VERSION ""

NS_ :

BS_:

BU_: GW MHU IPC CCU

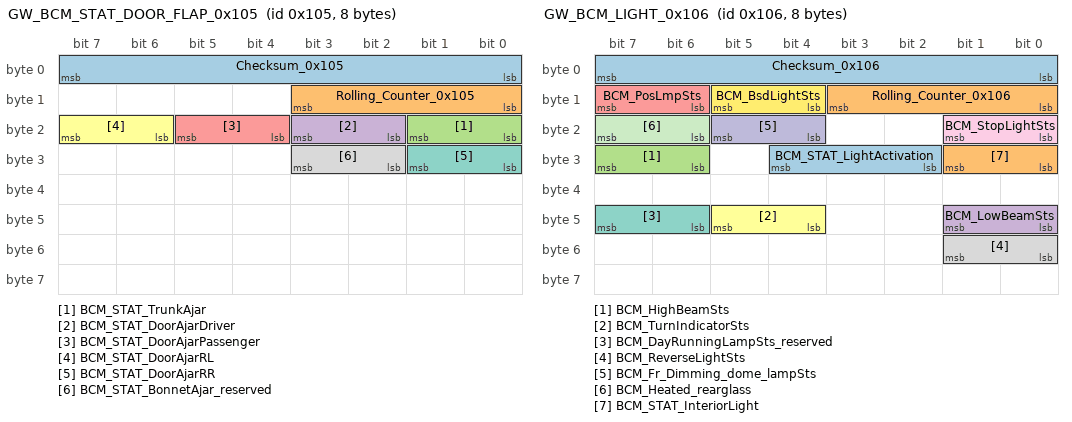
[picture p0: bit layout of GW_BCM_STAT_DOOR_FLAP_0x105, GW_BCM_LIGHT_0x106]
BO_ 261 GW_BCM_STAT_DOOR_FLAP_0x105: 8 GW
 SG_ Checksum_0x105 : 7|8@0+ (1,0) [0|255] ""  MHU,IPC
 SG_ Rolling_Counter_0x105 : 11|4@0+ (1,0) [0|15] ""  MHU,IPC
 SG_ BCM_STAT_TrunkAjar : 17|2@0+ (1,0) [0|3] "Bit"  MHU,IPC
 SG_ BCM_STAT_DoorAjarDriver : 19|2@0+ (1,0) [0|3] "Bit"  MHU,IPC
 SG_ BCM_STAT_DoorAjarPassenger : 21|2@0+ (1,0) [0|3] "Bit"  MHU,IPC
 SG_ BCM_STAT_DoorAjarRL : 23|2@0+ (1,0) [0|3] "Bit"  MHU,IPC
 SG_ BCM_STAT_DoorAjarRR : 25|2@0+ (1,0) [0|3] "Bit"  MHU,IPC
 SG_ BCM_STAT_BonnetAjar_reserved : 27|2@0+ (1,0) [0|3] "Bit"  MHU,IPC

BO_ 262 GW_BCM_LIGHT_0x106: 8 GW
 SG_ Checksum_0x106 : 7|8@0+ (1,0) [0|255] ""  MHU,IPC
 SG_ Rolling_Counter_0x106 : 11|4@0+ (1,0) [0|15] ""  MHU,IPC
 SG_ BCM_HighBeamSts : 31|2@0+ (1,0) [0|3] ""  MHU,IPC
 SG_ BCM_LowBeamSts : 41|2@0+ (1,0) [0|3] ""  MHU,IPC
 SG_ BCM_PosLmpSts : 15|2@0+ (1,0) [0|3] ""  MHU,IPC
 SG_ BCM_TurnIndicatorSts : 45|2@0+ (1,0) [0|3] ""  MHU,IPC
 SG_ BCM_DayRunningLampSts_reserved : 47|2@0+ (1,0) [0|3] ""  MHU,IPC
 SG_ BCM_ReverseLightSts : 49|2@0+ (1,0) [0|3] ""  MHU,IPC
 SG_ BCM_StopLightSts : 17|2@0+ (1,0) [0|3] ""  MHU,IPC
 SG_ BCM_Fr_Dimming_dome_lampSts : 21|2@0+ (1,0) [0|3] ""  MHU,IPC
 SG_ BCM_Heated_rearglass : 23|2@0+ (1,0) [0|3] ""  MHU
 SG_ BCM_BsdLightSts : 13|2@0+ (1,0) [0|3] ""  MHU,IPC
 SG_ BCM_STAT_LightActivation : 28|3@0+ (1,0) [0|7] ""  MHU,IPC
 SG_ BCM_STAT_InteriorLight : 25|2@0+ (1,0) [0|3] "Bit"  MHU,IPC

BO_ 266 GW_BCM_VOLTAGE_0x10a: 8 GW
 SG_ Checksum_0x10a : 7|8@0+ (1,0) [0|255] ""  MHU,IPC,CCU
 SG_ Rolling_Counter_0x10a : 11|4@0+ (1,0) [0|15] ""  MHU,IPC,CCU
 SG_ BCM_LVTop_up : 24|1@0+ (1,0) [0|1] ""  MHU
 SG_ Ubatt_Reserved : 23|14@0+ (0.001,3) [3|18] "V"  MHU,IPC,CCU

BO_ 274 GW_BCM_CLAMP_STAT_0x112: 8 GW
 SG_ Checksum_0x112 : 7|8@0+ (1,0) [0|255] ""  MHU,IPC,CCU
 SG_ Rolling_Counter_0x112 : 11|4@0+ (1,0) [0|15] ""  MHU,IPC,CCU
 SG_ STAT_Terminal : 34|3@0+ (1,0) [0|7] "Bit"  MHU,IPC,CCU
 SG_ STAT_CL30s_L_Reserved : 41|2@0+ (1,0) [0|3] "Bit"  MHU

BO_ 303 GW_BCM_TERMINAL_0x12f: 8 GW
 SG_ Checksum_0x12f : 7|8@0+ (1,0) [0|255] ""  MHU,IPC
 SG_ Rolling_Counter_0x12f : 11|4@0+ (1,0) [0|15] ""  MHU,IPC
 SG_ ST_KL_KEY_VLD : 19|4@0+ (1,0) [0|15] ""  MHU,IPC
 SG_ ST_SSP : 25|2@0+ (1,0) [0|3] ""  MHU,IPC
 SG_ BCM_IMMO_Sts : 29|2@0+ (1,0) [0|2] ""  MHU

BO_ 283 GW_BCM_Power_0x11b: 8 GW
 SG_ BCM_ACCRelayOutputSts : 3|2@0+ (1,0) [0|3] ""  MHU,IPC
 SG_ BCM_IGN1RelayOutputSts : 5|2@0+ (1,0) [0|3] ""  MHU,IPC
 SG_ BCM_ACCRelayFalutSts : 9|2@0+ (1,0) [0|3] ""  MHU,IPC
 SG_ BCM_IGN1RelayFalutSts : 11|2@0+ (1,0) [0|3] ""  MHU,IPC
 SG_ BCM_KEY_MatchSts : 15|2@0+ (1,0) [0|3] ""  MHU,IPC

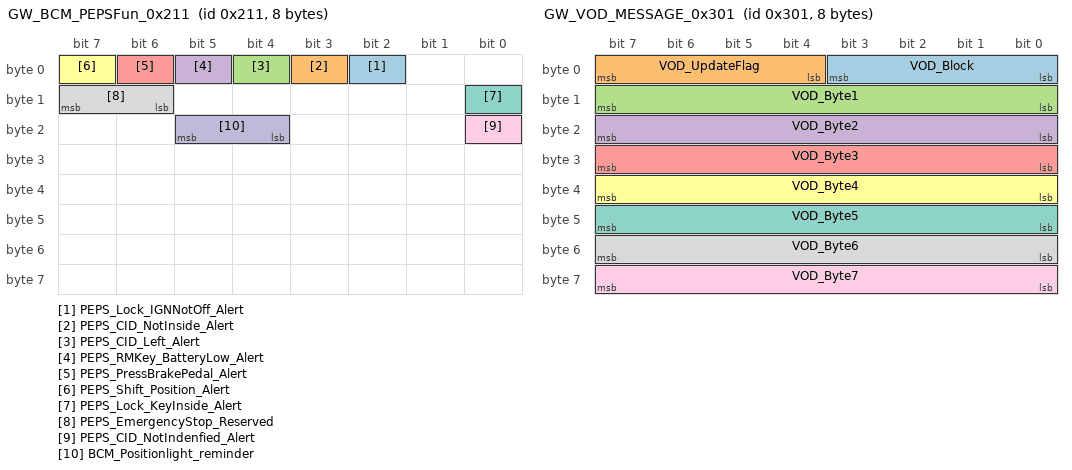
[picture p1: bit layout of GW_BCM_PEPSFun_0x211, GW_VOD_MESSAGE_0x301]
BO_ 529 GW_BCM_PEPSFun_0x211: 8 GW
 SG_ PEPS_Lock_IGNNotOff_Alert : 2|1@0+ (1,0) [0|1] ""  MHU,IPC
 SG_ PEPS_CID_NotInside_Alert : 3|1@0+ (1,0) [0|1] ""  MHU,IPC
 SG_ PEPS_CID_Left_Alert : 4|1@0+ (1,0) [0|1] ""  MHU,IPC
 SG_ PEPS_RMKey_BatteryLow_Alert : 5|1@0+ (1,0) [0|1] ""  MHU,IPC
 SG_ PEPS_PressBrakePedal_Alert : 6|1@0+ (1,0) [0|1] ""  MHU,IPC
 SG_ PEPS_Shift_Position_Alert : 7|1@0+ (1,0) [0|1] ""  MHU,IPC
 SG_ PEPS_Lock_KeyInside_Alert : 8|1@0+ (1,0) [0|1] ""  MHU,IPC
 SG_ PEPS_EmergencyStop_Reserved : 15|2@0+ (1,0) [0|3] ""  MHU,IPC
 SG_ PEPS_CID_NotIndenfied_Alert : 16|1@0+ (1,0) [0|1] ""  MHU,IPC
 SG_ BCM_Positionlight_reminder : 21|2@0+ (1,0) [0|3] ""  MHU,IPC

BO_ 270 GW_BCM_ENTRY_CONTROL_0x10e: 8 GW
 SG_ RemoteAccessKey : 7|4@0+ (1,0) [0|7] ""  MHU
 SG_ PassiveAccessTrunk : 9|2@0+ (1,0) [0|3] ""  MHU
 SG_ BCM_CurrentValid_FOB : 18|3@0+ (1,0) [0|4] ""  MHU

BO_ 769 GW_VOD_MESSAGE_0x301: 8 GW
 SG_ VOD_Block : 3|4@0+ (1,0) [0|7] ""  IPC
 SG_ VOD_UpdateFlag : 7|4@0+ (1,0) [0|7] ""  IPC
 SG_ VOD_Byte1 : 15|8@0+ (1,0) [0|255] ""  IPC
 SG_ VOD_Byte2 : 23|8@0+ (1,0) [0|255] ""  IPC
 SG_ VOD_Byte3 : 31|8@0+ (1,0) [0|255] ""  IPC
 SG_ VOD_Byte4 : 39|8@0+ (1,0) [0|255] ""  IPC
 SG_ VOD_Byte5 : 47|8@0+ (1,0) [0|255] ""  IPC
 SG_ VOD_Byte6 : 55|8@0+ (1,0) [0|255] ""  IPC
 SG_ VOD_Byte7 : 63|8@0+ (1,0) [0|255] ""  IPC

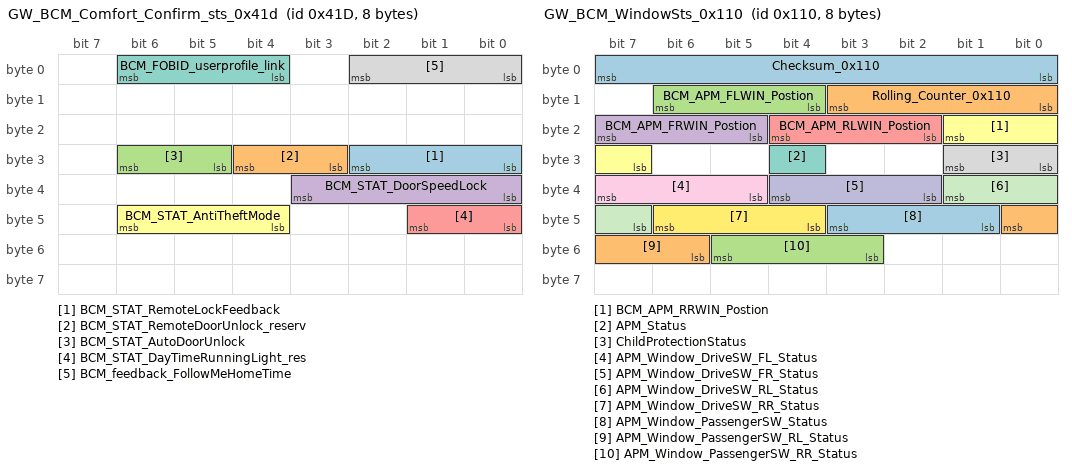
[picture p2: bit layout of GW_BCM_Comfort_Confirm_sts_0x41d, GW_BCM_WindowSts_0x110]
BO_ 1053 GW_BCM_Comfort_Confirm_sts_0x41d: 8 GW
 SG_ BCM_STAT_RemoteLockFeedback : 26|3@0+ (1,0) [0|7] ""  MHU
 SG_ BCM_STAT_RemoteDoorUnlock_reserv : 28|2@0+ (1,0) [0|3] ""  MHU
 SG_ BCM_STAT_AutoDoorUnlock : 30|2@0+ (1,0) [0|3] ""  MHU
 SG_ BCM_STAT_DoorSpeedLock : 35|4@0+ (1,0) [0|7] ""  MHU
 SG_ BCM_STAT_DayTimeRunningLight_res : 41|2@0+ (1,0) [0|3] ""  MHU
 SG_ BCM_STAT_AntiTheftMode : 46|3@0+ (1,0) [0|7] ""  MHU
 SG_ BCM_FOBID_userprofile_link : 6|3@0+ (1,0) [0|7] ""  MHU
 SG_ BCM_feedback_FollowMeHomeTime : 2|3@0+ (1,0) [0|7] ""  MHU

BO_ 263 GW_BCM_STAT_CENTRAL_LOCK_0x107: 8 GW
 SG_ Checksum_0x107 : 7|8@0+ (1,0) [0|255] "" Vector__XXX
 SG_ Rolling_Counter_0x107 : 11|4@0+ (1,0) [0|15] "" Vector__XXX
 SG_ STAT_ATWS : 20|3@0+ (1,0) [0|7] "Bit"  MHU
 SG_ STAT_DoorLockDriver : 23|2@0+ (1,0) [0|3] "Bit"  MHU

BO_ 268 GW_BCM_RemoteCtrlSts_0x10C: 8 GW
 SG_ Checksum_0x10C : 7|8@0+ (1,0) [0|255] ""  MHU
 SG_ Rolling_Counter_0x10C : 11|4@0+ (1,0) [0|15] ""  MHU
 SG_ BCM_TboxAuthStatus : 13|2@0+ (1,0) [0|2] ""  MHU
 SG_ BCM_RandomNum32bit : 39|32@0+ (1,0) [0|4294967295] ""  MHU

BO_ 272 GW_BCM_WindowSts_0x110: 8 GW
 SG_ Checksum_0x110 : 7|8@0+ (1,0) [0|255] ""  MHU
 SG_ Rolling_Counter_0x110 : 11|4@0+ (1,0) [0|14] ""  MHU
 SG_ BCM_APM_FLWIN_Postion : 14|3@0+ (1,0) [0|6] ""  MHU
 SG_ BCM_APM_FRWIN_Postion : 23|3@0+ (1,0) [0|6] ""  MHU
 SG_ BCM_APM_RLWIN_Postion : 20|3@0+ (1,0) [0|6] ""  MHU
 SG_ BCM_APM_RRWIN_Postion : 17|3@0+ (1,0) [0|6] ""  MHU
 SG_ APM_Status : 28|1@0+ (1,0) [0|1] ""  MHU
 SG_ ChildProtectionStatus : 25|2@0+ (1,0) [0|3] ""  MHU
 SG_ APM_Window_DriveSW_FL_Status : 39|3@0+ (1,0) [0|6] ""  MHU
 SG_ APM_Window_DriveSW_FR_Status : 36|3@0+ (1,0) [0|6] ""  MHU
 SG_ APM_Window_DriveSW_RL_Status : 33|3@0+ (1,0) [0|6] ""  MHU
 SG_ APM_Window_DriveSW_RR_Status : 46|3@0+ (1,0) [0|6] ""  MHU
 SG_ APM_Window_PassengerSW_Status : 43|3@0+ (1,0) [0|6] ""  MHU
 SG_ APM_Window_PassengerSW_RL_Status : 40|3@0+ (1,0) [0|6] ""  MHU
 SG_ APM_Window_PassengerSW_RR_Status : 53|3@0+ (1,0) [0|6] ""  MHU

BO_ 525 GW_BCM_ODO_0x20D: 8 GW
 SG_ Checksum_0x20D : 7|8@0+ (1,0) [0|255] ""  MHU,IPC
 SG_ Rolling_Counter_0x20D : 11|4@0+ (1,0) [0|15] ""  MHU,IPC
 SG_ BCM_ODO : 31|20@0+ (1,0) [0|999999] "km"  MHU,IPC

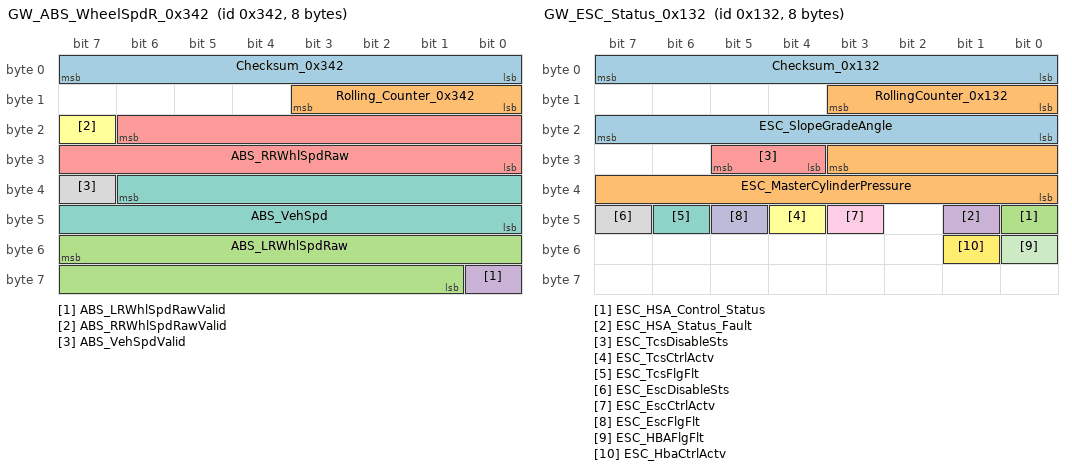
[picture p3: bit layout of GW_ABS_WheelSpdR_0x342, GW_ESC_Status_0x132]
BO_ 834 GW_ABS_WheelSpdR_0x342: 8 GW
 SG_ Checksum_0x342 : 7|8@0+ (1,0) [0|255] ""  MHU,IPC,CCU
 SG_ Rolling_Counter_0x342 : 11|4@0+ (1,0) [0|15] ""  MHU,IPC,CCU
 SG_ ABS_LRWhlSpdRaw : 55|15@0+ (0.01,0) [0|327.66] "kph" Vector__XXX
 SG_ ABS_LRWhlSpdRawValid : 56|1@0+ (1,0) [0|1] "" Vector__XXX
 SG_ ABS_RRWhlSpdRaw : 22|15@0+ (0.01,0) [0|327.66] "kph" Vector__XXX
 SG_ ABS_RRWhlSpdRawValid : 23|1@0+ (1,0) [0|1] "" Vector__XXX
 SG_ ABS_VehSpd : 38|15@0+ (0.01,0) [0|327.66] "kph"  MHU,IPC,CCU
 SG_ ABS_VehSpdValid : 39|1@0+ (1,0) [0|1] ""  MHU,IPC,CCU

BO_ 306 GW_ESC_Status_0x132: 8 GW
 SG_ Checksum_0x132 : 7|8@0+ (1,0) [0|255] ""  MHU,IPC
 SG_ RollingCounter_0x132 : 11|4@0+ (1,0) [0|15] ""  MHU,IPC
 SG_ ESC_HSA_Control_Status : 40|1@0+ (1,0) [0|1] ""  MHU,IPC
 SG_ ESC_HSA_Status_Fault : 41|1@0+ (1,0) [0|1] ""  MHU,IPC
 SG_ ESC_TcsDisableSts : 29|2@0+ (1,0) [0|3] ""  MHU,IPC
 SG_ ESC_TcsCtrlActv : 44|1@0+ (1,0) [0|1] ""  MHU,IPC
 SG_ ESC_TcsFlgFlt : 46|1@0+ (1,0) [0|1] ""  MHU,IPC
 SG_ ESC_EscDisableSts : 47|1@0+ (1,0) [0|1] ""  MHU,IPC
 SG_ ESC_EscCtrlActv : 43|1@0+ (1,0) [0|1] ""  MHU,IPC
 SG_ ESC_EscFlgFlt : 45|1@0+ (1,0) [0|1] ""  MHU,IPC
 SG_ ESC_HBAFlgFlt : 48|1@0+ (1,0) [0|1] ""  MHU,IPC
 SG_ ESC_HbaCtrlActv : 49|1@0+ (1,0) [0|1] ""  MHU,IPC
 SG_ ESC_SlopeGradeAngle : 23|8@0+ (0.35433,-45) [-45|45] "deg"  MHU,IPC
 SG_ ESC_MasterCylinderPressure : 27|12@0+ (0.1,-100) [-100|309.4] "bar"  MHU,IPC

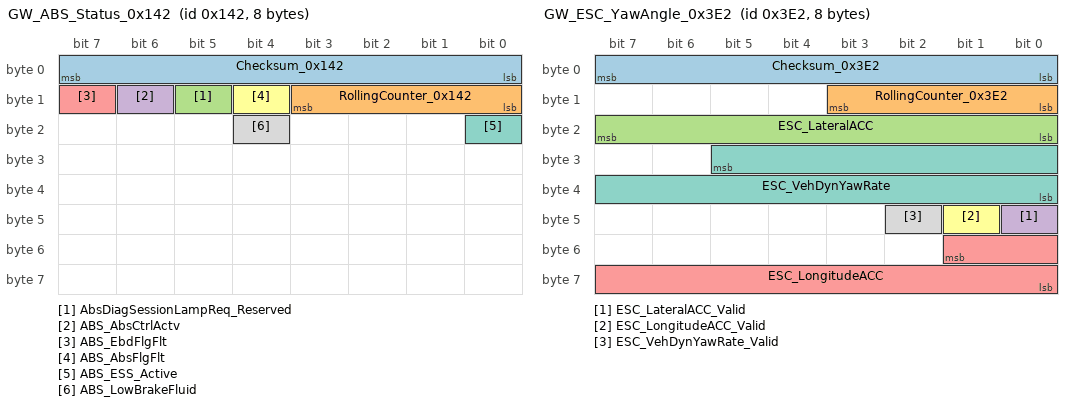
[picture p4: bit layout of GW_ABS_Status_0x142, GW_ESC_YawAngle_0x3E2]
BO_ 322 GW_ABS_Status_0x142: 8 GW
 SG_ Checksum_0x142 : 7|8@0+ (1,0) [0|255] ""  MHU,IPC
 SG_ RollingCounter_0x142 : 11|4@0+ (1,0) [0|15] ""  MHU,IPC
 SG_ AbsDiagSessionLampReq_Reserved : 13|1@0+ (1,0) [0|1] ""  MHU,IPC
 SG_ ABS_AbsCtrlActv : 14|1@0+ (1,0) [0|1] ""  MHU,IPC
 SG_ ABS_EbdFlgFlt : 15|1@0+ (1,0) [0|1] ""  MHU,IPC
 SG_ ABS_AbsFlgFlt : 12|1@0+ (1,0) [0|1] ""  MHU,IPC
 SG_ ABS_ESS_Active : 16|1@0+ (1,0) [0|1] ""  MHU,IPC
 SG_ ABS_LowBrakeFluid : 20|1@0+ (1,0) [0|1] ""  MHU,IPC

BO_ 994 GW_ESC_YawAngle_0x3E2: 8 GW
 SG_ Checksum_0x3E2 : 7|8@0+ (1,0) [0|255] ""  MHU
 SG_ RollingCounter_0x3E2 : 11|4@0+ (1,0) [0|15] ""  MHU
 SG_ ESC_LateralACC : 23|8@0+ (0.01587,-2.0193) [-2.0193|2.0193] "g"  MHU
 SG_ ESC_LateralACC_Valid : 40|1@0+ (1,0) [0|1] ""  MHU
 SG_ ESC_LongitudeACC : 49|10@0+ (0.00392,-1.9929) [-1.9929|1.9929] "g"  MHU
 SG_ ESC_LongitudeACC_Valid : 41|1@0+ (1,0) [0|1] ""  MHU
 SG_ ESC_VehDynYawRate : 29|14@0+ (0.03125,-256) [-256|255.96875] "deg/s"  MHU
 SG_ ESC_VehDynYawRate_Valid : 42|1@0+ (1,0) [0|1] ""  MHU

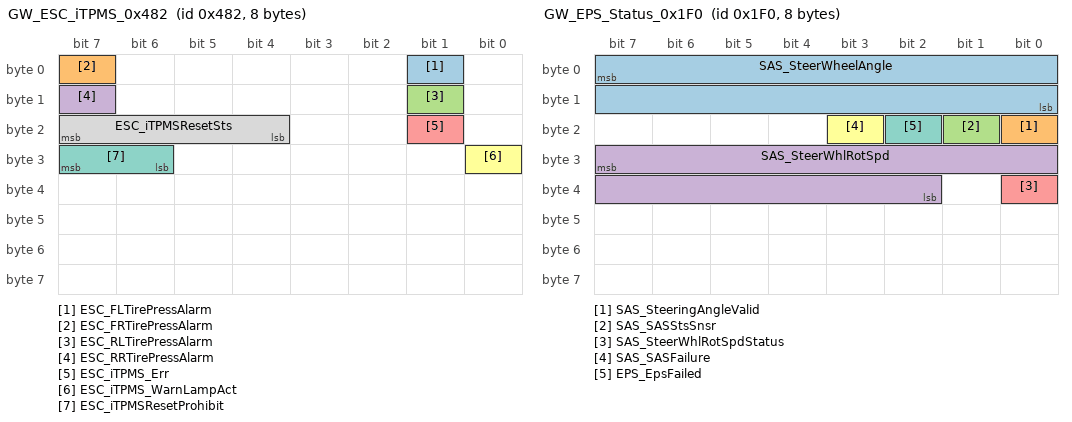
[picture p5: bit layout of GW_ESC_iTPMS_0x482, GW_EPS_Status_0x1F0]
BO_ 1154 GW_ESC_iTPMS_0x482: 8 GW
 SG_ ESC_FLTirePressAlarm : 1|1@0+ (1,0) [0|1] ""  MHU,IPC
 SG_ ESC_FRTirePressAlarm : 7|1@0+ (1,0) [0|1] ""  MHU,IPC
 SG_ ESC_RLTirePressAlarm : 9|1@0+ (1,0) [0|1] ""  MHU,IPC
 SG_ ESC_RRTirePressAlarm : 15|1@0+ (1,0) [0|1] ""  MHU,IPC
 SG_ ESC_iTPMS_Err : 17|1@0+ (1,0) [0|1] ""  MHU,IPC
 SG_ ESC_iTPMS_WarnLampAct : 24|1@0+ (1,0) [0|1] ""  MHU,IPC
 SG_ ESC_iTPMSResetProhibit : 31|2@0+ (1,0) [0|3] ""  MHU,IPC
 SG_ ESC_iTPMSResetSts : 23|4@0+ (1,0) [0|15] ""  MHU,IPC

BO_ 496 GW_EPS_Status_0x1F0: 8 GW
 SG_ SAS_SteerWheelAngle : 7|16@0+ (0.0238,-780) [-780|779.7] "deg"  MHU
 SG_ SAS_SteeringAngleValid : 16|1@0+ (1,0) [0|1] ""  MHU
 SG_ SAS_SASStsSnsr : 17|1@0+ (1,0) [0|1] ""  MHU
 SG_ SAS_SteerWhlRotSpd : 31|14@0+ (0.125,-1024) [-1024|1023.75] "degs" Vector__XXX
 SG_ SAS_SteerWhlRotSpdStatus : 32|1@0+ (1,0) [0|1] "" Vector__XXX
 SG_ SAS_SASFailure : 19|1@0+ (1,0) [0|1] ""  MHU,IPC
 SG_ EPS_EpsFailed : 18|1@0+ (1,0) [0|1] ""  MHU,IPC

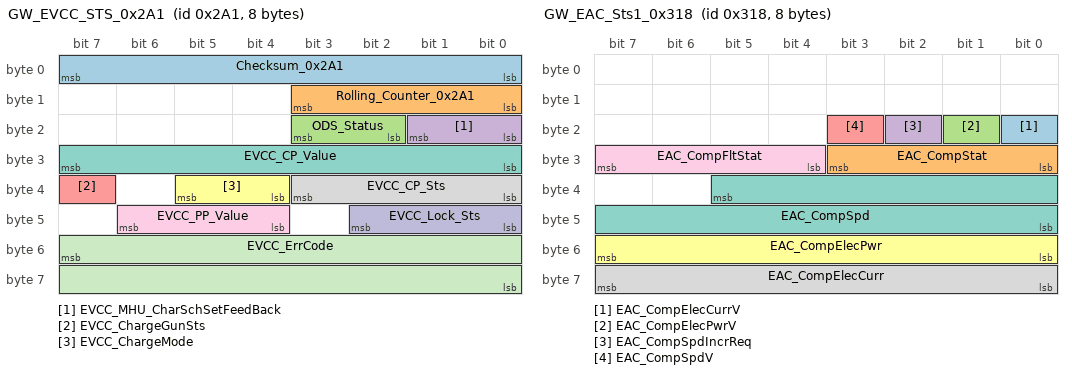
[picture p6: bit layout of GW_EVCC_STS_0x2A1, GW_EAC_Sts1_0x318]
BO_ 673 GW_EVCC_STS_0x2A1: 8 GW
 SG_ Checksum_0x2A1 : 7|8@0+ (1,0) [0|255] ""  MHU,IPC
 SG_ Rolling_Counter_0x2A1 : 11|4@0+ (1,0) [0|15] ""  MHU,IPC
 SG_ ODS_Status : 19|2@0+ (1,0) [0|3] ""  MHU
 SG_ EVCC_MHU_CharSchSetFeedBack : 17|2@0+ (1,0) [0|3] ""  MHU
 SG_ EVCC_ChargeGunSts : 39|1@0+ (1,0) [0|1] ""  MHU,IPC
 SG_ EVCC_ChargeMode : 37|2@0+ (1,0) [0|3] ""  MHU,IPC
 SG_ EVCC_CP_Value : 31|8@0+ (1,0) [0|100] "%"  MHU
 SG_ EVCC_CP_Sts : 35|4@0+ (1,0) [0|15] ""  MHU
 SG_ EVCC_PP_Value : 46|3@0+ (1,0) [0|7] ""  MHU
 SG_ EVCC_Lock_Sts : 42|3@0+ (1,0) [0|7] ""  MHU
 SG_ EVCC_ErrCode : 55|16@0+ (1,0) [0|65535] ""  MHU,IPC

BO_ 792 GW_EAC_Sts1_0x318: 8 GW
 SG_ EAC_CompElecCurrV : 16|1@0+ (1,0) [0|1] "" Vector__XXX
 SG_ EAC_CompStat : 27|4@0+ (1,0) [0|15] ""  CCU
 SG_ EAC_CompElecPwrV : 17|1@0+ (1,0) [0|1] "" Vector__XXX
 SG_ EAC_CompSpdIncrReq : 18|1@0+ (1,0) [0|1] "" Vector__XXX
 SG_ EAC_CompSpdV : 19|1@0+ (1,0) [0|1] ""  CCU
 SG_ EAC_CompElecPwr : 55|8@0+ (40,0) [0|10200] "W"  CCU
 SG_ EAC_CompSpd : 37|14@0+ (1,0) [0|16383] "rpm"  CCU
 SG_ EAC_CompElecCurr : 63|8@0+ (0.2,0) [0|51] "A" Vector__XXX
 SG_ EAC_CompFltStat : 31|4@0+ (1,0) [0|15] ""  CCU

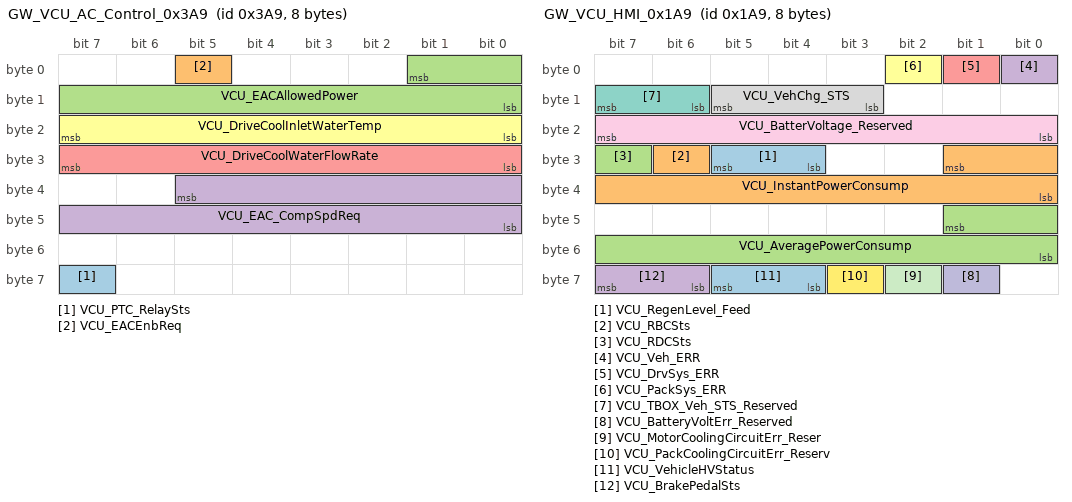
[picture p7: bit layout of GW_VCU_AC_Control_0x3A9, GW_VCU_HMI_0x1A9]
BO_ 937 GW_VCU_AC_Control_0x3A9: 8 GW
 SG_ VCU_PTC_RelaySts : 63|1@0+ (1,0) [0|1] ""  MHU,CCU
 SG_ VCU_EACEnbReq : 5|1@0+ (1,0) [0|1] ""  MHU
 SG_ VCU_EACAllowedPower : 1|10@0+ (0.1,0) [0|100] "KW"  MHU
 SG_ VCU_EAC_CompSpdReq : 37|14@0+ (1,0) [0|16383] "rpm"  MHU
 SG_ VCU_DriveCoolWaterFlowRate : 31|8@0+ (0.1,0) [0|25.4] "L/min"  MHU
 SG_ VCU_DriveCoolInletWaterTemp : 23|8@0+ (1,-40) [-40|215] "degree"  MHU

BO_ 889 GW_VCU_Sts2_0x379: 8 GW
 SG_ VCU_DriveCoolWaterPumpSts : 2|3@0+ (1,0) [0|5] ""  MHU
 SG_ VCU_DriveCoolWaterDuty : 14|7@0+ (1,0) [0|100] "%" Vector__XXX
 SG_ VCU_BatteryWaterPumpSts_reserved : 30|3@0+ (1,0) [0|7] ""  MHU
 SG_ VCU_BatteryWaterPumpDuty_reserve : 22|7@0+ (1,0) [0|100] "%" Vector__XXX
 SG_ VCU_DriveMode : 5|3@0+ (1,0) [0|7] ""  MHU,IPC
 SG_ VCU_ActualGear : 26|3@0+ (1,0) [0|7] ""  MHU,IPC
 SG_ VCU_ACTGearValid : 27|1@0+ (1,0) [0|1] ""  MHU,IPC
 SG_ VCU_AccPedal1OutRange : 31|1@0+ (1,0) [0|1] ""  MHU
 SG_ VCU_AccPedal2OutRange : 33|1@0+ (1,0) [0|1] ""  MHU
 SG_ VCU_BrkPedal1OutRange : 35|1@0+ (1,0) [0|1] ""  MHU
 SG_ VCU_BrkPedal2OutRange : 37|1@0+ (1,0) [0|1] "" Vector__XXX
 SG_ VCU_BrkPedalPct : 47|8@0+ (0.4,0) [0|100] "%"  MHU
 SG_ VCU_AccPedalPosition : 55|8@0+ (0.4,0) [0|100] "%"  MHU
 SG_ VCU_AccPedalPositionValid : 63|1@0+ (1,0) [0|1] "" Vector__XXX
 SG_ VCU_SocDisplay_EST : 62|7@0+ (1,0) [0|100] "%"  MHU,IPC
 SG_ VCU_PowerLimit : 15|1@0+ (1,0) [0|1] ""  MHU,IPC
 SG_ VCU_CruiseCtrlSts : 39|2@0+ (1,0) [0|3] ""  IPC
 SG_ VCU_LowSOC_ERR : 23|1@0+ (1,0) [0|1] ""  MHU,IPC

BO_ 441 GW_VCU_HMI2_0x1B9: 8 GW
 SG_ VCU_MCUConsumepower : 15|9@0+ (0.1,0) [0|50] "kw/h"  MHU
 SG_ VCU_EACConsumepower : 16|9@0+ (0.1,0) [0|50] "kw/h"  MHU
 SG_ VCU_DCDCConsumepower : 32|9@0+ (0.1,0) [0|50] "kw/h"  MHU
 SG_ VCU_PTCConsumepower : 48|9@0+ (0.1,0) [0|50] "kw/h" Vector__XXX

BO_ 425 GW_VCU_HMI_0x1A9: 8 GW
 SG_ VCU_RegenLevel_Feed : 29|2@0+ (1,0) [0|3] ""  MHU
 SG_ VCU_RBCSts : 30|1@0+ (1,0) [0|1] ""  MHU
 SG_ VCU_RDCSts : 31|1@0+ (1,0) [0|1] ""  MHU
 SG_ VCU_Veh_ERR : 0|1@0+ (1,0) [0|1] ""  MHU,IPC
 SG_ VCU_DrvSys_ERR : 1|1@0+ (1,0) [0|1] ""  MHU,IPC
 SG_ VCU_PackSys_ERR : 2|1@0+ (1,0) [0|1] ""  MHU,IPC
 SG_ VCU_TBOX_Veh_STS_Reserved : 15|2@0+ (1,0) [0|3] "" Vector__XXX
 SG_ VCU_VehChg_STS : 13|3@0+ (1,0) [0|7] ""  MHU,IPC
 SG_ VCU_BatterVoltage_Reserved : 23|8@0+ (0.07,0) [0|17.85] "V"  MHU,IPC
 SG_ VCU_BatteryVoltErr_Reserved : 57|1@0+ (1,0) [0|1] "" Vector__XXX
 SG_ VCU_MotorCoolingCircuitErr_Reser : 58|1@0+ (1,0) [0|1] "" Vector__XXX
 SG_ VCU_PackCoolingCircuitErr_Reserv : 59|1@0+ (1,0) [0|1] "" Vector__XXX
 SG_ VCU_VehicleHVStatus : 61|2@0+ (1,0) [0|3] ""  MHU,IPC,CCU
 SG_ VCU_InstantPowerConsump : 25|10@0+ (0.1,0) [0|100] "kwh/100km"  MHU,IPC
 SG_ VCU_AveragePowerConsump : 41|10@0+ (0.1,0) [0|100] "kwh/100km"  MHU,IPC
 SG_ VCU_BrakePedalSts : 63|2@0+ (1,0) [0|3] ""  MHU,IPC

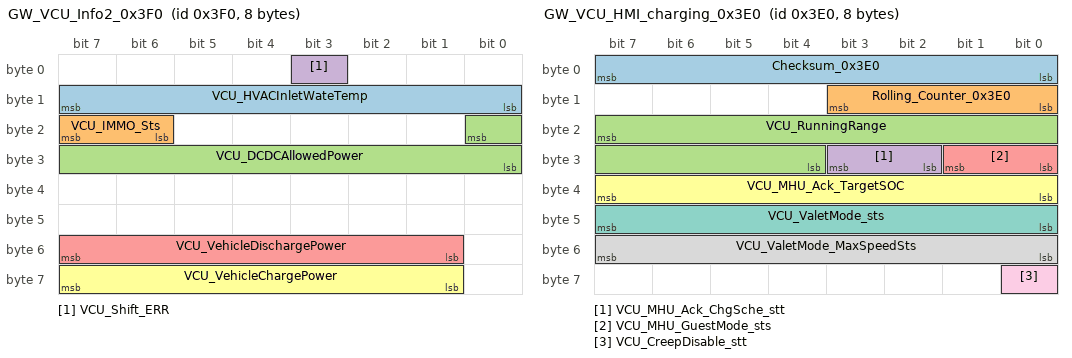
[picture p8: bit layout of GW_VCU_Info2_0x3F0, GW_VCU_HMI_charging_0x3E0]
BO_ 1008 GW_VCU_Info2_0x3F0: 8 GW
 SG_ VCU_HVACInletWateTemp : 15|8@0+ (1,-40) [-40|215] "degree"  MHU,CCU
 SG_ VCU_IMMO_Sts : 23|2@0+ (1,0) [0|2] ""  MHU,IPC
 SG_ VCU_DCDCAllowedPower : 16|9@0+ (0.1,0) [0|50] "KW"  MHU
 SG_ VCU_Shift_ERR : 3|1@0+ (1,0) [0|1] ""  MHU,IPC
 SG_ VCU_VehicleDischargePower : 55|7@0+ (1,0) [0|100] "%"  MHU,IPC
 SG_ VCU_VehicleChargePower : 63|7@0+ (1,0) [0|100] "%"  MHU,IPC

BO_ 992 GW_VCU_HMI_charging_0x3E0: 8 GW
 SG_ Checksum_0x3E0 : 7|8@0+ (1,0) [0|255] ""  MHU
 SG_ Rolling_Counter_0x3E0 : 11|4@0+ (1,0) [0|15] ""  MHU
 SG_ VCU_RunningRange : 23|12@0+ (0.5,0) [0|2047] "km"  MHU
 SG_ VCU_MHU_Ack_ChgSche_stt : 27|2@0+ (1,0) [0|3] ""  MHU
 SG_ VCU_MHU_GuestMode_sts : 25|2@0+ (1,0) [0|3] ""  MHU
 SG_ VCU_MHU_Ack_TargetSOC : 39|8@0+ (1,0) [0|100] "%"  MHU,IPC
 SG_ VCU_ValetMode_sts : 47|8@0+ (1,0) [0|255] ""  MHU
 SG_ VCU_ValetMode_MaxSpeedSts : 55|8@0+ (1,0) [0|255] "kph"  MHU
 SG_ VCU_CreepDisable_stt : 56|1@0+ (1,0) [0|1] ""  MHU

BO_ 745 GW_VCU_Mileage_0x2E9: 8 GW
 SG_ Checksum_0x2E9 : 7|8@0+ (1,0) [0|255] ""  MHU,IPC
 SG_ Rolling_Counter_0x2E9 : 11|4@0+ (1,0) [0|15] ""  MHU,IPC
 SG_ VCU_RemainingMileage : 23|32@0+ (0.1,0) [0|1000] "KM"  MHU,IPC
 SG_ VCU_SetCruiseSpd : 55|8@0+ (1,0) [0|200] "km/h"  IPC

BO_ 534 GW_BMS_ChgParamReq_0x216: 8 GW
 SG_ Checksum_0x216 : 7|8@0+ (1,0) [0|255] ""  MHU
 SG_ Rolling_Counter_0x216 : 11|4@0+ (1,0) [0|15] ""  MHU
 SG_ BMS_RemainChargeTime : 21|14@0+ (1,0) [0|16383] "min"  MHU,IPC
 SG_ BMS_ChgVoltage_REQ : 37|14@0+ (0.1,0) [0|800] "V"  MHU
 SG_ BMS_ChgCurrent_REQ : 55|16@0+ (0.1,0) [0|1500] "A"  MHU

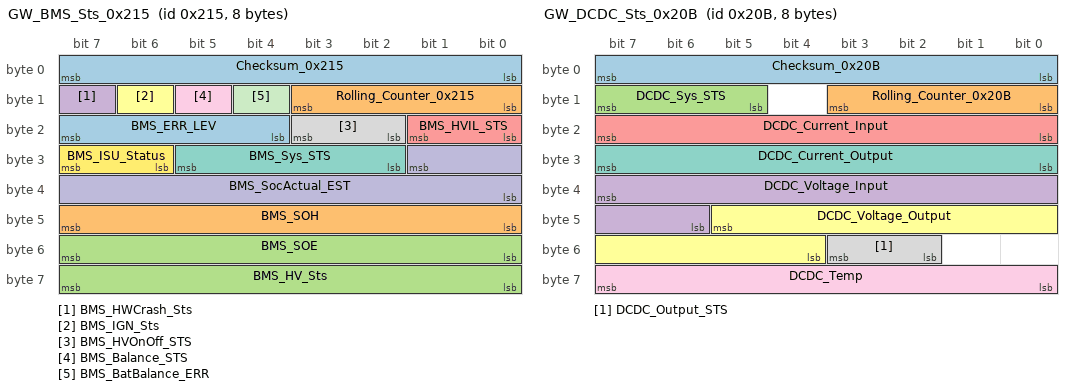
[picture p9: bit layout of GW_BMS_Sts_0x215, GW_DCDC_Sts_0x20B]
BO_ 533 GW_BMS_Sts_0x215: 8 GW
 SG_ Checksum_0x215 : 7|8@0+ (1,0) [0|255] ""  MHU,IPC,CCU
 SG_ Rolling_Counter_0x215 : 11|4@0+ (1,0) [0|15] ""  MHU,IPC,CCU
 SG_ BMS_SOE : 55|8@0+ (0.5,0) [0|100] "%" Vector__XXX
 SG_ BMS_HWCrash_Sts : 15|1@0+ (1,0) [0|1] "" Vector__XXX
 SG_ BMS_HVIL_STS : 17|2@0+ (1,0) [0|3] ""  MHU,IPC
 SG_ BMS_IGN_Sts : 14|1@0+ (1,0) [0|1] ""  MHU
 SG_ BMS_Sys_STS : 29|4@0+ (1,0) [0|15] "" Vector__XXX
 SG_ BMS_HVOnOff_STS : 19|2@0+ (1,0) [0|3] ""  MHU,IPC,CCU
 SG_ BMS_Balance_STS : 13|1@0+ (1,0) [0|1] "" Vector__XXX
 SG_ BMS_SocActual_EST : 25|10@0+ (0.1,0) [0|100] "percent"  MHU
 SG_ BMS_BatBalance_ERR : 12|1@0+ (1,0) [0|1] "" Vector__XXX
 SG_ BMS_ISU_Status : 31|2@0+ (1,0) [0|3] ""  MHU,IPC
 SG_ BMS_ERR_LEV : 23|4@0+ (1,0) [0|15] ""  MHU
 SG_ BMS_SOH : 47|8@0+ (0.5,0) [0|100] "%"  MHU
 SG_ BMS_HV_Sts : 63|8@0+ (1,0) [0|255] ""  MHU,IPC

BO_ 1171 GW_BMS_WarnMsg_0x493: 8 GW
 SG_ BMS_DischargeCurrent_Limited : 16|1@0+ (1,0) [0|1] ""  MHU,IPC
 SG_ BMS_Warning_Flag_Reserved_07 : 17|1@0+ (1,0) [0|1] ""  MHU,IPC
 SG_ BMS_Warning_Flag_Reserved_11 : 47|8@0+ (1,0) [0|255] ""  MHU,IPC
 SG_ BMS_Warning_Flag_Reserved_10 : 39|8@0+ (1,0) [0|255] ""  MHU,IPC
 SG_ BMS_Warning_Flag_Reserved_09 : 31|8@0+ (1,0) [0|255] ""  MHU,IPC
 SG_ BMS_Warning_Flag_Reserved_13 : 63|8@0+ (1,0) [0|255] ""  MHU,IPC
 SG_ BMS_Warning_Flag_Reserved_12 : 55|8@0+ (1,0) [0|255] ""  MHU,IPC
 SG_ BMS_Warning_Flag_Reserved_06 : 18|1@0+ (1,0) [0|1] ""  MHU,IPC
 SG_ BMS_Warning_Flag_Reserved_05 : 19|1@0+ (1,0) [0|1] ""  MHU,IPC
 SG_ BMS_Warning_Flag_Reserved_04 : 20|1@0+ (1,0) [0|1] ""  MHU,IPC
 SG_ BMS_MalfunctionSts : 21|1@0+ (1,0) [0|1] ""  MHU,IPC
 SG_ BMS_LowBattery : 23|2@0+ (1,0) [0|3] ""  MHU,IPC
 SG_ BMS_BatteryReplacement : 15|1@0+ (1,0) [0|1] ""  MHU,IPC
 SG_ BMS_PackTempSts : 13|2@0+ (1,0) [0|3] ""  MHU,IPC
 SG_ BMS_ThermalRunaway : 14|1@0+ (1,0) [0|1] ""  MHU,IPC
 SG_ Rolling_Counter_0x493 : 11|4@0+ (1,0) [0|15] ""  MHU,IPC
 SG_ Checksum_0x493 : 7|8@0+ (1,0) [0|255] ""  MHU,IPC

BO_ 372 GW_BMS_CurMeas_0x174: 8 GW
 SG_ Checksum_0x174 : 7|8@0+ (1,0) [0|255] ""  MHU,IPC
 SG_ Rolling_Counter_0x174 : 11|4@0+ (1,0) [0|15] ""  MHU,IPC
 SG_ BMS_PackCur_MEAS : 23|16@0+ (0.1,-3276.8) [-3276.8|3276.7] "A"  MHU,IPC

BO_ 374 GW_BMS_HVMeas1_0x176: 8 GW
 SG_ Checksum_0x176 : 7|8@0+ (1,0) [0|255] ""  MHU,IPC
 SG_ Rolling_Counter_0x176 : 11|4@0+ (1,0) [0|15] ""  MHU,IPC
 SG_ BMS_HVLinkVol_MEAS : 39|16@0+ (0.1,0) [0|800] "V" Vector__XXX
 SG_ BMS_HVPackVol_MEAS : 23|16@0+ (0.1,0) [0|800] "V"  MHU,IPC

BO_ 523 GW_DCDC_Sts_0x20B: 8 GW
 SG_ Checksum_0x20B : 7|8@0+ (1,0) [0|255] ""  MHU,IPC
 SG_ Rolling_Counter_0x20B : 11|4@0+ (1,0) [0|15] ""  MHU,IPC
 SG_ DCDC_Sys_STS : 15|3@0+ (1,0) [0|7] ""  MHU
 SG_ DCDC_Voltage_Input : 39|10@0+ (1,0) [0|1000] "V" Vector__XXX
 SG_ DCDC_Current_Input : 23|8@0+ (0.1,0) [0|25.5] "A" Vector__XXX
 SG_ DCDC_Voltage_Output : 45|10@0+ (1,0) [0|1000] "V" Vector__XXX
 SG_ DCDC_Current_Output : 31|8@0+ (1,0) [0|255] "A" Vector__XXX
 SG_ DCDC_Output_STS : 51|2@0+ (1,0) [0|3] ""  MHU,IPC
 SG_ DCDC_Temp : 63|8@0+ (1,-40) [-40|215] "Centigrade" Vector__XXX

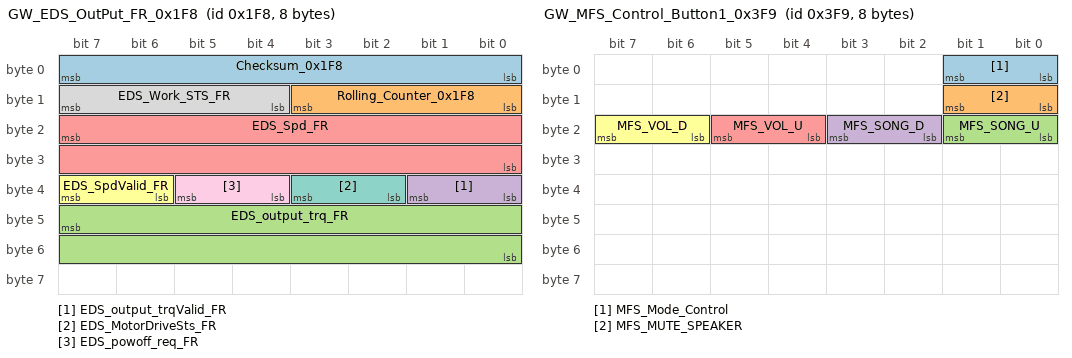
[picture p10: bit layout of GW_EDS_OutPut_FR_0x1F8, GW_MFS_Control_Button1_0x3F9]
BO_ 504 GW_EDS_OutPut_FR_0x1F8: 8 GW
 SG_ Checksum_0x1F8 : 7|8@0+ (1,0) [0|255] ""  MHU
 SG_ Rolling_Counter_0x1F8 : 11|4@0+ (1,0) [0|15] ""  MHU
 SG_ EDS_output_trq_FR : 47|16@0+ (1,-2000) [-2000|2000] "Nm"  MHU
 SG_ EDS_output_trqValid_FR : 33|2@0+ (1,0) [0|1] ""  MHU
 SG_ EDS_Spd_FR : 23|16@0+ (1,-20000) [-20000|20000] "rpm"  MHU
 SG_ EDS_SpdValid_FR : 39|2@0+ (1,0) [0|1] ""  MHU
 SG_ EDS_MotorDriveSts_FR : 35|2@0+ (1,0) [0|3] ""  MHU
 SG_ EDS_Work_STS_FR : 15|4@0+ (1,0) [0|15] ""  MHU
 SG_ EDS_powoff_req_FR : 37|2@0+ (1,0) [0|1] ""  MHU

BO_ 1015 GW_MFS_Control_Button_0x3F7: 8 GW
 SG_ MFS_OK_Control : 7|3@0+ (1,0) [0|7] "Bit"  MHU,IPC
 SG_ MFS_SourseControl : 4|3@0+ (1,0) [0|7] "Bit"  MHU
 SG_ MFS_VoiceRecognitionOn_Off : 15|3@0+ (1,0) [0|7] "Bit"  MHU
 SG_ MFS_TelephoneCall_EndCall : 12|3@0+ (1,0) [0|7] "Bit"  MHU
 SG_ MFS_DownControl : 23|3@0+ (1,0) [0|7] "Bit"  MHU,IPC
 SG_ MFS_UpControl : 20|3@0+ (1,0) [0|7] "Bit"  MHU,IPC
 SG_ MFS_RightControl : 31|3@0+ (1,0) [0|7] "Bit"  MHU,IPC
 SG_ MFS_LeftControl : 28|3@0+ (1,0) [0|7] "Bit"  MHU,IPC
 SG_ MFS_CruiseOn_Off : 39|3@0+ (1,0) [0|7] "Bit"  IPC
 SG_ MFS_Failure : 36|1@0+ (1,0) [0|1] "Bit"  MHU,IPC
 SG_ MFS_ISAControl : 35|2@0+ (1,0) [0|3] "Bit" Vector__XXX
 SG_ MFS_LKAControl : 33|2@0+ (1,0) [0|3] "Bit" Vector__XXX
 SG_ MFS_CruiseGapDecrease : 47|3@0+ (1,0) [0|7] "Bit" Vector__XXX
 SG_ MFS_CruiseSpeedDecrease : 44|3@0+ (1,0) [0|7] "Bit" Vector__XXX
 SG_ MFS_CruiseSpeedIncrease : 55|3@0+ (1,0) [0|7] "Bit" Vector__XXX
 SG_ MFS_CruiseCancel : 52|2@0+ (1,0) [0|3] "Bit" Vector__XXX
 SG_ MFS_CruiseGapIncrease : 50|3@0+ (1,0) [0|7] "Bit" Vector__XXX

BO_ 1017 GW_MFS_Control_Button1_0x3F9: 8 GW
 SG_ MFS_Mode_Control : 1|2@0+ (1,0) [0|3] ""  MHU
 SG_ MFS_MUTE_SPEAKER : 9|2@0+ (1,0) [0|3] ""  MHU
 SG_ MFS_SONG_U : 17|2@0+ (1,0) [0|3] ""  MHU
 SG_ MFS_SONG_D : 19|2@0+ (1,0) [0|3] ""  MHU
 SG_ MFS_VOL_U : 21|2@0+ (1,0) [0|3] ""  MHU
 SG_ MFS_VOL_D : 23|2@0+ (1,0) [0|3] ""  MHU

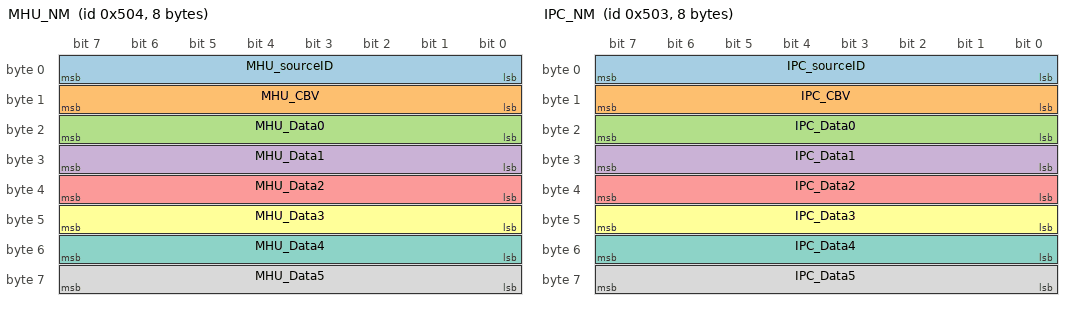
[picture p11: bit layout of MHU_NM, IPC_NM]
BO_ 1284 MHU_NM: 8 MHU
 SG_ MHU_sourceID : 7|8@0+ (1,0) [0|255] ""  GW,IPC,CCU
 SG_ MHU_CBV : 15|8@0+ (1,0) [0|255] ""  GW,IPC,CCU
 SG_ MHU_Data0 : 23|8@0+ (1,0) [0|255] ""  GW,IPC,CCU
 SG_ MHU_Data1 : 31|8@0+ (1,0) [0|255] ""  GW,IPC,CCU
 SG_ MHU_Data2 : 39|8@0+ (1,0) [0|255] ""  GW,IPC,CCU
 SG_ MHU_Data3 : 47|8@0+ (1,0) [0|255] ""  GW,IPC,CCU
 SG_ MHU_Data4 : 55|8@0+ (1,0) [0|255] ""  GW,IPC,CCU
 SG_ MHU_Data5 : 63|8@0+ (1,0) [0|255] ""  GW,IPC,CCU

BO_ 1283 IPC_NM: 8 IPC
 SG_ IPC_sourceID : 7|8@0+ (1,0) [0|255] ""  GW,MHU,CCU
 SG_ IPC_CBV : 15|8@0+ (1,0) [0|255] ""  GW,MHU,CCU
 SG_ IPC_Data0 : 23|8@0+ (1,0) [0|255] ""  GW,MHU,CCU
 SG_ IPC_Data1 : 31|8@0+ (1,0) [0|255] ""  GW,MHU,CCU
 SG_ IPC_Data2 : 39|8@0+ (1,0) [0|255] ""  GW,MHU,CCU
 SG_ IPC_Data3 : 47|8@0+ (1,0) [0|255] ""  GW,MHU,CCU
 SG_ IPC_Data4 : 55|8@0+ (1,0) [0|255] ""  GW,MHU,CCU
 SG_ IPC_Data5 : 63|8@0+ (1,0) [0|255] ""  GW,MHU,CCU

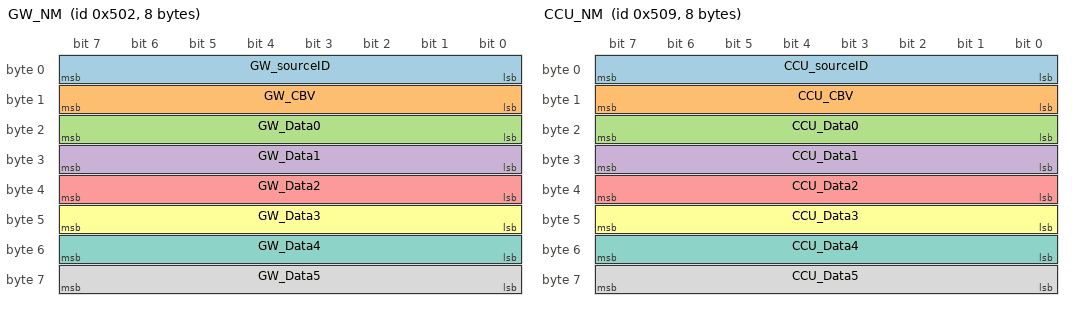
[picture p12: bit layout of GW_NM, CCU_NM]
BO_ 1282 GW_NM: 8 GW
 SG_ GW_sourceID : 7|8@0+ (1,0) [0|255] ""  MHU,IPC,CCU
 SG_ GW_CBV : 15|8@0+ (1,0) [0|255] ""  MHU,IPC,CCU
 SG_ GW_Data0 : 23|8@0+ (1,0) [0|255] ""  MHU,IPC,CCU
 SG_ GW_Data1 : 31|8@0+ (1,0) [0|255] ""  MHU,IPC,CCU
 SG_ GW_Data2 : 39|8@0+ (1,0) [0|255] ""  MHU,IPC,CCU
 SG_ GW_Data3 : 47|8@0+ (1,0) [0|255] ""  MHU,IPC,CCU
 SG_ GW_Data4 : 55|8@0+ (1,0) [0|255] ""  MHU,IPC,CCU
 SG_ GW_Data5 : 63|8@0+ (1,0) [0|255] ""  MHU,IPC,CCU

BO_ 1289 CCU_NM: 8 CCU
 SG_ CCU_sourceID : 7|8@0+ (1,0) [0|255] ""  GW,MHU,IPC
 SG_ CCU_CBV : 15|8@0+ (1,0) [0|255] ""  GW,MHU,IPC
 SG_ CCU_Data0 : 23|8@0+ (1,0) [0|255] ""  GW,MHU,IPC
 SG_ CCU_Data1 : 31|8@0+ (1,0) [0|255] ""  GW,MHU,IPC
 SG_ CCU_Data2 : 39|8@0+ (1,0) [0|255] ""  GW,MHU,IPC
 SG_ CCU_Data3 : 47|8@0+ (1,0) [0|255] ""  GW,MHU,IPC
 SG_ CCU_Data4 : 55|8@0+ (1,0) [0|255] ""  GW,MHU,IPC
 SG_ CCU_Data5 : 63|8@0+ (1,0) [0|255] ""  GW,MHU,IPC

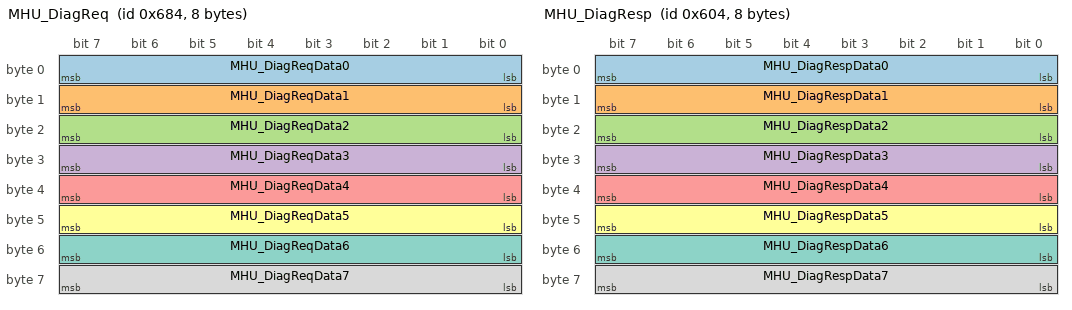
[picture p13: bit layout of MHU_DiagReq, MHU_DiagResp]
BO_ 1668 MHU_DiagReq: 8 GW
 SG_ MHU_DiagReqData0 : 7|8@0+ (1,0) [0|255] ""  MHU
 SG_ MHU_DiagReqData1 : 15|8@0+ (1,0) [0|255] ""  MHU
 SG_ MHU_DiagReqData2 : 23|8@0+ (1,0) [0|255] ""  MHU
 SG_ MHU_DiagReqData3 : 31|8@0+ (1,0) [0|255] ""  MHU
 SG_ MHU_DiagReqData4 : 39|8@0+ (1,0) [0|255] ""  MHU
 SG_ MHU_DiagReqData5 : 47|8@0+ (1,0) [0|255] ""  MHU
 SG_ MHU_DiagReqData6 : 55|8@0+ (1,0) [0|255] ""  MHU
 SG_ MHU_DiagReqData7 : 63|8@0+ (1,0) [0|255] ""  MHU

BO_ 1540 MHU_DiagResp: 8 MHU
 SG_ MHU_DiagRespData0 : 7|8@0+ (1,0) [0|255] ""  GW
 SG_ MHU_DiagRespData1 : 15|8@0+ (1,0) [0|255] ""  GW
 SG_ MHU_DiagRespData2 : 23|8@0+ (1,0) [0|255] ""  GW
 SG_ MHU_DiagRespData3 : 31|8@0+ (1,0) [0|255] ""  GW
 SG_ MHU_DiagRespData4 : 39|8@0+ (1,0) [0|255] ""  GW
 SG_ MHU_DiagRespData5 : 47|8@0+ (1,0) [0|255] ""  GW
 SG_ MHU_DiagRespData6 : 55|8@0+ (1,0) [0|255] ""  GW
 SG_ MHU_DiagRespData7 : 63|8@0+ (1,0) [0|255] ""  GW

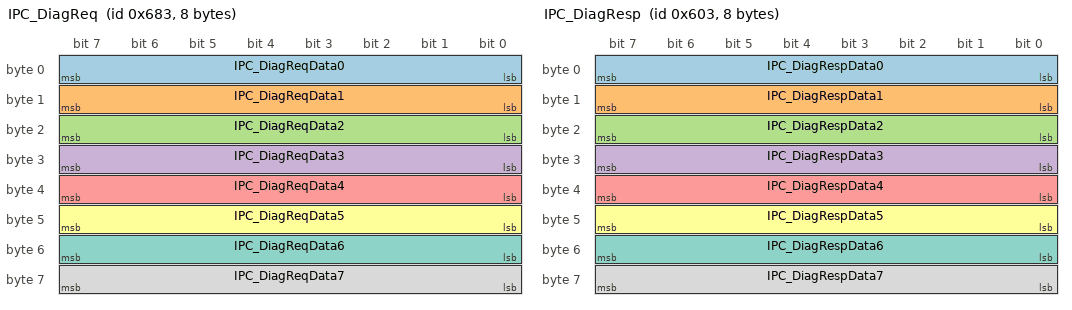
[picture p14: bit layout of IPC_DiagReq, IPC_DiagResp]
BO_ 1667 IPC_DiagReq: 8 GW
 SG_ IPC_DiagReqData0 : 7|8@0+ (1,0) [0|255] ""  IPC
 SG_ IPC_DiagReqData1 : 15|8@0+ (1,0) [0|255] ""  IPC
 SG_ IPC_DiagReqData2 : 23|8@0+ (1,0) [0|255] ""  IPC
 SG_ IPC_DiagReqData3 : 31|8@0+ (1,0) [0|255] ""  IPC
 SG_ IPC_DiagReqData4 : 39|8@0+ (1,0) [0|255] ""  IPC
 SG_ IPC_DiagReqData5 : 47|8@0+ (1,0) [0|255] ""  IPC
 SG_ IPC_DiagReqData6 : 55|8@0+ (1,0) [0|255] ""  IPC
 SG_ IPC_DiagReqData7 : 63|8@0+ (1,0) [0|255] ""  IPC

BO_ 1539 IPC_DiagResp: 8 IPC
 SG_ IPC_DiagRespData0 : 7|8@0+ (1,0) [0|255] ""  GW
 SG_ IPC_DiagRespData1 : 15|8@0+ (1,0) [0|255] ""  GW
 SG_ IPC_DiagRespData2 : 23|8@0+ (1,0) [0|255] ""  GW
 SG_ IPC_DiagRespData3 : 31|8@0+ (1,0) [0|255] ""  GW
 SG_ IPC_DiagRespData4 : 39|8@0+ (1,0) [0|255] ""  GW
 SG_ IPC_DiagRespData5 : 47|8@0+ (1,0) [0|255] ""  GW
 SG_ IPC_DiagRespData6 : 55|8@0+ (1,0) [0|255] ""  GW
 SG_ IPC_DiagRespData7 : 63|8@0+ (1,0) [0|255] ""  GW

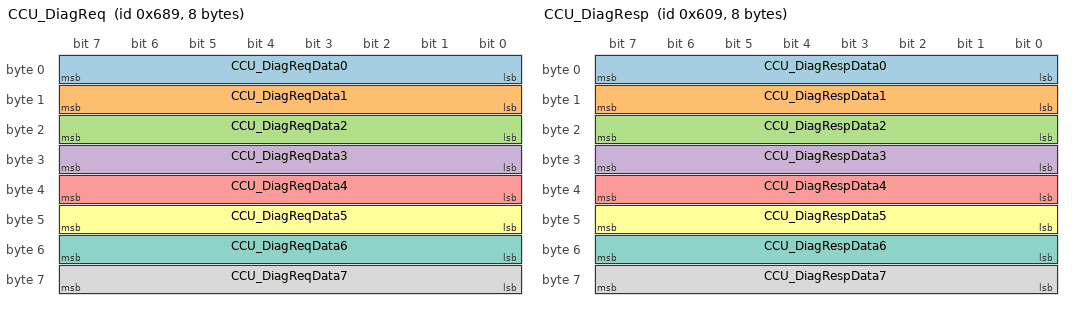
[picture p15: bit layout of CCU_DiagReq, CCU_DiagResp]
BO_ 1673 CCU_DiagReq: 8 GW
 SG_ CCU_DiagReqData0 : 7|8@0+ (1,0) [0|255] ""  CCU
 SG_ CCU_DiagReqData1 : 15|8@0+ (1,0) [0|255] ""  CCU
 SG_ CCU_DiagReqData2 : 23|8@0+ (1,0) [0|255] ""  CCU
 SG_ CCU_DiagReqData3 : 31|8@0+ (1,0) [0|255] ""  CCU
 SG_ CCU_DiagReqData4 : 39|8@0+ (1,0) [0|255] ""  CCU
 SG_ CCU_DiagReqData5 : 47|8@0+ (1,0) [0|255] ""  CCU
 SG_ CCU_DiagReqData6 : 55|8@0+ (1,0) [0|255] ""  CCU
 SG_ CCU_DiagReqData7 : 63|8@0+ (1,0) [0|255] ""  CCU

BO_ 1545 CCU_DiagResp: 8 CCU
 SG_ CCU_DiagRespData0 : 7|8@0+ (1,0) [0|255] ""  GW
 SG_ CCU_DiagRespData1 : 15|8@0+ (1,0) [0|255] ""  GW
 SG_ CCU_DiagRespData2 : 23|8@0+ (1,0) [0|255] ""  GW
 SG_ CCU_DiagRespData3 : 31|8@0+ (1,0) [0|255] ""  GW
 SG_ CCU_DiagRespData4 : 39|8@0+ (1,0) [0|255] ""  GW
 SG_ CCU_DiagRespData5 : 47|8@0+ (1,0) [0|255] ""  GW
 SG_ CCU_DiagRespData6 : 55|8@0+ (1,0) [0|255] ""  GW
 SG_ CCU_DiagRespData7 : 63|8@0+ (1,0) [0|255] ""  GW

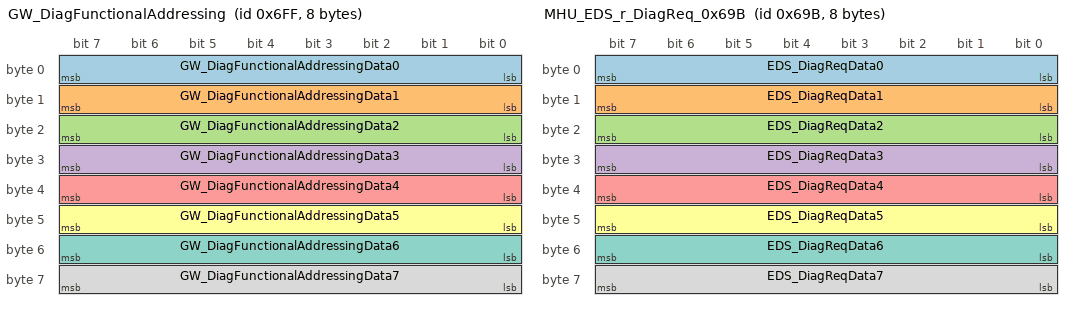
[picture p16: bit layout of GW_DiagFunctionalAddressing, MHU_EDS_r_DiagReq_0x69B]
BO_ 1791 GW_DiagFunctionalAddressing: 8 GW
 SG_ GW_DiagFunctionalAddressingData0 : 7|8@0+ (1,0) [0|255] ""  MHU,IPC,CCU
 SG_ GW_DiagFunctionalAddressingData1 : 15|8@0+ (1,0) [0|255] ""  MHU,IPC,CCU
 SG_ GW_DiagFunctionalAddressingData2 : 23|8@0+ (1,0) [0|255] ""  MHU,IPC,CCU
 SG_ GW_DiagFunctionalAddressingData3 : 31|8@0+ (1,0) [0|255] ""  MHU,IPC,CCU
 SG_ GW_DiagFunctionalAddressingData4 : 39|8@0+ (1,0) [0|255] ""  MHU,IPC,CCU
 SG_ GW_DiagFunctionalAddressingData5 : 47|8@0+ (1,0) [0|255] ""  MHU,IPC,CCU
 SG_ GW_DiagFunctionalAddressingData6 : 55|8@0+ (1,0) [0|255] ""  MHU,IPC,CCU
 SG_ GW_DiagFunctionalAddressingData7 : 63|8@0+ (1,0) [0|255] ""  MHU,IPC,CCU

BO_ 1691 MHU_EDS_r_DiagReq_0x69B: 8 MHU
 SG_ EDS_DiagReqData0 : 7|8@0+ (1,0) [0|255] ""  GW
 SG_ EDS_DiagReqData1 : 15|8@0+ (1,0) [0|255] ""  GW
 SG_ EDS_DiagReqData2 : 23|8@0+ (1,0) [0|255] ""  GW
 SG_ EDS_DiagReqData3 : 31|8@0+ (1,0) [0|255] ""  GW
 SG_ EDS_DiagReqData4 : 39|8@0+ (1,0) [0|255] ""  GW
 SG_ EDS_DiagReqData5 : 47|8@0+ (1,0) [0|255] ""  GW
 SG_ EDS_DiagReqData6 : 55|8@0+ (1,0) [0|255] ""  GW
 SG_ EDS_DiagReqData7 : 63|8@0+ (1,0) [0|255] ""  GW

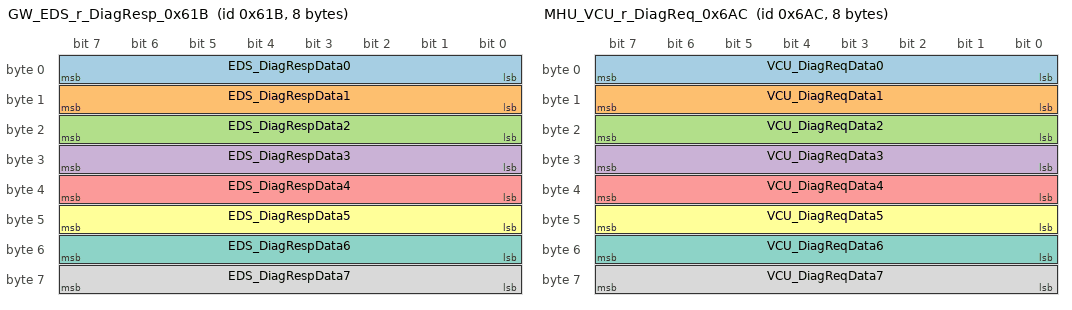
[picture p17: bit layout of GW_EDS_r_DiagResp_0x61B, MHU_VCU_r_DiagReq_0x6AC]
BO_ 1563 GW_EDS_r_DiagResp_0x61B: 8 GW
 SG_ EDS_DiagRespData0 : 7|8@0+ (1,0) [0|255] ""  MHU
 SG_ EDS_DiagRespData1 : 15|8@0+ (1,0) [0|255] ""  MHU
 SG_ EDS_DiagRespData2 : 23|8@0+ (1,0) [0|255] ""  MHU
 SG_ EDS_DiagRespData3 : 31|8@0+ (1,0) [0|255] ""  MHU
 SG_ EDS_DiagRespData4 : 39|8@0+ (1,0) [0|255] ""  MHU
 SG_ EDS_DiagRespData5 : 47|8@0+ (1,0) [0|255] ""  MHU
 SG_ EDS_DiagRespData6 : 55|8@0+ (1,0) [0|255] ""  MHU
 SG_ EDS_DiagRespData7 : 63|8@0+ (1,0) [0|255] ""  MHU

BO_ 1708 MHU_VCU_r_DiagReq_0x6AC: 8 MHU
 SG_ VCU_DiagReqData0 : 7|8@0+ (1,0) [0|255] ""  GW
 SG_ VCU_DiagReqData1 : 15|8@0+ (1,0) [0|255] ""  GW
 SG_ VCU_DiagReqData2 : 23|8@0+ (1,0) [0|255] ""  GW
 SG_ VCU_DiagReqData3 : 31|8@0+ (1,0) [0|255] ""  GW
 SG_ VCU_DiagReqData4 : 39|8@0+ (1,0) [0|255] ""  GW
 SG_ VCU_DiagReqData5 : 47|8@0+ (1,0) [0|255] ""  GW
 SG_ VCU_DiagReqData6 : 55|8@0+ (1,0) [0|255] ""  GW
 SG_ VCU_DiagReqData7 : 63|8@0+ (1,0) [0|255] ""  GW

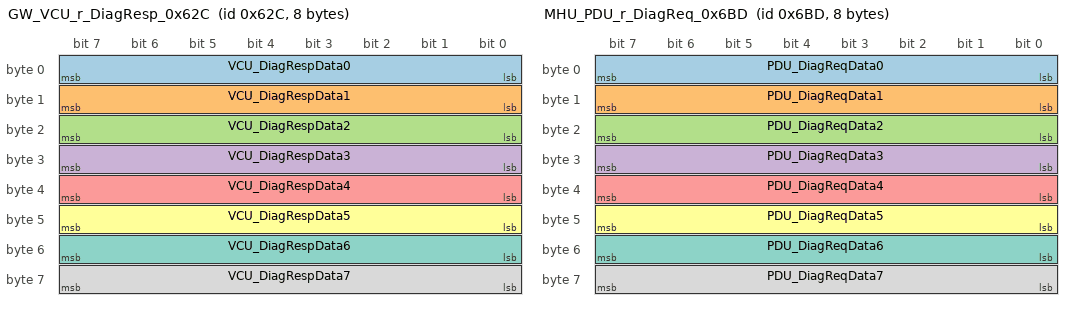
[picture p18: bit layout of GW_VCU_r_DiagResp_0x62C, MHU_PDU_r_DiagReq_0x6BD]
BO_ 1580 GW_VCU_r_DiagResp_0x62C: 8 GW
 SG_ VCU_DiagRespData0 : 7|8@0+ (1,0) [0|255] ""  MHU
 SG_ VCU_DiagRespData1 : 15|8@0+ (1,0) [0|255] ""  MHU
 SG_ VCU_DiagRespData2 : 23|8@0+ (1,0) [0|255] ""  MHU
 SG_ VCU_DiagRespData3 : 31|8@0+ (1,0) [0|255] ""  MHU
 SG_ VCU_DiagRespData4 : 39|8@0+ (1,0) [0|255] ""  MHU
 SG_ VCU_DiagRespData5 : 47|8@0+ (1,0) [0|255] ""  MHU
 SG_ VCU_DiagRespData6 : 55|8@0+ (1,0) [0|255] ""  MHU
 SG_ VCU_DiagRespData7 : 63|8@0+ (1,0) [0|255] ""  MHU

BO_ 1725 MHU_PDU_r_DiagReq_0x6BD: 8 MHU
 SG_ PDU_DiagReqData0 : 7|8@0+ (1,0) [0|255] ""  GW
 SG_ PDU_DiagReqData1 : 15|8@0+ (1,0) [0|255] ""  GW
 SG_ PDU_DiagReqData2 : 23|8@0+ (1,0) [0|255] ""  GW
 SG_ PDU_DiagReqData3 : 31|8@0+ (1,0) [0|255] ""  GW
 SG_ PDU_DiagReqData4 : 39|8@0+ (1,0) [0|255] ""  GW
 SG_ PDU_DiagReqData5 : 47|8@0+ (1,0) [0|255] ""  GW
 SG_ PDU_DiagReqData6 : 55|8@0+ (1,0) [0|255] ""  GW
 SG_ PDU_DiagReqData7 : 63|8@0+ (1,0) [0|255] ""  GW

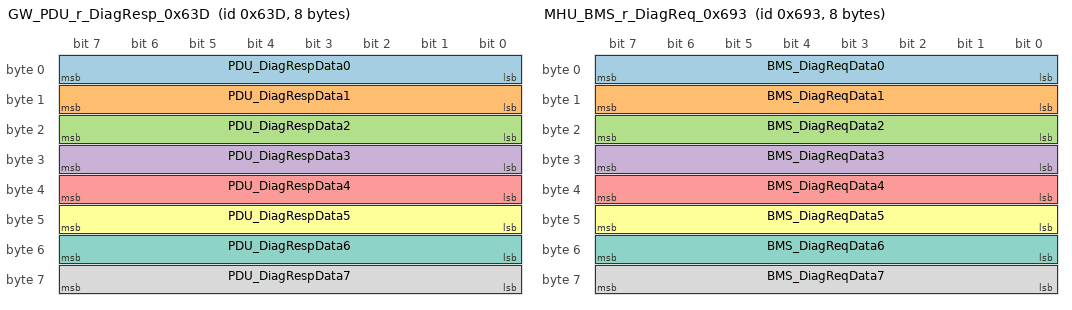
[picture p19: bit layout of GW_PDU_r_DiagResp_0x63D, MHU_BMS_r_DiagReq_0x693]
BO_ 1597 GW_PDU_r_DiagResp_0x63D: 8 GW
 SG_ PDU_DiagRespData0 : 7|8@0+ (1,0) [0|255] ""  MHU
 SG_ PDU_DiagRespData1 : 15|8@0+ (1,0) [0|255] ""  MHU
 SG_ PDU_DiagRespData2 : 23|8@0+ (1,0) [0|255] ""  MHU
 SG_ PDU_DiagRespData3 : 31|8@0+ (1,0) [0|255] ""  MHU
 SG_ PDU_DiagRespData4 : 39|8@0+ (1,0) [0|255] ""  MHU
 SG_ PDU_DiagRespData5 : 47|8@0+ (1,0) [0|255] ""  MHU
 SG_ PDU_DiagRespData6 : 55|8@0+ (1,0) [0|255] ""  MHU
 SG_ PDU_DiagRespData7 : 63|8@0+ (1,0) [0|255] ""  MHU

BO_ 1683 MHU_BMS_r_DiagReq_0x693: 8 MHU
 SG_ BMS_DiagReqData0 : 7|8@0+ (1,0) [0|255] ""  GW
 SG_ BMS_DiagReqData1 : 15|8@0+ (1,0) [0|255] ""  GW
 SG_ BMS_DiagReqData2 : 23|8@0+ (1,0) [0|255] ""  GW
 SG_ BMS_DiagReqData3 : 31|8@0+ (1,0) [0|255] ""  GW
 SG_ BMS_DiagReqData4 : 39|8@0+ (1,0) [0|255] ""  GW
 SG_ BMS_DiagReqData5 : 47|8@0+ (1,0) [0|255] ""  GW
 SG_ BMS_DiagReqData6 : 55|8@0+ (1,0) [0|255] ""  GW
 SG_ BMS_DiagReqData7 : 63|8@0+ (1,0) [0|255] ""  GW

BO_ 1555 GW_BMS_r_DiagResp_0x613: 8 GW
 SG_ BMS_DiagRespData0 : 7|8@0+ (1,0) [0|255] ""  MHU
 SG_ BMS_DiagRespData1 : 15|8@0+ (1,0) [0|255] ""  MHU
 SG_ BMS_DiagRespData2 : 23|8@0+ (1,0) [0|255] ""  MHU
 SG_ BMS_DiagRespData3 : 31|8@0+ (1,0) [0|255] ""  MHU
 SG_ BMS_DiagRespData4 : 39|8@0+ (1,0) [0|255] ""  MHU
 SG_ BMS_DiagRespData5 : 47|8@0+ (1,0) [0|255] ""  MHU
 SG_ BMS_DiagRespData6 : 55|8@0+ (1,0) [0|255] ""  MHU
 SG_ BMS_DiagRespData7 : 63|8@0+ (1,0) [0|255] ""  MHU

BO_ 1781 MHU_EAC_r_DiagReq_0x6F5: 8 MHU
 SG_ EAC_DiagReqData0 : 7|8@0+ (1,0) [0|255] ""  GW
 SG_ EAC_DiagReqData1 : 15|8@0+ (1,0) [0|255] ""  GW
 SG_ EAC_DiagReqData2 : 23|8@0+ (1,0) [0|255] ""  GW
 SG_ EAC_DiagReqData3 : 31|8@0+ (1,0) [0|255] ""  GW
 SG_ EAC_DiagReqData4 : 39|8@0+ (1,0) [0|255] ""  GW
 SG_ EAC_DiagReqData5 : 47|8@0+ (1,0) [0|255] ""  GW
 SG_ EAC_DiagReqData6 : 55|8@0+ (1,0) [0|255] ""  GW
 SG_ EAC_DiagReqData7 : 63|8@0+ (1,0) [0|255] ""  GW

BO_ 1653 GW_EAC_r_DiagResp_0x675: 8 GW
 SG_ EAC_DiagRespData0 : 7|8@0+ (1,0) [0|255] ""  MHU
 SG_ EAC_DiagRespData1 : 15|8@0+ (1,0) [0|255] ""  MHU
 SG_ EAC_DiagRespData2 : 23|8@0+ (1,0) [0|255] ""  MHU
 SG_ EAC_DiagRespData3 : 31|8@0+ (1,0) [0|255] ""  MHU
 SG_ EAC_DiagRespData4 : 39|8@0+ (1,0) [0|255] ""  MHU
 SG_ EAC_DiagRespData5 : 47|8@0+ (1,0) [0|255] ""  MHU
 SG_ EAC_DiagRespData6 : 55|8@0+ (1,0) [0|255] ""  MHU
 SG_ EAC_DiagRespData7 : 63|8@0+ (1,0) [0|255] ""  MHU

BO_ 1695 MHU_EVCC_r_DiagReq_0x69F: 8 MHU
 SG_ EVCC_DiagReqData0 : 7|8@0+ (1,0) [0|255] ""  GW
 SG_ EVCC_DiagReqData1 : 15|8@0+ (1,0) [0|255] ""  GW
 SG_ EVCC_DiagReqData2 : 23|8@0+ (1,0) [0|255] ""  GW
 SG_ EVCC_DiagReqData3 : 31|8@0+ (1,0) [0|255] ""  GW
 SG_ EVCC_DiagReqData4 : 39|8@0+ (1,0) [0|255] ""  GW
 SG_ EVCC_DiagReqData5 : 47|8@0+ (1,0) [0|255] ""  GW
 SG_ EVCC_DiagReqData6 : 55|8@0+ (1,0) [0|255] ""  GW
 SG_ EVCC_DiagReqData7 : 63|8@0+ (1,0) [0|255] ""  GW

BO_ 1567 GW_EVCC_r_DiagResp_0x61F: 8 GW
 SG_ EVCC_DiagRespData0 : 7|8@0+ (1,0) [0|255] ""  MHU
 SG_ EVCC_DiagRespData1 : 15|8@0+ (1,0) [0|255] ""  MHU
 SG_ EVCC_DiagRespData2 : 23|8@0+ (1,0) [0|255] ""  MHU
 SG_ EVCC_DiagRespData3 : 31|8@0+ (1,0) [0|255] ""  MHU
 SG_ EVCC_DiagRespData4 : 39|8@0+ (1,0) [0|255] ""  MHU
 SG_ EVCC_DiagRespData5 : 47|8@0+ (1,0) [0|255] ""  MHU
 SG_ EVCC_DiagRespData6 : 55|8@0+ (1,0) [0|255] ""  MHU
 SG_ EVCC_DiagRespData7 : 63|8@0+ (1,0) [0|255] ""  MHU

BO_ 1705 MHU_ESC_r_DiagReq_0x6A9: 8 MHU
 SG_ ESC_DiagReqData0 : 7|8@0+ (1,0) [0|255] ""  GW
 SG_ ESC_DiagReqData1 : 15|8@0+ (1,0) [0|255] ""  GW
 SG_ ESC_DiagReqData2 : 23|8@0+ (1,0) [0|255] ""  GW
 SG_ ESC_DiagReqData3 : 31|8@0+ (1,0) [0|255] ""  GW
 SG_ ESC_DiagReqData4 : 39|8@0+ (1,0) [0|255] ""  GW
 SG_ ESC_DiagReqData5 : 47|8@0+ (1,0) [0|255] ""  GW
 SG_ ESC_DiagReqData6 : 55|8@0+ (1,0) [0|255] ""  GW
 SG_ ESC_DiagReqData7 : 63|8@0+ (1,0) [0|255] ""  GW

BO_ 1577 GW_ESC_r_DiagResp_0x629: 8 GW
 SG_ ESC_DiagRespData0 : 7|8@0+ (1,0) [0|255] ""  MHU
 SG_ ESC_DiagRespData1 : 15|8@0+ (1,0) [0|255] ""  MHU
 SG_ ESC_DiagRespData2 : 23|8@0+ (1,0) [0|255] ""  MHU
 SG_ ESC_DiagRespData3 : 31|8@0+ (1,0) [0|255] ""  MHU
 SG_ ESC_DiagRespData4 : 39|8@0+ (1,0) [0|255] ""  MHU
 SG_ ESC_DiagRespData5 : 47|8@0+ (1,0) [0|255] ""  MHU
 SG_ ESC_DiagRespData6 : 55|8@0+ (1,0) [0|255] ""  MHU
 SG_ ESC_DiagRespData7 : 63|8@0+ (1,0) [0|255] ""  MHU

BO_ 1704 MHU_EPS_r_DiagReq_0x6A8: 8 MHU
 SG_ EPS_DiagReqData0 : 7|8@0+ (1,0) [0|255] ""  GW
 SG_ EPS_DiagReqData1 : 15|8@0+ (1,0) [0|255] ""  GW
 SG_ EPS_DiagReqData2 : 23|8@0+ (1,0) [0|255] ""  GW
 SG_ EPS_DiagReqData3 : 31|8@0+ (1,0) [0|255] ""  GW
 SG_ EPS_DiagReqData4 : 39|8@0+ (1,0) [0|255] ""  GW
 SG_ EPS_DiagReqData5 : 47|8@0+ (1,0) [0|255] ""  GW
 SG_ EPS_DiagReqData6 : 55|8@0+ (1,0) [0|255] ""  GW
 SG_ EPS_DiagReqData7 : 63|8@0+ (1,0) [0|255] ""  GW

BO_ 1576 GW_EPS_r_DiagResp_0x628: 8 GW
 SG_ EPS_DiagRespData0 : 7|8@0+ (1,0) [0|255] ""  MHU
 SG_ EPS_DiagRespData1 : 15|8@0+ (1,0) [0|255] ""  MHU
 SG_ EPS_DiagRespData2 : 23|8@0+ (1,0) [0|255] ""  MHU
 SG_ EPS_DiagRespData3 : 31|8@0+ (1,0) [0|255] ""  MHU
 SG_ EPS_DiagRespData4 : 39|8@0+ (1,0) [0|255] ""  MHU
 SG_ EPS_DiagRespData5 : 47|8@0+ (1,0) [0|255] ""  MHU
 SG_ EPS_DiagRespData6 : 55|8@0+ (1,0) [0|255] ""  MHU
 SG_ EPS_DiagRespData7 : 63|8@0+ (1,0) [0|255] ""  MHU

BO_ 1680 MHU_EKS_r_DiagReq_0x690: 8 MHU
 SG_ EKS_DiagReqData0 : 7|8@0+ (1,0) [0|255] ""  GW
 SG_ EKS_DiagReqData1 : 15|8@0+ (1,0) [0|255] ""  GW
 SG_ EKS_DiagReqData2 : 23|8@0+ (1,0) [0|255] ""  GW
 SG_ EKS_DiagReqData3 : 31|8@0+ (1,0) [0|255] ""  GW
 SG_ EKS_DiagReqData4 : 39|8@0+ (1,0) [0|255] ""  GW
 SG_ EKS_DiagReqData5 : 47|8@0+ (1,0) [0|255] ""  GW
 SG_ EKS_DiagReqData6 : 55|8@0+ (1,0) [0|255] ""  GW
 SG_ EKS_DiagReqData7 : 63|8@0+ (1,0) [0|255] ""  GW

BO_ 1552 GW_EKS_r_DiagResp_0x610: 8 GW
 SG_ EKS_DiagRespData0 : 7|8@0+ (1,0) [0|255] ""  MHU
 SG_ EKS_DiagRespData1 : 15|8@0+ (1,0) [0|255] ""  MHU
 SG_ EKS_DiagRespData2 : 23|8@0+ (1,0) [0|255] ""  MHU
 SG_ EKS_DiagRespData3 : 31|8@0+ (1,0) [0|255] ""  MHU
 SG_ EKS_DiagRespData4 : 39|8@0+ (1,0) [0|255] ""  MHU
 SG_ EKS_DiagRespData5 : 47|8@0+ (1,0) [0|255] ""  MHU
 SG_ EKS_DiagRespData6 : 55|8@0+ (1,0) [0|255] ""  MHU
 SG_ EKS_DiagRespData7 : 63|8@0+ (1,0) [0|255] ""  MHU

BO_ 2018 MHU_IPC_r_DiagReq_0x7E2: 8 MHU
 SG_ IPC_DiagReqData0 : 7|8@0+ (1,0) [0|255] ""  GW
 SG_ IPC_DiagReqData1 : 15|8@0+ (1,0) [0|255] ""  GW
 SG_ IPC_DiagReqData2 : 23|8@0+ (1,0) [0|255] ""  GW
 SG_ IPC_DiagReqData3 : 31|8@0+ (1,0) [0|255] ""  GW
 SG_ IPC_DiagReqData4 : 39|8@0+ (1,0) [0|255] ""  GW
 SG_ IPC_DiagReqData5 : 47|8@0+ (1,0) [0|255] ""  GW
 SG_ IPC_DiagReqData6 : 55|8@0+ (1,0) [0|255] ""  GW
 SG_ IPC_DiagReqData7 : 63|8@0+ (1,0) [0|255] ""  GW

BO_ 2026 IPC_r_DiagResp_0x7EA: 8 GW
 SG_ IPC_DiagRespData0 : 7|8@0+ (1,0) [0|255] ""  MHU
 SG_ IPC_DiagRespData1 : 15|8@0+ (1,0) [0|255] ""  MHU
 SG_ IPC_DiagRespData2 : 23|8@0+ (1,0) [0|255] ""  MHU
 SG_ IPC_DiagRespData3 : 31|8@0+ (1,0) [0|255] ""  MHU
 SG_ IPC_DiagRespData4 : 39|8@0+ (1,0) [0|255] ""  MHU
 SG_ IPC_DiagRespData5 : 47|8@0+ (1,0) [0|255] ""  MHU
 SG_ IPC_DiagRespData6 : 55|8@0+ (1,0) [0|255] ""  MHU
 SG_ IPC_DiagRespData7 : 63|8@0+ (1,0) [0|255] ""  MHU

BO_ 1666 MHU_XGW_r_DiagReq_0x682: 8 MHU
 SG_ XGW_DiagReqData0 : 7|8@0+ (1,0) [0|255] ""  GW
 SG_ XGW_DiagReqData1 : 15|8@0+ (1,0) [0|255] ""  GW
 SG_ XGW_DiagReqData2 : 23|8@0+ (1,0) [0|255] ""  GW
 SG_ XGW_DiagReqData3 : 31|8@0+ (1,0) [0|255] ""  GW
 SG_ XGW_DiagReqData4 : 39|8@0+ (1,0) [0|255] ""  GW
 SG_ XGW_DiagReqData5 : 47|8@0+ (1,0) [0|255] ""  GW
 SG_ XGW_DiagReqData6 : 55|8@0+ (1,0) [0|255] ""  GW
 SG_ XGW_DiagReqData7 : 63|8@0+ (1,0) [0|255] ""  GW

BO_ 1538 XGW_r_DiagResp_0x602: 8 GW
 SG_ XGW_DiagRespData0 : 7|8@0+ (1,0) [0|255] ""  MHU
 SG_ XGW_DiagRespData1 : 15|8@0+ (1,0) [0|255] ""  MHU
 SG_ XGW_DiagRespData2 : 23|8@0+ (1,0) [0|255] ""  MHU
 SG_ XGW_DiagRespData3 : 31|8@0+ (1,0) [0|255] ""  MHU
 SG_ XGW_DiagRespData4 : 39|8@0+ (1,0) [0|255] ""  MHU
 SG_ XGW_DiagRespData5 : 47|8@0+ (1,0) [0|255] ""  MHU
 SG_ XGW_DiagRespData6 : 55|8@0+ (1,0) [0|255] ""  MHU
 SG_ XGW_DiagRespData7 : 63|8@0+ (1,0) [0|255] ""  MHU

BO_ 2019 MHU_CCU_r_DiagReq_0x7E3: 8 MHU
 SG_ CCU_DiagReqData0 : 7|8@0+ (1,0) [0|255] ""  GW
 SG_ CCU_DiagReqData1 : 15|8@0+ (1,0) [0|255] ""  GW
 SG_ CCU_DiagReqData2 : 23|8@0+ (1,0) [0|255] ""  GW
 SG_ CCU_DiagReqData3 : 31|8@0+ (1,0) [0|255] ""  GW
 SG_ CCU_DiagReqData4 : 39|8@0+ (1,0) [0|255] ""  GW
 SG_ CCU_DiagReqData5 : 47|8@0+ (1,0) [0|255] ""  GW
 SG_ CCU_DiagReqData6 : 55|8@0+ (1,0) [0|255] ""  GW
 SG_ CCU_DiagReqData7 : 63|8@0+ (1,0) [0|255] ""  GW

BO_ 2027 CCU_r_DiagResp_0x7EB: 8 GW
 SG_ CCU_DiagRespData0 : 7|8@0+ (1,0) [0|255] ""  MHU
 SG_ CCU_DiagRespData1 : 15|8@0+ (1,0) [0|255] ""  MHU
 SG_ CCU_DiagRespData2 : 23|8@0+ (1,0) [0|255] ""  MHU
 SG_ CCU_DiagRespData3 : 31|8@0+ (1,0) [0|255] ""  MHU
 SG_ CCU_DiagRespData4 : 39|8@0+ (1,0) [0|255] ""  MHU
 SG_ CCU_DiagRespData5 : 47|8@0+ (1,0) [0|255] ""  MHU
 SG_ CCU_DiagRespData6 : 55|8@0+ (1,0) [0|255] ""  MHU
 SG_ CCU_DiagRespData7 : 63|8@0+ (1,0) [0|255] ""  MHU

BO_ 1672 MHU_ACM_r_DiagReq_0x688: 8 MHU
 SG_ ACM_DiagReqData0 : 7|8@0+ (1,0) [0|255] ""  GW
 SG_ ACM_DiagReqData1 : 15|8@0+ (1,0) [0|255] ""  GW
 SG_ ACM_DiagReqData2 : 23|8@0+ (1,0) [0|255] ""  GW
 SG_ ACM_DiagReqData3 : 31|8@0+ (1,0) [0|255] ""  GW
 SG_ ACM_DiagReqData4 : 39|8@0+ (1,0) [0|255] ""  GW
 SG_ ACM_DiagReqData5 : 47|8@0+ (1,0) [0|255] ""  GW
 SG_ ACM_DiagReqData6 : 55|8@0+ (1,0) [0|255] ""  GW
 SG_ ACM_DiagReqData7 : 63|8@0+ (1,0) [0|255] ""  GW

BO_ 1544 GW_ACM_r_DiagResp_0x608: 8 GW
 SG_ ACM_DiagRespData0 : 7|8@0+ (1,0) [0|255] ""  MHU
 SG_ ACM_DiagRespData1 : 15|8@0+ (1,0) [0|255] ""  MHU
 SG_ ACM_DiagRespData2 : 23|8@0+ (1,0) [0|255] ""  MHU
 SG_ ACM_DiagRespData3 : 31|8@0+ (1,0) [0|255] ""  MHU
 SG_ ACM_DiagRespData4 : 39|8@0+ (1,0) [0|255] ""  MHU
 SG_ ACM_DiagRespData5 : 47|8@0+ (1,0) [0|255] ""  MHU
 SG_ ACM_DiagRespData6 : 55|8@0+ (1,0) [0|255] ""  MHU
 SG_ ACM_DiagRespData7 : 63|8@0+ (1,0) [0|255] ""  MHU

BO_ 1665 MHU_BCM_r_DiagReq_0x681: 8 MHU
 SG_ BCM_DiagReqData0 : 7|8@0+ (1,0) [0|255] ""  GW
 SG_ BCM_DiagReqData1 : 15|8@0+ (1,0) [0|255] ""  GW
 SG_ BCM_DiagReqData2 : 23|8@0+ (1,0) [0|255] ""  GW
 SG_ BCM_DiagReqData3 : 31|8@0+ (1,0) [0|255] ""  GW
 SG_ BCM_DiagReqData4 : 39|8@0+ (1,0) [0|255] ""  GW
 SG_ BCM_DiagReqData5 : 47|8@0+ (1,0) [0|255] ""  GW
 SG_ BCM_DiagReqData6 : 55|8@0+ (1,0) [0|255] ""  GW
 SG_ BCM_DiagReqData7 : 63|8@0+ (1,0) [0|255] ""  GW

BO_ 1537 GW_BCM_r_DiagResp_0x601: 8 GW
 SG_ BCM_DiagRespData0 : 7|8@0+ (1,0) [0|255] ""  MHU
 SG_ BCM_DiagRespData1 : 15|8@0+ (1,0) [0|255] ""  MHU
 SG_ BCM_DiagRespData2 : 23|8@0+ (1,0) [0|255] ""  MHU
 SG_ BCM_DiagRespData3 : 31|8@0+ (1,0) [0|255] ""  MHU
 SG_ BCM_DiagRespData4 : 39|8@0+ (1,0) [0|255] ""  MHU
 SG_ BCM_DiagRespData5 : 47|8@0+ (1,0) [0|255] ""  MHU
 SG_ BCM_DiagRespData6 : 55|8@0+ (1,0) [0|255] ""  MHU
 SG_ BCM_DiagRespData7 : 63|8@0+ (1,0) [0|255] ""  MHU

BO_ 1728 MHU_BSD_r_DiagReq_0x6C0: 8 MHU
 SG_ BSD_DiagReq_Data0 : 7|8@0+ (1,0) [0|255] ""  GW
 SG_ BSD_DiagReq_Data1 : 15|8@0+ (1,0) [0|255] ""  GW
 SG_ BSD_DiagReq_Data2 : 23|8@0+ (1,0) [0|255] ""  GW
 SG_ BSD_DiagReq_Data3 : 31|8@0+ (1,0) [0|255] ""  GW
 SG_ BSD_DiagReq_Data4 : 39|8@0+ (1,0) [0|255] ""  GW
 SG_ BSD_DiagReq_Data5 : 47|8@0+ (1,0) [0|255] ""  GW
 SG_ BSD_DiagReq_Data6 : 55|8@0+ (1,0) [0|255] ""  GW
 SG_ BSD_DiagReq_Data7 : 63|8@0+ (1,0) [0|255] ""  GW

BO_ 1600 GW_BSD_r_DiagResp_0x640: 8 GW
 SG_ BSD_DiagResp_Data0 : 7|8@0+ (1,0) [0|255] ""  MHU
 SG_ BSD_DiagResp_Data1 : 15|8@0+ (1,0) [0|255] ""  MHU
 SG_ BSD_DiagResp_Data2 : 23|8@0+ (1,0) [0|255] ""  MHU
 SG_ BSD_DiagResp_Data3 : 31|8@0+ (1,0) [0|255] ""  MHU
 SG_ BSD_DiagResp_Data4 : 39|8@0+ (1,0) [0|255] ""  MHU
 SG_ BSD_DiagResp_Data5 : 47|8@0+ (1,0) [0|255] ""  MHU
 SG_ BSD_DiagResp_Data6 : 55|8@0+ (1,0) [0|255] ""  MHU
 SG_ BSD_DiagResp_Data7 : 63|8@0+ (1,0) [0|255] ""  MHU

BO_ 2030 MHU_rFunc_DiagReq_0x7EE: 8 MHU
 SG_ GW_DiagFunctionalAddressingData0 : 7|8@0+ (1,0) [0|255] ""  GW
 SG_ GW_DiagFunctionalAddressingData1 : 15|8@0+ (1,0) [0|255] ""  GW
 SG_ GW_DiagFunctionalAddressingData2 : 23|8@0+ (1,0) [0|255] ""  GW
 SG_ GW_DiagFunctionalAddressingData3 : 31|8@0+ (1,0) [0|255] ""  GW
 SG_ GW_DiagFunctionalAddressingData4 : 39|8@0+ (1,0) [0|255] ""  GW
 SG_ GW_DiagFunctionalAddressingData5 : 47|8@0+ (1,0) [0|255] ""  GW
 SG_ GW_DiagFunctionalAddressingData6 : 55|8@0+ (1,0) [0|255] ""  GW
 SG_ GW_DiagFunctionalAddressingData7 : 63|8@0+ (1,0) [0|255] ""  GW

CM_ SG_ 261 Checksum_0x105 "Checksum";
CM_ SG_ 261 Rolling_Counter_0x105 "Rolling_Counter";
CM_ SG_ 261 BCM_STAT_TrunkAjar "Trunk Ajar Door Status";
CM_ SG_ 261 BCM_STAT_DoorAjarDriver "Ajar Door Driver Status";
CM_ SG_ 261 BCM_STAT_DoorAjarPassenger "Ajar Door Passenger Status";
CM_ SG_ 261 BCM_STAT_DoorAjarRL "Ajar Door Rear Left Status";
CM_ SG_ 261 BCM_STAT_DoorAjarRR "Ajar Door Rear Right Status";
CM_ SG_ 261 BCM_STAT_BonnetAjar_reserved "Ajar Bonnet Status";
CM_ SG_ 262 Checksum_0x106 "Checksum";
CM_ SG_ 262 Rolling_Counter_0x106 "Rolling_Counter";
CM_ SG_ 262 BCM_HighBeamSts "High beam output Status";
CM_ SG_ 262 BCM_LowBeamSts "Low beam output  Status";
CM_ SG_ 262 BCM_PosLmpSts "Position light output Status";
CM_ SG_ 262 BCM_TurnIndicatorSts "Turn light output  Status";
CM_ SG_ 262 BCM_DayRunningLampSts_reserved "DayRunning Lamp output Status";
CM_ SG_ 262 BCM_ReverseLightSts "Reverse light output Status";
CM_ SG_ 262 BCM_StopLightSts "Stop light output Status";
CM_ SG_ 262 BCM_Fr_Dimming_dome_lampSts "Dimming dome lamp Front Status";
CM_ SG_ 262 BCM_Heated_rearglass "Heate Rear Glass  Feedback";
CM_ SG_ 262 BCM_BsdLightSts "Indicates BSD status";
CM_ SG_ 262 BCM_STAT_LightActivation "Status of light";
CM_ SG_ 262 BCM_STAT_InteriorLight "status of backlight illumination";
CM_ SG_ 266 Checksum_0x10a "Checksum";
CM_ SG_ 266 Rolling_Counter_0x10a "Rolling_Counter";
CM_ SG_ 266 BCM_LVTop_up "LV  battery top up requice signal";
CM_ SG_ 266 Ubatt_Reserved "Battery Voltage(UBatt to be received by all modules,Required for DTC snapshots)";
CM_ SG_ 274 Checksum_0x112 "Checksum";
CM_ SG_ 274 Rolling_Counter_0x112 "Rolling_Counter";
CM_ SG_ 274 STAT_Terminal "Represent the status of physical terminal(STAT_Terminal to be received by all modules,Required for DTC snapshots and for FOTA)";
CM_ SG_ 274 STAT_CL30s_L_Reserved "Status Clamp 30s Logical ON/OFF";
CM_ SG_ 303 Checksum_0x12f "Checksum";
CM_ SG_ 303 Rolling_Counter_0x12f "Rolling_Counter";
CM_ SG_ 303 ST_KL_KEY_VLD "Key valid";
CM_ SG_ 303 ST_SSP "Status SSB";
CM_ SG_ 303 BCM_IMMO_Sts "IMMO staus";
CM_ SG_ 283 BCM_ACCRelayOutputSts "ACCRelays Output Status";
CM_ SG_ 283 BCM_IGN1RelayOutputSts "IG1 Relays Output Status";
CM_ SG_ 283 BCM_ACCRelayFalutSts "ACCRelays Fault Status";
CM_ SG_ 283 BCM_IGN1RelayFalutSts "IG1 Relays Fault Status";
CM_ SG_ 283 BCM_KEY_MatchSts "Match status with Key";
CM_ SG_ 529 PEPS_Lock_IGNNotOff_Alert "Power ON Alarm When Lock The Vehicle By key fob";
CM_ SG_ 529 PEPS_CID_NotInside_Alert "Key Not In Side Alarm When Start";
CM_ SG_ 529 PEPS_CID_Left_Alert "Key Left Alter";
CM_ SG_ 529 PEPS_RMKey_BatteryLow_Alert "Remote Key_Battery Low_Alert";
CM_ SG_ 529 PEPS_PressBrakePedal_Alert "Press Brake Pedal Alert";
CM_ SG_ 529 PEPS_Shift_Position_Alert "Shift_Position_AlertP/N（VCU）";
CM_ SG_ 529 PEPS_Lock_KeyInside_Alert "KeyInside Alert When Lock The Vehicle By Door Handler";
CM_ SG_ 529 PEPS_EmergencyStop_Reserved "Emergency Stop (reserved)";
CM_ SG_ 529 PEPS_CID_NotIndenfied_Alert "PEPS CID NotIndenfied Alert";
CM_ SG_ 529 BCM_Positionlight_reminder "reminde driver forgot turn OFF the position light when vehicle go to off";
CM_ SG_ 270 RemoteAccessKey "Status of remote key button Tailgate opening long press > 1.5 sec";
CM_ SG_ 270 PassiveAccessTrunk "BCM request for passive entry trunk";
CM_ SG_ 270 BCM_CurrentValid_FOB "Current valid of FOB ID";
CM_ SG_ 1053 BCM_STAT_RemoteLockFeedback "Remote Lock dback: customer can choose light feedback when lock or unlock the door with remote key";
CM_ SG_ 1053 BCM_STAT_RemoteDoorUnlock_reserv "Settings for Door lock unlock conditions";
CM_ SG_ 1053 BCM_STAT_AutoDoorUnlock "Auto door unlock: When the car is stopped and the shift lever is in “P ” or “N ” position, selected doors will be unlocked automatically";
CM_ SG_ 1053 BCM_STAT_DoorSpeedLock "Status feedback from BCM for Setting Door speed lock mode";
CM_ SG_ 1053 BCM_STAT_DayTimeRunningLight_res "BCM send out status for On Off Day Time Running Light";
CM_ SG_ 1053 BCM_STAT_AntiTheftMode "Confirm of setting Anti-theft mode";
CM_ SG_ 1053 BCM_FOBID_userprofile_link "Only use for link the keyfob into user profile";
CM_ SG_ 1053 BCM_feedback_FollowMeHomeTime "Feedback the time of Follow Me Home light";
CM_ SG_ 263 Checksum_0x107 "Checksum";
CM_ SG_ 263 Rolling_Counter_0x107 "Rolling_Counter";
CM_ SG_ 263 STAT_ATWS "Locking/UnLocking Status Anti theft Invalid value = 7";
CM_ SG_ 263 STAT_DoorLockDriver "Lock Status Driver Door used as central lock information";
CM_ SG_ 268 Checksum_0x10C "Checksum";
CM_ SG_ 268 Rolling_Counter_0x10C "Rolling_Counter";
CM_ SG_ 268 BCM_TboxAuthStatus "MHU's TBOX authentication status";
CM_ SG_ 268 BCM_RandomNum32bit "BCM's random OTP 32 bits and refresh every 20 secs";
CM_ SG_ 272 Checksum_0x110 "Checksum";
CM_ SG_ 272 Rolling_Counter_0x110 "Rolling_Counter";
CM_ SG_ 272 BCM_APM_FLWIN_Postion "FL window postion";
CM_ SG_ 272 BCM_APM_FRWIN_Postion "FR window postion";
CM_ SG_ 272 BCM_APM_RLWIN_Postion "RL window postion";
CM_ SG_ 272 BCM_APM_RRWIN_Postion "RR window postion";
CM_ SG_ 272 APM_Status "APM_Status";
CM_ SG_ 272 ChildProtectionStatus "Child Protection Status";
CM_ SG_ 272 APM_Window_DriveSW_FL_Status "Driver's window switch - left front window switch status";
CM_ SG_ 272 APM_Window_DriveSW_FR_Status "Driver's window switch - right front window switch status";
CM_ SG_ 272 APM_Window_DriveSW_RL_Status "Driver's window switch - left rear window switch status";
CM_ SG_ 272 APM_Window_DriveSW_RR_Status "Driver's window switch - right rear window switch status";
CM_ SG_ 272 APM_Window_PassengerSW_Status "Passenger's window switch - window switch status";
CM_ SG_ 272 APM_Window_PassengerSW_RL_Status "Passenger's window switch - left rear window switch status";
CM_ SG_ 272 APM_Window_PassengerSW_RR_Status "Passenger's window switch - right rear window switch status";
CM_ SG_ 525 Checksum_0x20D "Checksum";
CM_ SG_ 525 Rolling_Counter_0x20D "Rolling_Counter";
CM_ SG_ 525 BCM_ODO "odograph";
CM_ SG_ 834 Checksum_0x342 "Check sum";
CM_ SG_ 834 Rolling_Counter_0x342 "Rolling Counter";
CM_ SG_ 834 ABS_LRWhlSpdRaw "Current Raw wheel speed information of rear left wheel.";
CM_ SG_ 834 ABS_LRWhlSpdRawValid "Current Raw wheel speed information valid flag of rear left wheel.";
CM_ SG_ 834 ABS_RRWhlSpdRaw "Current Raw wheel speed information of rear right wheel.,";
CM_ SG_ 834 ABS_RRWhlSpdRawValid "Current Raw wheel speed information valid flag of rear right wheel";
CM_ SG_ 834 ABS_VehSpd "Current Longitudinal Vehicle Speed";
CM_ SG_ 834 ABS_VehSpdValid "Speed Valid Flag";
CM_ SG_ 306 Checksum_0x132 "check sum";
CM_ SG_ 306 RollingCounter_0x132 "Rolling counter";
CM_ SG_ 306 ESC_HSA_Control_Status "Indicate HSA function is active or not";
CM_ SG_ 306 ESC_HSA_Status_Fault "Detect the HAS Fault status";
CM_ SG_ 306 ESC_TcsDisableSts "Indicate the TCS function can use or not";
CM_ SG_ 306 ESC_TcsCtrlActv "Indicate TCS  function is active or not";
CM_ SG_ 306 ESC_TcsFlgFlt "Detect the TCS function fault status";
CM_ SG_ 306 ESC_EscDisableSts "Indicate the ESC function can use or not";
CM_ SG_ 306 ESC_EscCtrlActv "Indicate ESC  function is active or not";
CM_ SG_ 306 ESC_EscFlgFlt "Detect the ESC function fault status";
CM_ SG_ 306 ESC_HBAFlgFlt "Detect the HBA(Hydraulic Brake Assist) function status";
CM_ SG_ 306 ESC_HbaCtrlActv "Indicate HBA(Hydraulic Brake Assist)   function is active or not";
CM_ SG_ 306 ESC_SlopeGradeAngle "Vehicle slope,Uphill is negative (head is higher than tail), downhill is positive (tail is higher than head)";
CM_ SG_ 306 ESC_MasterCylinderPressure "Master cylinder pressure";
CM_ SG_ 322 Checksum_0x142 "check sum";
CM_ SG_ 322 RollingCounter_0x142 "Rolling counter";
CM_ SG_ 322 AbsDiagSessionLampReq_Reserved "ABS or ESC is currently in safety system diagnostic  session,(DVT mode) need cluster to turn on ESC/TCS, EBD, ABS fault lamp";
CM_ SG_ 322 ABS_AbsCtrlActv "ABS status(Indiacte ABS  function is active or not.When ABS intervention starts,it sets as 1)";
CM_ SG_ 322 ABS_EbdFlgFlt "The EBD system fault, The EBD warning lamp should be open,The signal will be set as  whenEBD is disable due to fault";
CM_ SG_ 322 ABS_AbsFlgFlt "The ABS system fault, The ABS warning lamp should be open,The signal will be set as whenABS is disable due to fault";
CM_ SG_ 322 ABS_ESS_Active "Emergency Stop Signaling Active,when emergency stop, this signal will set true";
CM_ SG_ 322 ABS_LowBrakeFluid "Detect the brake fluid level";
CM_ SG_ 994 Checksum_0x3E2 "check sum";
CM_ SG_ 994 RollingCounter_0x3E2 "Rolling counter";
CM_ SG_ 994 ESC_LateralACC "Indicate lateral acceleration";
CM_ SG_ 994 ESC_LateralACC_Valid "Valid flag of lateral acceleration";
CM_ SG_ 994 ESC_LongitudeACC "Indicate longitude acceleration";
CM_ SG_ 994 ESC_LongitudeACC_Valid "Valid flag of longitude acceleration";
CM_ SG_ 994 ESC_VehDynYawRate "Indicate the yaw rate";
CM_ SG_ 994 ESC_VehDynYawRate_Valid "Valid flag of yaw rate";
CM_ SG_ 1154 ESC_FLTirePressAlarm "Front left tire pressure alarm signal";
CM_ SG_ 1154 ESC_FRTirePressAlarm "Front right tire pressure alarm signal";
CM_ SG_ 1154 ESC_RLTirePressAlarm "Rear left tire pressure alarm signal";
CM_ SG_ 1154 ESC_RRTirePressAlarm "Rear right tire pressure alarm signal";
CM_ SG_ 1154 ESC_iTPMS_Err "Failure of tire pressure monitoring system";
CM_ SG_ 1154 ESC_iTPMS_WarnLampAct "The status of TPMS warning lamp";
CM_ SG_ 1154 ESC_iTPMSResetProhibit "Indicate whether calibration is allowed";
CM_ SG_ 1154 ESC_iTPMSResetSts "Tire pressure system reset status";
CM_ SG_ 496 SAS_SteerWheelAngle "The current angle of the steering wheel(Positive, to left; Negative, to right)";
CM_ SG_ 496 SAS_SteeringAngleValid "Effective signal for steering angle";
CM_ SG_ 496 SAS_SASStsSnsr "the flag of  SAS status Punch:Steering angle status";
CM_ SG_ 496 SAS_SteerWhlRotSpd "The current rotation speed of the steering wheel.";
CM_ SG_ 496 SAS_SteerWhlRotSpdStatus "The status of SteerWheel Rotation Speed valid";
CM_ SG_ 496 SAS_SASFailure "Angle sensor disabled.";
CM_ SG_ 496 EPS_EpsFailed "EPS failed bit";
CM_ SG_ 673 Checksum_0x2A1 "Checksum";
CM_ SG_ 673 Rolling_Counter_0x2A1 "Rolling_Counter";
CM_ SG_ 673 ODS_Status "Status of ODS";
CM_ SG_ 673 EVCC_MHU_CharSchSetFeedBack "MHU ChargeScheduleSet Feedback";
CM_ SG_ 673 EVCC_ChargeGunSts "charge gun statue";
CM_ SG_ 673 EVCC_ChargeMode "change mode AC or DC";
CM_ SG_ 673 EVCC_CP_Value "CP dutyvalue";
CM_ SG_ 673 EVCC_CP_Sts "CP State";
CM_ SG_ 673 EVCC_PP_Value "PP resistance value or state";
CM_ SG_ 673 EVCC_Lock_Sts "lock state";
CM_ SG_ 673 EVCC_ErrCode "EVCC Error code";
CM_ SG_ 792 EAC_CompElecCurrV "Compressor Electrical Current Validity";
CM_ SG_ 792 EAC_CompStat "Compressor status";
CM_ SG_ 792 EAC_CompElecPwrV "Compressor Electrical Power Validity";
CM_ SG_ 792 EAC_CompSpdIncrReq "Compressor Speed Increasing Request";
CM_ SG_ 792 EAC_CompSpdV "Compressor Actual Speed Validity";
CM_ SG_ 792 EAC_CompElecPwr "Compressor Electrical Power";
CM_ SG_ 792 EAC_CompSpd "Compressor Actual Speed";
CM_ SG_ 792 EAC_CompElecCurr "Compressor Electrical Current";
CM_ SG_ 792 EAC_CompFltStat "Compressor Fault Status";
CM_ SG_ 937 VCU_PTC_RelaySts "PTC Relayopen or close state";
CM_ SG_ 937 VCU_EACEnbReq "The command of compressor,AC enable signal";
CM_ SG_ 937 VCU_EACAllowedPower "EAC Allowed Power";
CM_ SG_ 937 VCU_EAC_CompSpdReq "Compressor Speed Request";
CM_ SG_ 937 VCU_DriveCoolWaterFlowRate "Actual drive cool water flow rate";
CM_ SG_ 937 VCU_DriveCoolInletWaterTemp "The temperature of inlet radiator";
CM_ SG_ 889 VCU_DriveCoolWaterPumpSts "Motor electronic pump state";
CM_ SG_ 889 VCU_DriveCoolWaterDuty "Motor electronic pump occupancy";
CM_ SG_ 889 VCU_BatteryWaterPumpSts_reserved "Battery electronic pump state";
CM_ SG_ 889 VCU_BatteryWaterPumpDuty_reserve "Battery electronic pump occupancy";
CM_ SG_ 889 VCU_DriveMode "Vehicle drive mode";
CM_ SG_ 889 VCU_ActualGear "actual gear,Provide gear shift signal";
CM_ SG_ 889 VCU_ACTGearValid "Indicate the current gear position";
CM_ SG_ 889 VCU_AccPedal1OutRange "The state of accelerator pedal1";
CM_ SG_ 889 VCU_AccPedal2OutRange "The state of accelerator pedal2";
CM_ SG_ 889 VCU_BrkPedal1OutRange "The synchronization state of brake pedal1";
CM_ SG_ 889 VCU_BrkPedal2OutRange "The state of barke pedal2";
CM_ SG_ 889 VCU_BrkPedalPct "The percent of brake pedal";
CM_ SG_ 889 VCU_AccPedalPosition "Indicate the acceleraton pedal position";
CM_ SG_ 889 VCU_AccPedalPositionValid "Indicate the acceleration pedal position valid flag";
CM_ SG_ 889 VCU_SocDisplay_EST "Battery SOC";
CM_ SG_ 889 VCU_PowerLimit "Vehicle power limit";
CM_ SG_ 889 VCU_CruiseCtrlSts "Cruise state";
CM_ SG_ 889 VCU_LowSOC_ERR "Battery SOC low";
CM_ SG_ 441 VCU_MCUConsumepower "MCU Consume power";
CM_ SG_ 441 VCU_EACConsumepower "EAC Consume power";
CM_ SG_ 441 VCU_DCDCConsumepower "DCDC Consume power";
CM_ SG_ 441 VCU_PTCConsumepower "PTC Consume power";
CM_ SG_ 425 VCU_RegenLevel_Feed "VCU current Feedback Set power regenerative level";
CM_ SG_ 425 VCU_RBCSts "Regenerative Braking";
CM_ SG_ 425 VCU_RDCSts "Regenerative coasted";
CM_ SG_ 425 VCU_Veh_ERR "Vehicle System Error";
CM_ SG_ 425 VCU_DrvSys_ERR "DriveSystemError";
CM_ SG_ 425 VCU_PackSys_ERR "StoredEnergySystemError";
CM_ SG_ 425 VCU_TBOX_Veh_STS_Reserved "Vehicle Status";
CM_ SG_ 425 VCU_VehChg_STS "Vehicle Charge Status";
CM_ SG_ 425 VCU_BatterVoltage_Reserved "BetteryVoltage";
CM_ SG_ 425 VCU_BatteryVoltErr_Reserved "Indicate the generator is warning when Mechanical flag or Electrical flag is active (Reserved)（）";
CM_ SG_ 425 VCU_MotorCoolingCircuitErr_Reser "Motor cooling loop failure state (Reserved)";
CM_ SG_ 425 VCU_PackCoolingCircuitErr_Reserv "Battery pack cooling loop failure state (Reserved)";
CM_ SG_ 425 VCU_VehicleHVStatus "Vehicle High voltage Ready State(VCU_VehicleHVStatus to be received by all modules,Used as a flash programming pre-condition (replacement for engine running)";
CM_ SG_ 425 VCU_InstantPowerConsump "Instant power consumption";
CM_ SG_ 425 VCU_AveragePowerConsump "Average power comsumption";
CM_ SG_ 425 VCU_BrakePedalSts "Brake Pedal Sts";
CM_ SG_ 1008 VCU_HVACInletWateTemp "HVAC inlet water temperature";
CM_ SG_ 1008 VCU_IMMO_Sts "IMMO staus";
CM_ SG_ 1008 VCU_DCDCAllowedPower "DCDCAllowedPower";
CM_ SG_ 1008 VCU_Shift_ERR "SCU file signal failure";
CM_ SG_ 1008 VCU_VehicleDischargePower "Discharge Power";
CM_ SG_ 1008 VCU_VehicleChargePower "Charge Power";
CM_ SG_ 992 Checksum_0x3E0 "Checksum";
CM_ SG_ 992 Rolling_Counter_0x3E0 "Rolling counter";
CM_ SG_ 992 VCU_RunningRange "Estimated running range ( at present )";
CM_ SG_ 992 VCU_MHU_Ack_ChgSche_stt "Status Enabled/ Disabled of Schedule Charging acknowledged by VCU base on request from MHU 0x403 MHU_ChargeScheduleSet.When this signal value = Enabled, VCU to follow 0x403 MHU_ChargingRequest = Start / Stop to start/ stop charging or stop charging when reach target SOC / battery full / chag.error.";
CM_ SG_ 992 VCU_MHU_GuestMode_sts "Feedback from VCU of Guest Mode ON/ OFF.Refer to Guest Mode definition document for more detail.";
CM_ SG_ 992 VCU_MHU_Ack_TargetSOC "Target SOC acknowledged by VCU base on request from MHU";
CM_ SG_ 992 VCU_ValetMode_sts "Status indicate valet mode is effected to VCU";
CM_ SG_ 992 VCU_ValetMode_MaxSpeedSts "Max speed setting of Valet mode";
CM_ SG_ 992 VCU_CreepDisable_stt "Feedback for Creep disable request";
CM_ SG_ 745 Checksum_0x2E9 "Checksum";
CM_ SG_ 745 Rolling_Counter_0x2E9 "Rolling counter";
CM_ SG_ 745 VCU_RemainingMileage "The remaining mileage";
CM_ SG_ 745 VCU_SetCruiseSpd "Set Cruise Speed";
CM_ SG_ 534 Checksum_0x216 "Checksum";
CM_ SG_ 534 Rolling_Counter_0x216 "Rolling_Counter";
CM_ SG_ 534 BMS_RemainChargeTime "Charge remaining time (XGW - IPC)";
CM_ SG_ 534 BMS_ChgVoltage_REQ "BMS requires charging voltage";
CM_ SG_ 534 BMS_ChgCurrent_REQ "BMS requires charging current";
CM_ SG_ 533 Checksum_0x215 "Checksum";
CM_ SG_ 533 Rolling_Counter_0x215 "Rolling Counter";
CM_ SG_ 533 BMS_SOE "BMS State Of Enegy";
CM_ SG_ 533 BMS_HWCrash_Sts "Battery Pack Hardware Crash signal Status";
CM_ SG_ 533 BMS_HVIL_STS "The HVIL state of BMS";
CM_ SG_ 533 BMS_IGN_Sts "the ignition signal status (on/off)";
CM_ SG_ 533 BMS_Sys_STS "BMS_Status(Self-test after BMS wake-up)";
CM_ SG_ 533 BMS_HVOnOff_STS "BMS High Voltage Status(BMS_HVOnOff_STS to be received by all modules,Used as a flash programming pre-condition (replacement for engine running)";
CM_ SG_ 533 BMS_Balance_STS "BMS Balance Status";
CM_ SG_ 533 BMS_SocActual_EST "Actual SOC";
CM_ SG_ 533 BMS_BatBalance_ERR "Battery Balance Error indicates Balancing switch is short or open";
CM_ SG_ 533 BMS_ISU_Status "Insulation status";
CM_ SG_ 533 BMS_ERR_LEV "BMS requesting VCU to operate at the limited operating strategy (LOS)";
CM_ SG_ 533 BMS_SOH "BMS State Of Health";
CM_ SG_ 533 BMS_HV_Sts "BMS High Voltage Status";
CM_ SG_ 1171 BMS_DischargeCurrent_Limited "Battery Discharge current limited due to BMS-MHU authentication failure.";
CM_ SG_ 1171 BMS_Warning_Flag_Reserved_07 "Warning signal";
CM_ SG_ 1171 BMS_Warning_Flag_Reserved_11 "Warning signal";
CM_ SG_ 1171 BMS_Warning_Flag_Reserved_10 "Warning signal";
CM_ SG_ 1171 BMS_Warning_Flag_Reserved_09 "Warning signal";
CM_ SG_ 1171 BMS_Warning_Flag_Reserved_13 "Warning signal";
CM_ SG_ 1171 BMS_Warning_Flag_Reserved_12 "Warning signal";
CM_ SG_ 1171 BMS_Warning_Flag_Reserved_06 "Warning signal";
CM_ SG_ 1171 BMS_Warning_Flag_Reserved_05 "Warning signal";
CM_ SG_ 1171 BMS_Warning_Flag_Reserved_04 "Warning signal";
CM_ SG_ 1171 BMS_MalfunctionSts "Malfunction status of battery for MHU display";
CM_ SG_ 1171 BMS_LowBattery "Low Battery Warning";
CM_ SG_ 1171 BMS_BatteryReplacement "Separate signal to indicate the battery replacement information(Battery replacement MHU)";
CM_ SG_ 1171 BMS_PackTempSts "Pack temperature warning";
CM_ SG_ 1171 BMS_ThermalRunaway "Thermalrunaway";
CM_ SG_ 1171 Rolling_Counter_0x493 "Rolling Counter";
CM_ SG_ 1171 Checksum_0x493 "Checksum";
CM_ SG_ 372 Checksum_0x174 "Checksum";
CM_ SG_ 372 Rolling_Counter_0x174 "Rolling_Counter";
CM_ SG_ 372 BMS_PackCur_MEAS "Pack Current";
CM_ SG_ 374 Checksum_0x176 "Checksum";
CM_ SG_ 374 Rolling_Counter_0x176 "Rolling Counter";
CM_ SG_ 374 BMS_HVLinkVol_MEAS "Link Voltage";
CM_ SG_ 374 BMS_HVPackVol_MEAS "Pack Voltage";
CM_ SG_ 523 Checksum_0x20B "Checksum";
CM_ SG_ 523 Rolling_Counter_0x20B "Rolling counter";
CM_ SG_ 523 DCDC_Sys_STS "DCDC System Status(Self-test after DCDC wake-up)";
CM_ SG_ 523 DCDC_Voltage_Input "DCDC Input Voltage";
CM_ SG_ 523 DCDC_Current_Input "DCDC Input Current";
CM_ SG_ 523 DCDC_Voltage_Output "DCDC Output Voltage";
CM_ SG_ 523 DCDC_Current_Output "DCDC Output Current";
CM_ SG_ 523 DCDC_Output_STS "DCDC Output Status";
CM_ SG_ 523 DCDC_Temp "DCDC Work Temperature";
CM_ SG_ 504 Checksum_0x1F8 "Check sum";
CM_ SG_ 504 Rolling_Counter_0x1F8 "Rolling counter";
CM_ SG_ 504 EDS_output_trq_FR "Actual output torque of current EDS";
CM_ SG_ 504 EDS_output_trqValid_FR "Indicate the valid flag of current motor torque";
CM_ SG_ 504 EDS_Spd_FR "current motor speed";
CM_ SG_ 504 EDS_SpdValid_FR "Indicate the valid flag of current motor speed";
CM_ SG_ 504 EDS_MotorDriveSts_FR "The drive state of EDS";
CM_ SG_ 504 EDS_Work_STS_FR "EDS Work status";
CM_ SG_ 504 EDS_powoff_req_FR "If there is a serious failure in the running process of EDS, the high voltage of VCU will be requested";
CM_ SG_ 1015 MFS_OK_Control "OK Control";
CM_ SG_ 1015 MFS_SourseControl "Resourse Control";
CM_ SG_ 1015 MFS_VoiceRecognitionOn_Off "VoiceRecognition control";
CM_ SG_ 1015 MFS_TelephoneCall_EndCall "Telephone Call funtionality control";
CM_ SG_ 1015 MFS_DownControl "Down Control";
CM_ SG_ 1015 MFS_UpControl "Up Control";
CM_ SG_ 1015 MFS_RightControl "Right Control";
CM_ SG_ 1015 MFS_LeftControl "Left Control";
CM_ SG_ 1015 MFS_CruiseOn_Off "Cruise control On Off";
CM_ SG_ 1015 MFS_Failure "Multi-Funtion Switch Failure";
CM_ SG_ 1015 MFS_ISAControl "ISA Control";
CM_ SG_ 1015 MFS_LKAControl "LKA Control";
CM_ SG_ 1015 MFS_CruiseGapDecrease "Cruise Gap Decrease";
CM_ SG_ 1015 MFS_CruiseSpeedDecrease "Cruise Speed Decrease";
CM_ SG_ 1015 MFS_CruiseSpeedIncrease "Cruise Speed Increase";
CM_ SG_ 1015 MFS_CruiseCancel "Cruise funtionality Cancel";
CM_ SG_ 1015 MFS_CruiseGapIncrease "Cruise Gap Increase";
CM_ SG_ 1017 MFS_Mode_Control "Control Mode ON or OFF";
CM_ SG_ 1017 MFS_MUTE_SPEAKER "mute speaker";
CM_ SG_ 1017 MFS_SONG_U "turn to Pre-item(song,phone number,FM/AM,etc.)";
CM_ SG_ 1017 MFS_SONG_D "turn to next-item(song,phone number,FM/AM,etc.)";
CM_ SG_ 1017 MFS_VOL_U "loudspeaker volume increase";
CM_ SG_ 1017 MFS_VOL_D "loudspeaker volume decrease";
CM_ SG_ 1284 MHU_sourceID "source ID";
CM_ SG_ 1284 MHU_CBV "CBV";
CM_ SG_ 1284 MHU_Data0 "Data0";
CM_ SG_ 1284 MHU_Data1 "Data1";
CM_ SG_ 1284 MHU_Data2 "Data2";
CM_ SG_ 1284 MHU_Data3 "Data3";
CM_ SG_ 1284 MHU_Data4 "Data4";
CM_ SG_ 1284 MHU_Data5 "Data5";
CM_ SG_ 1283 IPC_sourceID "source ID";
CM_ SG_ 1283 IPC_CBV "CBV";
CM_ SG_ 1283 IPC_Data0 "Data0";
CM_ SG_ 1283 IPC_Data1 "Data1";
CM_ SG_ 1283 IPC_Data2 "Data2";
CM_ SG_ 1283 IPC_Data3 "Data3";
CM_ SG_ 1283 IPC_Data4 "Data4";
CM_ SG_ 1283 IPC_Data5 "Data5";
CM_ SG_ 1282 GW_sourceID "source ID";
CM_ SG_ 1282 GW_CBV "CBV";
CM_ SG_ 1282 GW_Data0 "Data0";
CM_ SG_ 1282 GW_Data1 "Data1";
CM_ SG_ 1282 GW_Data2 "Data2";
CM_ SG_ 1282 GW_Data3 "Data3";
CM_ SG_ 1282 GW_Data4 "Data4";
CM_ SG_ 1282 GW_Data5 "Data5";
CM_ SG_ 1289 CCU_sourceID "source ID";
CM_ SG_ 1289 CCU_CBV "CBV";
CM_ SG_ 1289 CCU_Data0 "Data0";
CM_ SG_ 1289 CCU_Data1 "Data1";
CM_ SG_ 1289 CCU_Data2 "Data2";
CM_ SG_ 1289 CCU_Data3 "Data3";
CM_ SG_ 1289 CCU_Data4 "Data4";
CM_ SG_ 1289 CCU_Data5 "Data5";
CM_ SG_ 1668 MHU_DiagReqData0 "Data0";
CM_ SG_ 1668 MHU_DiagReqData1 "Data1";
CM_ SG_ 1668 MHU_DiagReqData2 "Data2";
CM_ SG_ 1668 MHU_DiagReqData3 "Data3";
CM_ SG_ 1668 MHU_DiagReqData4 "Data4";
CM_ SG_ 1668 MHU_DiagReqData5 "Data5";
CM_ SG_ 1668 MHU_DiagReqData6 "Data6";
CM_ SG_ 1668 MHU_DiagReqData7 "Data7";
CM_ SG_ 1540 MHU_DiagRespData0 "Data0";
CM_ SG_ 1540 MHU_DiagRespData1 "Data1";
CM_ SG_ 1540 MHU_DiagRespData2 "Data2";
CM_ SG_ 1540 MHU_DiagRespData3 "Data3";
CM_ SG_ 1540 MHU_DiagRespData4 "Data4";
CM_ SG_ 1540 MHU_DiagRespData5 "Data5";
CM_ SG_ 1540 MHU_DiagRespData6 "Data6";
CM_ SG_ 1540 MHU_DiagRespData7 "Data7";
CM_ SG_ 1667 IPC_DiagReqData0 "Data0";
CM_ SG_ 1667 IPC_DiagReqData1 "Data1";
CM_ SG_ 1667 IPC_DiagReqData2 "Data2";
CM_ SG_ 1667 IPC_DiagReqData3 "Data3";
CM_ SG_ 1667 IPC_DiagReqData4 "Data4";
CM_ SG_ 1667 IPC_DiagReqData5 "Data5";
CM_ SG_ 1667 IPC_DiagReqData6 "Data6";
CM_ SG_ 1667 IPC_DiagReqData7 "Data7";
CM_ SG_ 1539 IPC_DiagRespData0 "Data0";
CM_ SG_ 1539 IPC_DiagRespData1 "Data1";
CM_ SG_ 1539 IPC_DiagRespData2 "Data2";
CM_ SG_ 1539 IPC_DiagRespData3 "Data3";
CM_ SG_ 1539 IPC_DiagRespData4 "Data4";
CM_ SG_ 1539 IPC_DiagRespData5 "Data5";
CM_ SG_ 1539 IPC_DiagRespData6 "Data6";
CM_ SG_ 1539 IPC_DiagRespData7 "Data7";
CM_ SG_ 1673 CCU_DiagReqData0 "Data0";
CM_ SG_ 1673 CCU_DiagReqData1 "Data1";
CM_ SG_ 1673 CCU_DiagReqData2 "Data2";
CM_ SG_ 1673 CCU_DiagReqData3 "Data3";
CM_ SG_ 1673 CCU_DiagReqData4 "Data4";
CM_ SG_ 1673 CCU_DiagReqData5 "Data5";
CM_ SG_ 1673 CCU_DiagReqData6 "Data6";
CM_ SG_ 1673 CCU_DiagReqData7 "Data7";
CM_ SG_ 1545 CCU_DiagRespData0 "Data0";
CM_ SG_ 1545 CCU_DiagRespData1 "Data1";
CM_ SG_ 1545 CCU_DiagRespData2 "Data2";
CM_ SG_ 1545 CCU_DiagRespData3 "Data3";
CM_ SG_ 1545 CCU_DiagRespData4 "Data4";
CM_ SG_ 1545 CCU_DiagRespData5 "Data5";
CM_ SG_ 1545 CCU_DiagRespData6 "Data6";
CM_ SG_ 1545 CCU_DiagRespData7 "Data7";
CM_ SG_ 1791 GW_DiagFunctionalAddressingData0 "Data0";
CM_ SG_ 1791 GW_DiagFunctionalAddressingData1 "Data1";
CM_ SG_ 1791 GW_DiagFunctionalAddressingData2 "Data2";
CM_ SG_ 1791 GW_DiagFunctionalAddressingData3 "Data3";
CM_ SG_ 1791 GW_DiagFunctionalAddressingData4 "Data4";
CM_ SG_ 1791 GW_DiagFunctionalAddressingData5 "Data5";
CM_ SG_ 1791 GW_DiagFunctionalAddressingData6 "Data6";
CM_ SG_ 1791 GW_DiagFunctionalAddressingData7 "Data7";
CM_ SG_ 1691 EDS_DiagReqData0 "Data0";
CM_ SG_ 1691 EDS_DiagReqData1 "Data1";
CM_ SG_ 1691 EDS_DiagReqData2 "Data2";
CM_ SG_ 1691 EDS_DiagReqData3 "Data3";
CM_ SG_ 1691 EDS_DiagReqData4 "Data4";
CM_ SG_ 1691 EDS_DiagReqData5 "Data5";
CM_ SG_ 1691 EDS_DiagReqData6 "Data6";
CM_ SG_ 1691 EDS_DiagReqData7 "Data7";
CM_ SG_ 1563 EDS_DiagRespData0 "Data0";
CM_ SG_ 1563 EDS_DiagRespData1 "Data1";
CM_ SG_ 1563 EDS_DiagRespData2 "Data2";
CM_ SG_ 1563 EDS_DiagRespData3 "Data3";
CM_ SG_ 1563 EDS_DiagRespData4 "Data4";
CM_ SG_ 1563 EDS_DiagRespData5 "Data5";
CM_ SG_ 1563 EDS_DiagRespData6 "Data6";
CM_ SG_ 1563 EDS_DiagRespData7 "Data7";
CM_ SG_ 1708 VCU_DiagReqData0 "Data0";
CM_ SG_ 1708 VCU_DiagReqData1 "Data1";
CM_ SG_ 1708 VCU_DiagReqData2 "Data2";
CM_ SG_ 1708 VCU_DiagReqData3 "Data3";
CM_ SG_ 1708 VCU_DiagReqData4 "Data4";
CM_ SG_ 1708 VCU_DiagReqData5 "Data5";
CM_ SG_ 1708 VCU_DiagReqData6 "Data6";
CM_ SG_ 1708 VCU_DiagReqData7 "Data7";
CM_ SG_ 1580 VCU_DiagRespData0 "Data0";
CM_ SG_ 1580 VCU_DiagRespData1 "Data1";
CM_ SG_ 1580 VCU_DiagRespData2 "Data2";
CM_ SG_ 1580 VCU_DiagRespData3 "Data3";
CM_ SG_ 1580 VCU_DiagRespData4 "Data4";
CM_ SG_ 1580 VCU_DiagRespData5 "Data5";
CM_ SG_ 1580 VCU_DiagRespData6 "Data6";
CM_ SG_ 1580 VCU_DiagRespData7 "Data7";
CM_ SG_ 1725 PDU_DiagReqData0 "Data0";
CM_ SG_ 1725 PDU_DiagReqData1 "Data1";
CM_ SG_ 1725 PDU_DiagReqData2 "Data2";
CM_ SG_ 1725 PDU_DiagReqData3 "Data3";
CM_ SG_ 1725 PDU_DiagReqData4 "Data4";
CM_ SG_ 1725 PDU_DiagReqData5 "Data5";
CM_ SG_ 1725 PDU_DiagReqData6 "Data6";
CM_ SG_ 1725 PDU_DiagReqData7 "Data7";
CM_ SG_ 1597 PDU_DiagRespData0 "Data0";
CM_ SG_ 1597 PDU_DiagRespData1 "Data1";
CM_ SG_ 1597 PDU_DiagRespData2 "Data2";
CM_ SG_ 1597 PDU_DiagRespData3 "Data3";
CM_ SG_ 1597 PDU_DiagRespData4 "Data4";
CM_ SG_ 1597 PDU_DiagRespData5 "Data5";
CM_ SG_ 1597 PDU_DiagRespData6 "Data6";
CM_ SG_ 1597 PDU_DiagRespData7 "Data7";
CM_ SG_ 1683 BMS_DiagReqData0 "Data0";
CM_ SG_ 1683 BMS_DiagReqData1 "Data1";
CM_ SG_ 1683 BMS_DiagReqData2 "Data2";
CM_ SG_ 1683 BMS_DiagReqData3 "Data3";
CM_ SG_ 1683 BMS_DiagReqData4 "Data4";
CM_ SG_ 1683 BMS_DiagReqData5 "Data5";
CM_ SG_ 1683 BMS_DiagReqData6 "Data6";
CM_ SG_ 1683 BMS_DiagReqData7 "Data7";
CM_ SG_ 1555 BMS_DiagRespData0 "Data0";
CM_ SG_ 1555 BMS_DiagRespData1 "Data1";
CM_ SG_ 1555 BMS_DiagRespData2 "Data2";
CM_ SG_ 1555 BMS_DiagRespData3 "Data3";
CM_ SG_ 1555 BMS_DiagRespData4 "Data4";
CM_ SG_ 1555 BMS_DiagRespData5 "Data5";
CM_ SG_ 1555 BMS_DiagRespData6 "Data6";
CM_ SG_ 1555 BMS_DiagRespData7 "Data7";
CM_ SG_ 1781 EAC_DiagReqData0 "Data0";
CM_ SG_ 1781 EAC_DiagReqData1 "Data1";
CM_ SG_ 1781 EAC_DiagReqData2 "Data2";
CM_ SG_ 1781 EAC_DiagReqData3 "Data3";
CM_ SG_ 1781 EAC_DiagReqData4 "Data4";
CM_ SG_ 1781 EAC_DiagReqData5 "Data5";
CM_ SG_ 1781 EAC_DiagReqData6 "Data6";
CM_ SG_ 1781 EAC_DiagReqData7 "Data7";
CM_ SG_ 1653 EAC_DiagRespData0 "Data0";
CM_ SG_ 1653 EAC_DiagRespData1 "Data1";
CM_ SG_ 1653 EAC_DiagRespData2 "Data2";
CM_ SG_ 1653 EAC_DiagRespData3 "Data3";
CM_ SG_ 1653 EAC_DiagRespData4 "Data4";
CM_ SG_ 1653 EAC_DiagRespData5 "Data5";
CM_ SG_ 1653 EAC_DiagRespData6 "Data6";
CM_ SG_ 1653 EAC_DiagRespData7 "Data7";
CM_ SG_ 1695 EVCC_DiagReqData0 "Data0";
CM_ SG_ 1695 EVCC_DiagReqData1 "Data1";
CM_ SG_ 1695 EVCC_DiagReqData2 "Data2";
CM_ SG_ 1695 EVCC_DiagReqData3 "Data3";
CM_ SG_ 1695 EVCC_DiagReqData4 "Data4";
CM_ SG_ 1695 EVCC_DiagReqData5 "Data5";
CM_ SG_ 1695 EVCC_DiagReqData6 "Data6";
CM_ SG_ 1695 EVCC_DiagReqData7 "Data7";
CM_ SG_ 1567 EVCC_DiagRespData0 "Data0";
CM_ SG_ 1567 EVCC_DiagRespData1 "Data1";
CM_ SG_ 1567 EVCC_DiagRespData2 "Data2";
CM_ SG_ 1567 EVCC_DiagRespData3 "Data3";
CM_ SG_ 1567 EVCC_DiagRespData4 "Data4";
CM_ SG_ 1567 EVCC_DiagRespData5 "Data5";
CM_ SG_ 1567 EVCC_DiagRespData6 "Data6";
CM_ SG_ 1567 EVCC_DiagRespData7 "Data7";
CM_ SG_ 1705 ESC_DiagReqData0 "Data0";
CM_ SG_ 1705 ESC_DiagReqData1 "Data1";
CM_ SG_ 1705 ESC_DiagReqData2 "Data2";
CM_ SG_ 1705 ESC_DiagReqData3 "Data3";
CM_ SG_ 1705 ESC_DiagReqData4 "Data4";
CM_ SG_ 1705 ESC_DiagReqData5 "Data5";
CM_ SG_ 1705 ESC_DiagReqData6 "Data6";
CM_ SG_ 1705 ESC_DiagReqData7 "Data7";
CM_ SG_ 1577 ESC_DiagRespData0 "Data0";
CM_ SG_ 1577 ESC_DiagRespData1 "Data1";
CM_ SG_ 1577 ESC_DiagRespData2 "Data2";
CM_ SG_ 1577 ESC_DiagRespData3 "Data3";
CM_ SG_ 1577 ESC_DiagRespData4 "Data4";
CM_ SG_ 1577 ESC_DiagRespData5 "Data5";
CM_ SG_ 1577 ESC_DiagRespData6 "Data6";
CM_ SG_ 1577 ESC_DiagRespData7 "Data7";
CM_ SG_ 1704 EPS_DiagReqData0 "Data0";
CM_ SG_ 1704 EPS_DiagReqData1 "Data1";
CM_ SG_ 1704 EPS_DiagReqData2 "Data2";
CM_ SG_ 1704 EPS_DiagReqData3 "Data3";
CM_ SG_ 1704 EPS_DiagReqData4 "Data4";
CM_ SG_ 1704 EPS_DiagReqData5 "Data5";
CM_ SG_ 1704 EPS_DiagReqData6 "Data6";
CM_ SG_ 1704 EPS_DiagReqData7 "Data7";
CM_ SG_ 1576 EPS_DiagRespData0 "Data0";
CM_ SG_ 1576 EPS_DiagRespData1 "Data1";
CM_ SG_ 1576 EPS_DiagRespData2 "Data2";
CM_ SG_ 1576 EPS_DiagRespData3 "Data3";
CM_ SG_ 1576 EPS_DiagRespData4 "Data4";
CM_ SG_ 1576 EPS_DiagRespData5 "Data5";
CM_ SG_ 1576 EPS_DiagRespData6 "Data6";
CM_ SG_ 1576 EPS_DiagRespData7 "Data7";
CM_ SG_ 1680 EKS_DiagReqData0 "Data0";
CM_ SG_ 1680 EKS_DiagReqData1 "Data1";
CM_ SG_ 1680 EKS_DiagReqData2 "Data2";
CM_ SG_ 1680 EKS_DiagReqData3 "Data3";
CM_ SG_ 1680 EKS_DiagReqData4 "Data4";
CM_ SG_ 1680 EKS_DiagReqData5 "Data5";
CM_ SG_ 1680 EKS_DiagReqData6 "Data6";
CM_ SG_ 1680 EKS_DiagReqData7 "Data7";
CM_ SG_ 1552 EKS_DiagRespData0 "Data0";
CM_ SG_ 1552 EKS_DiagRespData1 "Data1";
CM_ SG_ 1552 EKS_DiagRespData2 "Data2";
CM_ SG_ 1552 EKS_DiagRespData3 "Data3";
CM_ SG_ 1552 EKS_DiagRespData4 "Data4";
CM_ SG_ 1552 EKS_DiagRespData5 "Data5";
CM_ SG_ 1552 EKS_DiagRespData6 "Data6";
CM_ SG_ 1552 EKS_DiagRespData7 "Data7";
CM_ SG_ 2018 IPC_DiagReqData0 "Data0";
CM_ SG_ 2018 IPC_DiagReqData1 "Data1";
CM_ SG_ 2018 IPC_DiagReqData2 "Data2";
CM_ SG_ 2018 IPC_DiagReqData3 "Data3";
CM_ SG_ 2018 IPC_DiagReqData4 "Data4";
CM_ SG_ 2018 IPC_DiagReqData5 "Data5";
CM_ SG_ 2018 IPC_DiagReqData6 "Data6";
CM_ SG_ 2018 IPC_DiagReqData7 "Data7";
CM_ SG_ 2026 IPC_DiagRespData0 "Data0";
CM_ SG_ 2026 IPC_DiagRespData1 "Data1";
CM_ SG_ 2026 IPC_DiagRespData2 "Data2";
CM_ SG_ 2026 IPC_DiagRespData3 "Data3";
CM_ SG_ 2026 IPC_DiagRespData4 "Data4";
CM_ SG_ 2026 IPC_DiagRespData5 "Data5";
CM_ SG_ 2026 IPC_DiagRespData6 "Data6";
CM_ SG_ 2026 IPC_DiagRespData7 "Data7";
CM_ SG_ 1666 XGW_DiagReqData0 "Data0";
CM_ SG_ 1666 XGW_DiagReqData1 "Data1";
CM_ SG_ 1666 XGW_DiagReqData2 "Data2";
CM_ SG_ 1666 XGW_DiagReqData3 "Data3";
CM_ SG_ 1666 XGW_DiagReqData4 "Data4";
CM_ SG_ 1666 XGW_DiagReqData5 "Data5";
CM_ SG_ 1666 XGW_DiagReqData6 "Data6";
CM_ SG_ 1666 XGW_DiagReqData7 "Data7";
CM_ SG_ 1538 XGW_DiagRespData0 "Data0";
CM_ SG_ 1538 XGW_DiagRespData1 "Data1";
CM_ SG_ 1538 XGW_DiagRespData2 "Data2";
CM_ SG_ 1538 XGW_DiagRespData3 "Data3";
CM_ SG_ 1538 XGW_DiagRespData4 "Data4";
CM_ SG_ 1538 XGW_DiagRespData5 "Data5";
CM_ SG_ 1538 XGW_DiagRespData6 "Data6";
CM_ SG_ 1538 XGW_DiagRespData7 "Data7";
CM_ SG_ 2019 CCU_DiagReqData0 "Data0";
CM_ SG_ 2019 CCU_DiagReqData1 "Data1";
CM_ SG_ 2019 CCU_DiagReqData2 "Data2";
CM_ SG_ 2019 CCU_DiagReqData3 "Data3";
CM_ SG_ 2019 CCU_DiagReqData4 "Data4";
CM_ SG_ 2019 CCU_DiagReqData5 "Data5";
CM_ SG_ 2019 CCU_DiagReqData6 "Data6";
CM_ SG_ 2019 CCU_DiagReqData7 "Data7";
CM_ SG_ 2027 CCU_DiagRespData0 "Data0";
CM_ SG_ 2027 CCU_DiagRespData1 "Data1";
CM_ SG_ 2027 CCU_DiagRespData2 "Data2";
CM_ SG_ 2027 CCU_DiagRespData3 "Data3";
CM_ SG_ 2027 CCU_DiagRespData4 "Data4";
CM_ SG_ 2027 CCU_DiagRespData5 "Data5";
CM_ SG_ 2027 CCU_DiagRespData6 "Data6";
CM_ SG_ 2027 CCU_DiagRespData7 "Data7";
CM_ SG_ 1672 ACM_DiagReqData0 "Data0";
CM_ SG_ 1672 ACM_DiagReqData1 "Data1";
CM_ SG_ 1672 ACM_DiagReqData2 "Data2";
CM_ SG_ 1672 ACM_DiagReqData3 "Data3";
CM_ SG_ 1672 ACM_DiagReqData4 "Data4";
CM_ SG_ 1672 ACM_DiagReqData5 "Data5";
CM_ SG_ 1672 ACM_DiagReqData6 "Data6";
CM_ SG_ 1672 ACM_DiagReqData7 "Data7";
CM_ SG_ 1544 ACM_DiagRespData0 "Data0";
CM_ SG_ 1544 ACM_DiagRespData1 "Data1";
CM_ SG_ 1544 ACM_DiagRespData2 "Data2";
CM_ SG_ 1544 ACM_DiagRespData3 "Data3";
CM_ SG_ 1544 ACM_DiagRespData4 "Data4";
CM_ SG_ 1544 ACM_DiagRespData5 "Data5";
CM_ SG_ 1544 ACM_DiagRespData6 "Data6";
CM_ SG_ 1544 ACM_DiagRespData7 "Data7";
CM_ SG_ 1665 BCM_DiagReqData0 "Data0";
CM_ SG_ 1665 BCM_DiagReqData1 "Data1";
CM_ SG_ 1665 BCM_DiagReqData2 "Data2";
CM_ SG_ 1665 BCM_DiagReqData3 "Data3";
CM_ SG_ 1665 BCM_DiagReqData4 "Data4";
CM_ SG_ 1665 BCM_DiagReqData5 "Data5";
CM_ SG_ 1665 BCM_DiagReqData6 "Data6";
CM_ SG_ 1665 BCM_DiagReqData7 "Data7";
CM_ SG_ 1537 BCM_DiagRespData0 "Data0";
CM_ SG_ 1537 BCM_DiagRespData1 "Data1";
CM_ SG_ 1537 BCM_DiagRespData2 "Data2";
CM_ SG_ 1537 BCM_DiagRespData3 "Data3";
CM_ SG_ 1537 BCM_DiagRespData4 "Data4";
CM_ SG_ 1537 BCM_DiagRespData5 "Data5";
CM_ SG_ 1537 BCM_DiagRespData6 "Data6";
CM_ SG_ 1537 BCM_DiagRespData7 "Data7";
CM_ SG_ 1728 BSD_DiagReq_Data0 "Data0";
CM_ SG_ 1728 BSD_DiagReq_Data1 "Data1";
CM_ SG_ 1728 BSD_DiagReq_Data2 "Data2";
CM_ SG_ 1728 BSD_DiagReq_Data3 "Data3";
CM_ SG_ 1728 BSD_DiagReq_Data4 "Data4";
CM_ SG_ 1728 BSD_DiagReq_Data5 "Data5";
CM_ SG_ 1728 BSD_DiagReq_Data6 "Data6";
CM_ SG_ 1728 BSD_DiagReq_Data7 "Data7";
CM_ SG_ 1600 BSD_DiagResp_Data0 "Data0";
CM_ SG_ 1600 BSD_DiagResp_Data1 "Data1";
CM_ SG_ 1600 BSD_DiagResp_Data2 "Data2";
CM_ SG_ 1600 BSD_DiagResp_Data3 "Data3";
CM_ SG_ 1600 BSD_DiagResp_Data4 "Data4";
CM_ SG_ 1600 BSD_DiagResp_Data5 "Data5";
CM_ SG_ 1600 BSD_DiagResp_Data6 "Data6";
CM_ SG_ 1600 BSD_DiagResp_Data7 "Data7";
CM_ SG_ 2030 GW_DiagFunctionalAddressingData0 "Data0";
CM_ SG_ 2030 GW_DiagFunctionalAddressingData1 "Data1";
CM_ SG_ 2030 GW_DiagFunctionalAddressingData2 "Data2";
CM_ SG_ 2030 GW_DiagFunctionalAddressingData3 "Data3";
CM_ SG_ 2030 GW_DiagFunctionalAddressingData4 "Data4";
CM_ SG_ 2030 GW_DiagFunctionalAddressingData5 "Data5";
CM_ SG_ 2030 GW_DiagFunctionalAddressingData6 "Data6";
CM_ SG_ 2030 GW_DiagFunctionalAddressingData7 "Data7";
BA_DEF_ BO_  "DiagRequest" ENUM  "No","Yes";
BA_DEF_ BO_  "DiagResponse" ENUM  "No","Yes";
BA_DEF_ BO_  "DiagState" ENUM  "No","Yes";
BA_DEF_ BO_  "GenMsgCycleTime" INT 0 65535;
BA_DEF_ BO_  "GenMsgCycleTimeFast" INT 0 65535;
BA_DEF_ BO_  "GenMsgDelayTime" INT 0 65535;
BA_DEF_ BO_  "GenMsgILSupport" ENUM  "No","Yes";
BA_DEF_ BO_  "GenMsgNrOfRepetition" INT 0 65535;
BA_DEF_ BO_  "GenMsgSendType" ENUM  "Cycle","Event","IfActive","CE","CA";
BA_DEF_ BO_  "NmAsrMessage" ENUM  "No","Yes";
BA_DEF_ BO_  "NmMessage" ENUM  "No","Yes";
BA_DEF_ SG_  "GenSigSendType" ENUM  "Cycle","OnWrite","OnWriteWithRepetition","OnChange","OnChangeWithRepetition","IfActive","IfActiveWithRepetition";
BA_DEF_ SG_  "GenSigStartValue" INT 0 2147483647;
BA_DEF_ SG_  "GenSigInvalidValue" INT 0 2147483647;
BA_DEF_ SG_  "GenSigInactiveValue" INT 0 2147483647;
BA_DEF_ SG_  "SystemSignalLongSymbol" STRING ;
BA_DEF_DEF_  "DiagRequest" "No";
BA_DEF_DEF_  "DiagResponse" "No";
BA_DEF_DEF_  "DiagState" "No";
BA_DEF_DEF_  "GenMsgCycleTime" 0;
BA_DEF_DEF_  "GenMsgCycleTimeFast" 0;
BA_DEF_DEF_  "GenMsgDelayTime" 0;
BA_DEF_DEF_  "GenMsgILSupport" "Yes";
BA_DEF_DEF_  "GenMsgNrOfRepetition" 0;
BA_DEF_DEF_  "GenMsgSendType" "";
BA_DEF_DEF_  "NmAsrMessage" "No";
BA_DEF_DEF_  "NmMessage" "No";
BA_DEF_DEF_  "GenSigSendType" "";
BA_DEF_DEF_  "GenSigStartValue" 0;
BA_DEF_DEF_  "GenSigInvalidValue" 0;
BA_DEF_DEF_  "GenSigInactiveValue" 0;
BA_DEF_DEF_  "SystemSignalLongSymbol" "";
BA_ "GenMsgCycleTime" BO_ 261 100;
BA_ "GenMsgSendType" BO_ 261 0;
BA_ "GenMsgCycleTime" BO_ 262 20;
BA_ "GenMsgSendType" BO_ 262 0;
BA_ "GenMsgCycleTime" BO_ 266 100;
BA_ "GenMsgSendType" BO_ 266 0;
BA_ "GenMsgCycleTime" BO_ 274 100;
BA_ "GenMsgSendType" BO_ 274 0;
BA_ "GenMsgCycleTime" BO_ 303 100;
BA_ "GenMsgSendType" BO_ 303 0;
BA_ "GenMsgCycleTime" BO_ 283 20;
BA_ "GenMsgSendType" BO_ 283 0;
BA_ "GenMsgCycleTime" BO_ 529 20;
BA_ "GenMsgSendType" BO_ 529 0;
BA_ "GenMsgCycleTime" BO_ 270 100;
BA_ "GenMsgSendType" BO_ 270 0;
BA_ "GenMsgCycleTime" BO_ 769 200;
BA_ "GenMsgSendType" BO_ 769 0;
BA_ "GenMsgCycleTime" BO_ 1053 100;
BA_ "GenMsgCycleTimeFast" BO_ 1053 20;
BA_ "GenMsgNrOfRepetition" BO_ 1053 5;
BA_ "GenMsgSendType" BO_ 1053 3;
BA_ "GenMsgCycleTime" BO_ 263 20;
BA_ "GenMsgSendType" BO_ 263 0;
BA_ "GenMsgCycleTime" BO_ 268 100;
BA_ "GenMsgSendType" BO_ 268 0;
BA_ "GenMsgCycleTime" BO_ 272 100;
BA_ "GenMsgSendType" BO_ 272 0;
BA_ "GenMsgCycleTime" BO_ 525 100;
BA_ "GenMsgSendType" BO_ 525 0;
BA_ "GenMsgCycleTime" BO_ 834 10;
BA_ "GenMsgSendType" BO_ 834 0;
BA_ "GenMsgCycleTime" BO_ 306 20;
BA_ "GenMsgSendType" BO_ 306 0;
BA_ "GenMsgCycleTime" BO_ 322 20;
BA_ "GenMsgSendType" BO_ 322 0;
BA_ "GenMsgCycleTime" BO_ 994 20;
BA_ "GenMsgSendType" BO_ 994 0;
BA_ "GenMsgCycleTime" BO_ 1154 50;
BA_ "GenMsgSendType" BO_ 1154 0;
BA_ "GenMsgCycleTime" BO_ 496 20;
BA_ "GenMsgSendType" BO_ 496 0;
BA_ "GenMsgCycleTime" BO_ 673 100;
BA_ "GenMsgSendType" BO_ 673 0;
BA_ "GenMsgCycleTime" BO_ 792 50;
BA_ "GenMsgSendType" BO_ 792 0;
BA_ "GenMsgCycleTime" BO_ 937 20;
BA_ "GenMsgSendType" BO_ 937 0;
BA_ "GenMsgCycleTime" BO_ 889 50;
BA_ "GenMsgSendType" BO_ 889 0;
BA_ "GenMsgCycleTime" BO_ 441 50;
BA_ "GenMsgSendType" BO_ 441 0;
BA_ "GenMsgCycleTime" BO_ 425 20;
BA_ "GenMsgSendType" BO_ 425 0;
BA_ "GenMsgCycleTime" BO_ 1008 20;
BA_ "GenMsgSendType" BO_ 1008 0;
BA_ "GenMsgCycleTime" BO_ 992 100;
BA_ "GenMsgSendType" BO_ 992 0;
BA_ "GenMsgCycleTime" BO_ 745 50;
BA_ "GenMsgSendType" BO_ 745 0;
BA_ "GenMsgCycleTime" BO_ 534 50;
BA_ "GenMsgSendType" BO_ 534 0;
BA_ "GenMsgCycleTime" BO_ 533 50;
BA_ "GenMsgSendType" BO_ 533 0;
BA_ "GenMsgCycleTime" BO_ 1171 1000;
BA_ "GenMsgSendType" BO_ 1171 0;
BA_ "GenMsgCycleTime" BO_ 372 20;
BA_ "GenMsgSendType" BO_ 372 0;
BA_ "GenMsgCycleTime" BO_ 374 50;
BA_ "GenMsgSendType" BO_ 374 0;
BA_ "GenMsgCycleTime" BO_ 523 50;
BA_ "GenMsgSendType" BO_ 523 0;
BA_ "GenMsgCycleTime" BO_ 504 10;
BA_ "GenMsgSendType" BO_ 504 0;
BA_ "GenMsgCycleTime" BO_ 1015 1000;
BA_ "GenMsgCycleTimeFast" BO_ 1015 50;
BA_ "GenMsgNrOfRepetition" BO_ 1015 5;
BA_ "GenMsgSendType" BO_ 1015 3;
BA_ "GenMsgCycleTime" BO_ 1017 1000;
BA_ "GenMsgCycleTimeFast" BO_ 1017 50;
BA_ "GenMsgNrOfRepetition" BO_ 1017 5;
BA_ "GenMsgSendType" BO_ 1017 3;
BA_ "NmMessage" BO_ 1284 1;
BA_ "NmAsrMessage" BO_ 1284 1;
BA_ "GenMsgCycleTime" BO_ 1284 640;
BA_ "GenMsgSendType" BO_ 1284 2;
BA_ "NmMessage" BO_ 1283 1;
BA_ "NmAsrMessage" BO_ 1283 1;
BA_ "GenMsgCycleTime" BO_ 1283 640;
BA_ "GenMsgSendType" BO_ 1283 2;
BA_ "NmMessage" BO_ 1282 1;
BA_ "NmAsrMessage" BO_ 1282 1;
BA_ "GenMsgCycleTime" BO_ 1282 640;
BA_ "GenMsgSendType" BO_ 1282 2;
BA_ "NmMessage" BO_ 1289 1;
BA_ "NmAsrMessage" BO_ 1289 1;
BA_ "GenMsgCycleTime" BO_ 1289 640;
BA_ "GenMsgSendType" BO_ 1289 2;
BA_ "DiagRequest" BO_ 1668 1;
BA_ "GenMsgSendType" BO_ 1668 1;
BA_ "DiagResponse" BO_ 1540 1;
BA_ "GenMsgSendType" BO_ 1540 1;
BA_ "DiagRequest" BO_ 1667 1;
BA_ "GenMsgSendType" BO_ 1667 1;
BA_ "DiagResponse" BO_ 1539 1;
BA_ "GenMsgSendType" BO_ 1539 1;
BA_ "DiagRequest" BO_ 1673 1;
BA_ "GenMsgSendType" BO_ 1673 1;
BA_ "DiagResponse" BO_ 1545 1;
BA_ "GenMsgSendType" BO_ 1545 1;
BA_ "DiagState" BO_ 1791 1;
BA_ "GenMsgSendType" BO_ 1791 1;
BA_ "DiagRequest" BO_ 1691 1;
BA_ "GenMsgSendType" BO_ 1691 1;
BA_ "DiagResponse" BO_ 1563 1;
BA_ "GenMsgSendType" BO_ 1563 1;
BA_ "DiagRequest" BO_ 1708 1;
BA_ "GenMsgSendType" BO_ 1708 1;
BA_ "DiagResponse" BO_ 1580 1;
BA_ "GenMsgSendType" BO_ 1580 1;
BA_ "DiagRequest" BO_ 1725 1;
BA_ "GenMsgSendType" BO_ 1725 1;
BA_ "DiagResponse" BO_ 1597 1;
BA_ "GenMsgSendType" BO_ 1597 1;
BA_ "DiagRequest" BO_ 1683 1;
BA_ "GenMsgSendType" BO_ 1683 1;
BA_ "DiagResponse" BO_ 1555 1;
BA_ "GenMsgSendType" BO_ 1555 1;
BA_ "DiagRequest" BO_ 1781 1;
BA_ "GenMsgSendType" BO_ 1781 1;
BA_ "DiagResponse" BO_ 1653 1;
BA_ "GenMsgSendType" BO_ 1653 1;
BA_ "DiagRequest" BO_ 1695 1;
BA_ "GenMsgSendType" BO_ 1695 1;
BA_ "DiagResponse" BO_ 1567 1;
BA_ "GenMsgSendType" BO_ 1567 1;
BA_ "DiagRequest" BO_ 1705 1;
BA_ "GenMsgSendType" BO_ 1705 1;
BA_ "DiagResponse" BO_ 1577 1;
BA_ "GenMsgSendType" BO_ 1577 1;
BA_ "DiagRequest" BO_ 1704 1;
BA_ "GenMsgSendType" BO_ 1704 1;
BA_ "DiagResponse" BO_ 1576 1;
BA_ "GenMsgSendType" BO_ 1576 1;
BA_ "DiagRequest" BO_ 1680 1;
BA_ "GenMsgSendType" BO_ 1680 1;
BA_ "DiagResponse" BO_ 1552 1;
BA_ "GenMsgSendType" BO_ 1552 1;
BA_ "DiagRequest" BO_ 2018 1;
BA_ "GenMsgSendType" BO_ 2018 1;
BA_ "DiagResponse" BO_ 2026 1;
BA_ "GenMsgSendType" BO_ 2026 1;
BA_ "DiagRequest" BO_ 1666 1;
BA_ "GenMsgSendType" BO_ 1666 1;
BA_ "DiagResponse" BO_ 1538 1;
BA_ "GenMsgSendType" BO_ 1538 1;
BA_ "DiagRequest" BO_ 2019 1;
BA_ "GenMsgSendType" BO_ 2019 1;
BA_ "DiagResponse" BO_ 2027 1;
BA_ "GenMsgSendType" BO_ 2027 1;
BA_ "DiagRequest" BO_ 1672 1;
BA_ "GenMsgSendType" BO_ 1672 1;
BA_ "DiagResponse" BO_ 1544 1;
BA_ "GenMsgSendType" BO_ 1544 1;
BA_ "DiagRequest" BO_ 1665 1;
BA_ "GenMsgSendType" BO_ 1665 1;
BA_ "DiagResponse" BO_ 1537 1;
BA_ "GenMsgSendType" BO_ 1537 1;
BA_ "DiagRequest" BO_ 1728 1;
BA_ "GenMsgSendType" BO_ 1728 1;
BA_ "DiagResponse" BO_ 1600 1;
BA_ "GenMsgSendType" BO_ 1600 1;
BA_ "DiagRequest" BO_ 2030 1;
BA_ "GenMsgSendType" BO_ 2030 1;
BA_ "GenSigSendType" SG_ 261 Checksum_0x105 0;
BA_ "GenSigInvalidValue" SG_ 261 Rolling_Counter_0x105 15;
BA_ "GenSigSendType" SG_ 261 Rolling_Counter_0x105 0;
BA_ "GenSigSendType" SG_ 261 BCM_STAT_TrunkAjar 0;
BA_ "GenSigSendType" SG_ 261 BCM_STAT_DoorAjarDriver 0;
BA_ "GenSigSendType" SG_ 261 BCM_STAT_DoorAjarPassenger 0;
BA_ "GenSigSendType" SG_ 261 BCM_STAT_DoorAjarRL 0;
BA_ "GenSigSendType" SG_ 261 BCM_STAT_DoorAjarRR 0;
BA_ "GenSigSendType" SG_ 261 BCM_STAT_BonnetAjar_reserved 0;
BA_ "GenSigSendType" SG_ 262 Checksum_0x106 0;
BA_ "GenSigInvalidValue" SG_ 262 Rolling_Counter_0x106 15;
BA_ "GenSigSendType" SG_ 262 Rolling_Counter_0x106 0;
BA_ "GenSigSendType" SG_ 262 BCM_HighBeamSts 0;
BA_ "GenSigSendType" SG_ 262 BCM_LowBeamSts 0;
BA_ "GenSigSendType" SG_ 262 BCM_PosLmpSts 0;
BA_ "GenSigSendType" SG_ 262 BCM_TurnIndicatorSts 0;
BA_ "GenSigSendType" SG_ 262 BCM_DayRunningLampSts_reserved 0;
BA_ "GenSigSendType" SG_ 262 BCM_ReverseLightSts 0;
BA_ "GenSigSendType" SG_ 262 BCM_StopLightSts 0;
BA_ "GenSigSendType" SG_ 262 BCM_Fr_Dimming_dome_lampSts 0;
BA_ "GenSigSendType" SG_ 262 BCM_Heated_rearglass 0;
BA_ "GenSigSendType" SG_ 262 BCM_BsdLightSts 0;
BA_ "GenSigStartValue" SG_ 262 BCM_STAT_LightActivation 7;
BA_ "GenSigSendType" SG_ 262 BCM_STAT_LightActivation 0;
BA_ "GenSigStartValue" SG_ 262 BCM_STAT_InteriorLight 3;
BA_ "GenSigSendType" SG_ 262 BCM_STAT_InteriorLight 0;
BA_ "GenSigSendType" SG_ 266 Checksum_0x10a 0;
BA_ "GenSigInvalidValue" SG_ 266 Rolling_Counter_0x10a 15;
BA_ "GenSigSendType" SG_ 266 Rolling_Counter_0x10a 0;
BA_ "GenSigSendType" SG_ 266 BCM_LVTop_up 0;
BA_ "GenSigStartValue" SG_ 266 Ubatt_Reserved 9000;
BA_ "GenSigInvalidValue" SG_ 266 Ubatt_Reserved 16383;
BA_ "GenSigSendType" SG_ 266 Ubatt_Reserved 0;
BA_ "GenSigSendType" SG_ 274 Checksum_0x112 0;
BA_ "GenSigInvalidValue" SG_ 274 Rolling_Counter_0x112 15;
BA_ "GenSigSendType" SG_ 274 Rolling_Counter_0x112 0;
BA_ "GenSigSendType" SG_ 274 STAT_Terminal 0;
BA_ "GenSigStartValue" SG_ 274 STAT_CL30s_L_Reserved 3;
BA_ "GenSigSendType" SG_ 274 STAT_CL30s_L_Reserved 0;
BA_ "GenSigSendType" SG_ 303 Checksum_0x12f 0;
BA_ "GenSigInvalidValue" SG_ 303 Rolling_Counter_0x12f 15;
BA_ "GenSigSendType" SG_ 303 Rolling_Counter_0x12f 0;
BA_ "GenSigSendType" SG_ 303 ST_KL_KEY_VLD 0;
BA_ "GenSigSendType" SG_ 303 ST_SSP 0;
BA_ "GenSigInvalidValue" SG_ 303 BCM_IMMO_Sts 2;
BA_ "GenSigSendType" SG_ 303 BCM_IMMO_Sts 0;
BA_ "GenSigSendType" SG_ 283 BCM_ACCRelayOutputSts 0;
BA_ "GenSigSendType" SG_ 283 BCM_IGN1RelayOutputSts 0;
BA_ "GenSigSendType" SG_ 283 BCM_ACCRelayFalutSts 0;
BA_ "GenSigSendType" SG_ 283 BCM_IGN1RelayFalutSts 0;
BA_ "GenSigSendType" SG_ 283 BCM_KEY_MatchSts 0;
BA_ "GenSigSendType" SG_ 529 PEPS_Lock_IGNNotOff_Alert 0;
BA_ "GenSigSendType" SG_ 529 PEPS_CID_NotInside_Alert 0;
BA_ "GenSigSendType" SG_ 529 PEPS_CID_Left_Alert 0;
BA_ "GenSigSendType" SG_ 529 PEPS_RMKey_BatteryLow_Alert 0;
BA_ "GenSigSendType" SG_ 529 PEPS_PressBrakePedal_Alert 0;
BA_ "GenSigSendType" SG_ 529 PEPS_Shift_Position_Alert 0;
BA_ "GenSigSendType" SG_ 529 PEPS_Lock_KeyInside_Alert 0;
BA_ "GenSigInvalidValue" SG_ 529 PEPS_EmergencyStop_Reserved 3;
BA_ "GenSigSendType" SG_ 529 PEPS_EmergencyStop_Reserved 0;
BA_ "GenSigSendType" SG_ 529 PEPS_CID_NotIndenfied_Alert 0;
BA_ "GenSigSendType" SG_ 529 BCM_Positionlight_reminder 0;
BA_ "GenSigSendType" SG_ 270 RemoteAccessKey 0;
BA_ "GenSigSendType" SG_ 270 PassiveAccessTrunk 0;
BA_ "GenSigSendType" SG_ 270 BCM_CurrentValid_FOB 0;
BA_ "GenSigSendType" SG_ 769 VOD_Block 0;
BA_ "GenSigSendType" SG_ 769 VOD_UpdateFlag 0;
BA_ "GenSigStartValue" SG_ 769 VOD_Byte1 255;
BA_ "GenSigSendType" SG_ 769 VOD_Byte1 0;
BA_ "GenSigStartValue" SG_ 769 VOD_Byte2 255;
BA_ "GenSigSendType" SG_ 769 VOD_Byte2 0;
BA_ "GenSigStartValue" SG_ 769 VOD_Byte3 255;
BA_ "GenSigSendType" SG_ 769 VOD_Byte3 0;
BA_ "GenSigStartValue" SG_ 769 VOD_Byte4 255;
BA_ "GenSigSendType" SG_ 769 VOD_Byte4 0;
BA_ "GenSigStartValue" SG_ 769 VOD_Byte5 255;
BA_ "GenSigSendType" SG_ 769 VOD_Byte5 0;
BA_ "GenSigStartValue" SG_ 769 VOD_Byte6 255;
BA_ "GenSigSendType" SG_ 769 VOD_Byte6 0;
BA_ "GenSigStartValue" SG_ 769 VOD_Byte7 255;
BA_ "GenSigSendType" SG_ 769 VOD_Byte7 0;
BA_ "GenSigStartValue" SG_ 1053 BCM_STAT_RemoteLockFeedback 1;
BA_ "GenSigInvalidValue" SG_ 1053 BCM_STAT_RemoteLockFeedback 7;
BA_ "GenSigSendType" SG_ 1053 BCM_STAT_RemoteLockFeedback 2;
BA_ "GenSigStartValue" SG_ 1053 BCM_STAT_RemoteDoorUnlock_reserv 3;
BA_ "GenSigSendType" SG_ 1053 BCM_STAT_RemoteDoorUnlock_reserv 2;
BA_ "SystemSignalLongSymbol" SG_ 1053 BCM_STAT_RemoteDoorUnlock_reserv "BCM_STAT_RemoteDoorUnlock_reserved";
BA_ "GenSigStartValue" SG_ 1053 BCM_STAT_AutoDoorUnlock 1;
BA_ "GenSigInvalidValue" SG_ 1053 BCM_STAT_AutoDoorUnlock 3;
BA_ "GenSigSendType" SG_ 1053 BCM_STAT_AutoDoorUnlock 2;
BA_ "GenSigStartValue" SG_ 1053 BCM_STAT_DoorSpeedLock 1;
BA_ "GenSigInvalidValue" SG_ 1053 BCM_STAT_DoorSpeedLock 7;
BA_ "GenSigSendType" SG_ 1053 BCM_STAT_DoorSpeedLock 2;
BA_ "GenSigStartValue" SG_ 1053 BCM_STAT_DayTimeRunningLight_res 1;
BA_ "GenSigInvalidValue" SG_ 1053 BCM_STAT_DayTimeRunningLight_res 3;
BA_ "GenSigSendType" SG_ 1053 BCM_STAT_DayTimeRunningLight_res 2;
BA_ "SystemSignalLongSymbol" SG_ 1053 BCM_STAT_DayTimeRunningLight_res "BCM_STAT_DayTimeRunningLight_reserved";
BA_ "GenSigStartValue" SG_ 1053 BCM_STAT_AntiTheftMode 3;
BA_ "GenSigInvalidValue" SG_ 1053 BCM_STAT_AntiTheftMode 7;
BA_ "GenSigSendType" SG_ 1053 BCM_STAT_AntiTheftMode 2;
BA_ "GenSigSendType" SG_ 1053 BCM_FOBID_userprofile_link 2;
BA_ "GenSigInvalidValue" SG_ 1053 BCM_feedback_FollowMeHomeTime 7;
BA_ "GenSigSendType" SG_ 1053 BCM_feedback_FollowMeHomeTime 2;
BA_ "GenSigSendType" SG_ 263 Checksum_0x107 0;
BA_ "GenSigInvalidValue" SG_ 263 Rolling_Counter_0x107 15;
BA_ "GenSigSendType" SG_ 263 Rolling_Counter_0x107 0;
BA_ "GenSigSendType" SG_ 263 STAT_ATWS 0;
BA_ "GenSigSendType" SG_ 263 STAT_DoorLockDriver 0;
BA_ "GenSigSendType" SG_ 268 Checksum_0x10C 0;
BA_ "GenSigInvalidValue" SG_ 268 Rolling_Counter_0x10C 15;
BA_ "GenSigSendType" SG_ 268 Rolling_Counter_0x10C 0;
BA_ "GenSigInvalidValue" SG_ 268 BCM_TboxAuthStatus 3;
BA_ "GenSigSendType" SG_ 268 BCM_TboxAuthStatus 0;
BA_ "GenSigSendType" SG_ 268 BCM_RandomNum32bit 0;
BA_ "GenSigSendType" SG_ 272 Checksum_0x110 0;
BA_ "GenSigInvalidValue" SG_ 272 Rolling_Counter_0x110 15;
BA_ "GenSigSendType" SG_ 272 Rolling_Counter_0x110 0;
BA_ "GenSigInvalidValue" SG_ 272 BCM_APM_FLWIN_Postion 7;
BA_ "GenSigSendType" SG_ 272 BCM_APM_FLWIN_Postion 0;
BA_ "GenSigInvalidValue" SG_ 272 BCM_APM_FRWIN_Postion 7;
BA_ "GenSigSendType" SG_ 272 BCM_APM_FRWIN_Postion 0;
BA_ "GenSigInvalidValue" SG_ 272 BCM_APM_RLWIN_Postion 7;
BA_ "GenSigSendType" SG_ 272 BCM_APM_RLWIN_Postion 0;
BA_ "GenSigInvalidValue" SG_ 272 BCM_APM_RRWIN_Postion 7;
BA_ "GenSigSendType" SG_ 272 BCM_APM_RRWIN_Postion 0;
BA_ "GenSigSendType" SG_ 272 APM_Status 0;
BA_ "GenSigSendType" SG_ 272 ChildProtectionStatus 0;
BA_ "GenSigInvalidValue" SG_ 272 APM_Window_DriveSW_FL_Status 7;
BA_ "GenSigSendType" SG_ 272 APM_Window_DriveSW_FL_Status 0;
BA_ "GenSigInvalidValue" SG_ 272 APM_Window_DriveSW_FR_Status 7;
BA_ "GenSigSendType" SG_ 272 APM_Window_DriveSW_FR_Status 0;
BA_ "GenSigInvalidValue" SG_ 272 APM_Window_DriveSW_RL_Status 7;
BA_ "GenSigSendType" SG_ 272 APM_Window_DriveSW_RL_Status 0;
BA_ "GenSigInvalidValue" SG_ 272 APM_Window_DriveSW_RR_Status 7;
BA_ "GenSigSendType" SG_ 272 APM_Window_DriveSW_RR_Status 0;
BA_ "GenSigInvalidValue" SG_ 272 APM_Window_PassengerSW_Status 7;
BA_ "GenSigSendType" SG_ 272 APM_Window_PassengerSW_Status 0;
BA_ "GenSigInvalidValue" SG_ 272 APM_Window_PassengerSW_RL_Status 7;
BA_ "GenSigSendType" SG_ 272 APM_Window_PassengerSW_RL_Status 0;
BA_ "GenSigInvalidValue" SG_ 272 APM_Window_PassengerSW_RR_Status 7;
BA_ "GenSigSendType" SG_ 272 APM_Window_PassengerSW_RR_Status 0;
BA_ "GenSigSendType" SG_ 525 Checksum_0x20D 0;
BA_ "GenSigInvalidValue" SG_ 525 Rolling_Counter_0x20D 15;
BA_ "GenSigSendType" SG_ 525 Rolling_Counter_0x20D 0;
BA_ "GenSigInvalidValue" SG_ 525 BCM_ODO 1048575;
BA_ "GenSigSendType" SG_ 525 BCM_ODO 0;
BA_ "GenSigSendType" SG_ 834 Checksum_0x342 0;
BA_ "GenSigInvalidValue" SG_ 834 Rolling_Counter_0x342 15;
BA_ "GenSigSendType" SG_ 834 Rolling_Counter_0x342 0;
BA_ "GenSigInvalidValue" SG_ 834 ABS_LRWhlSpdRaw 32767;
BA_ "GenSigSendType" SG_ 834 ABS_LRWhlSpdRaw 0;
BA_ "GenSigSendType" SG_ 834 ABS_LRWhlSpdRawValid 0;
BA_ "GenSigInvalidValue" SG_ 834 ABS_RRWhlSpdRaw 32767;
BA_ "GenSigSendType" SG_ 834 ABS_RRWhlSpdRaw 0;
BA_ "GenSigSendType" SG_ 834 ABS_RRWhlSpdRawValid 0;
BA_ "GenSigInvalidValue" SG_ 834 ABS_VehSpd 32767;
BA_ "GenSigSendType" SG_ 834 ABS_VehSpd 0;
BA_ "GenSigSendType" SG_ 834 ABS_VehSpdValid 0;
BA_ "GenSigSendType" SG_ 306 Checksum_0x132 0;
BA_ "GenSigInvalidValue" SG_ 306 RollingCounter_0x132 15;
BA_ "GenSigSendType" SG_ 306 RollingCounter_0x132 0;
BA_ "GenSigSendType" SG_ 306 ESC_HSA_Control_Status 0;
BA_ "GenSigSendType" SG_ 306 ESC_HSA_Status_Fault 0;
BA_ "GenSigInvalidValue" SG_ 306 ESC_TcsDisableSts 3;
BA_ "GenSigSendType" SG_ 306 ESC_TcsDisableSts 0;
BA_ "GenSigSendType" SG_ 306 ESC_TcsCtrlActv 0;
BA_ "GenSigSendType" SG_ 306 ESC_TcsFlgFlt 0;
BA_ "GenSigSendType" SG_ 306 ESC_EscDisableSts 0;
BA_ "GenSigSendType" SG_ 306 ESC_EscCtrlActv 0;
BA_ "GenSigSendType" SG_ 306 ESC_EscFlgFlt 0;
BA_ "GenSigSendType" SG_ 306 ESC_HBAFlgFlt 0;
BA_ "GenSigSendType" SG_ 306 ESC_HbaCtrlActv 0;
BA_ "GenSigInvalidValue" SG_ 306 ESC_SlopeGradeAngle 255;
BA_ "GenSigSendType" SG_ 306 ESC_SlopeGradeAngle 0;
BA_ "GenSigStartValue" SG_ 306 ESC_MasterCylinderPressure 1000;
BA_ "GenSigInvalidValue" SG_ 306 ESC_MasterCylinderPressure 4095;
BA_ "GenSigSendType" SG_ 306 ESC_MasterCylinderPressure 0;
BA_ "GenSigSendType" SG_ 322 Checksum_0x142 0;
BA_ "GenSigInvalidValue" SG_ 322 RollingCounter_0x142 15;
BA_ "GenSigSendType" SG_ 322 RollingCounter_0x142 0;
BA_ "GenSigSendType" SG_ 322 AbsDiagSessionLampReq_Reserved 0;
BA_ "GenSigSendType" SG_ 322 ABS_AbsCtrlActv 0;
BA_ "GenSigSendType" SG_ 322 ABS_EbdFlgFlt 0;
BA_ "GenSigSendType" SG_ 322 ABS_AbsFlgFlt 0;
BA_ "GenSigSendType" SG_ 322 ABS_ESS_Active 0;
BA_ "GenSigSendType" SG_ 322 ABS_LowBrakeFluid 0;
BA_ "GenSigSendType" SG_ 994 Checksum_0x3E2 0;
BA_ "GenSigInvalidValue" SG_ 994 RollingCounter_0x3E2 15;
BA_ "GenSigSendType" SG_ 994 RollingCounter_0x3E2 0;
BA_ "GenSigStartValue" SG_ 994 ESC_LateralACC 127;
BA_ "GenSigInvalidValue" SG_ 994 ESC_LateralACC 255;
BA_ "GenSigSendType" SG_ 994 ESC_LateralACC 0;
BA_ "GenSigSendType" SG_ 994 ESC_LateralACC_Valid 0;
BA_ "GenSigStartValue" SG_ 994 ESC_LongitudeACC 511;
BA_ "GenSigInvalidValue" SG_ 994 ESC_LongitudeACC 1023;
BA_ "GenSigSendType" SG_ 994 ESC_LongitudeACC 0;
BA_ "GenSigSendType" SG_ 994 ESC_LongitudeACC_Valid 0;
BA_ "GenSigInvalidValue" SG_ 994 ESC_VehDynYawRate 16383;
BA_ "GenSigSendType" SG_ 994 ESC_VehDynYawRate 0;
BA_ "GenSigSendType" SG_ 994 ESC_VehDynYawRate_Valid 0;
BA_ "GenSigInvalidValue" SG_ 1154 ESC_FLTirePressAlarm 1;
BA_ "GenSigSendType" SG_ 1154 ESC_FLTirePressAlarm 0;
BA_ "GenSigInvalidValue" SG_ 1154 ESC_FRTirePressAlarm 1;
BA_ "GenSigSendType" SG_ 1154 ESC_FRTirePressAlarm 0;
BA_ "GenSigInvalidValue" SG_ 1154 ESC_RLTirePressAlarm 1;
BA_ "GenSigSendType" SG_ 1154 ESC_RLTirePressAlarm 0;
BA_ "GenSigInvalidValue" SG_ 1154 ESC_RRTirePressAlarm 1;
BA_ "GenSigSendType" SG_ 1154 ESC_RRTirePressAlarm 0;
BA_ "GenSigInvalidValue" SG_ 1154 ESC_iTPMS_Err 1;
BA_ "GenSigSendType" SG_ 1154 ESC_iTPMS_Err 0;
BA_ "GenSigInvalidValue" SG_ 1154 ESC_iTPMS_WarnLampAct 1;
BA_ "GenSigSendType" SG_ 1154 ESC_iTPMS_WarnLampAct 0;
BA_ "GenSigSendType" SG_ 1154 ESC_iTPMSResetProhibit 0;
BA_ "GenSigSendType" SG_ 1154 ESC_iTPMSResetSts 0;
BA_ "GenSigStartValue" SG_ 496 SAS_SteerWheelAngle 32773;
BA_ "GenSigInvalidValue" SG_ 496 SAS_SteerWheelAngle 65535;
BA_ "GenSigSendType" SG_ 496 SAS_SteerWheelAngle 0;
BA_ "GenSigSendType" SG_ 496 SAS_SteeringAngleValid 0;
BA_ "GenSigSendType" SG_ 496 SAS_SASStsSnsr 0;
BA_ "GenSigInvalidValue" SG_ 496 SAS_SteerWhlRotSpd 16383;
BA_ "GenSigSendType" SG_ 496 SAS_SteerWhlRotSpd 0;
BA_ "GenSigSendType" SG_ 496 SAS_SteerWhlRotSpdStatus 0;
BA_ "GenSigSendType" SG_ 496 SAS_SASFailure 0;
BA_ "GenSigStartValue" SG_ 496 EPS_EpsFailed 1;
BA_ "GenSigInvalidValue" SG_ 496 EPS_EpsFailed 1;
BA_ "GenSigSendType" SG_ 496 EPS_EpsFailed 0;
BA_ "GenSigSendType" SG_ 673 Checksum_0x2A1 0;
BA_ "GenSigInvalidValue" SG_ 673 Rolling_Counter_0x2A1 15;
BA_ "GenSigSendType" SG_ 673 Rolling_Counter_0x2A1 0;
BA_ "GenSigSendType" SG_ 673 ODS_Status 0;
BA_ "GenSigInvalidValue" SG_ 673 EVCC_MHU_CharSchSetFeedBack 3;
BA_ "GenSigSendType" SG_ 673 EVCC_MHU_CharSchSetFeedBack 0;
BA_ "GenSigSendType" SG_ 673 EVCC_ChargeGunSts 0;
BA_ "GenSigSendType" SG_ 673 EVCC_ChargeMode 0;
BA_ "GenSigInvalidValue" SG_ 673 EVCC_CP_Value 255;
BA_ "GenSigSendType" SG_ 673 EVCC_CP_Value 0;
BA_ "GenSigInvalidValue" SG_ 673 EVCC_CP_Sts 15;
BA_ "GenSigSendType" SG_ 673 EVCC_CP_Sts 0;
BA_ "GenSigSendType" SG_ 673 EVCC_PP_Value 0;
BA_ "GenSigSendType" SG_ 673 EVCC_Lock_Sts 0;
BA_ "GenSigSendType" SG_ 673 EVCC_ErrCode 0;
BA_ "GenSigInvalidValue" SG_ 792 EAC_CompElecCurrV 1;
BA_ "GenSigSendType" SG_ 792 EAC_CompElecCurrV 0;
BA_ "GenSigStartValue" SG_ 792 EAC_CompStat 2;
BA_ "GenSigInvalidValue" SG_ 792 EAC_CompStat 15;
BA_ "GenSigSendType" SG_ 792 EAC_CompStat 0;
BA_ "GenSigInvalidValue" SG_ 792 EAC_CompElecPwrV 1;
BA_ "GenSigSendType" SG_ 792 EAC_CompElecPwrV 0;
BA_ "GenSigSendType" SG_ 792 EAC_CompSpdIncrReq 0;
BA_ "GenSigInvalidValue" SG_ 792 EAC_CompSpdV 1;
BA_ "GenSigSendType" SG_ 792 EAC_CompSpdV 0;
BA_ "GenSigInvalidValue" SG_ 792 EAC_CompElecPwr 255;
BA_ "GenSigSendType" SG_ 792 EAC_CompElecPwr 0;
BA_ "GenSigInvalidValue" SG_ 792 EAC_CompSpd 16383;
BA_ "GenSigSendType" SG_ 792 EAC_CompSpd 0;
BA_ "GenSigInvalidValue" SG_ 792 EAC_CompElecCurr 255;
BA_ "GenSigSendType" SG_ 792 EAC_CompElecCurr 0;
BA_ "GenSigInvalidValue" SG_ 792 EAC_CompFltStat 15;
BA_ "GenSigSendType" SG_ 792 EAC_CompFltStat 0;
BA_ "GenSigSendType" SG_ 937 VCU_PTC_RelaySts 0;
BA_ "GenSigSendType" SG_ 937 VCU_EACEnbReq 0;
BA_ "GenSigInvalidValue" SG_ 937 VCU_EACAllowedPower 1023;
BA_ "GenSigSendType" SG_ 937 VCU_EACAllowedPower 0;
BA_ "GenSigInvalidValue" SG_ 937 VCU_EAC_CompSpdReq 16383;
BA_ "GenSigSendType" SG_ 937 VCU_EAC_CompSpdReq 0;
BA_ "GenSigSendType" SG_ 937 VCU_DriveCoolWaterFlowRate 0;
BA_ "GenSigSendType" SG_ 937 VCU_DriveCoolInletWaterTemp 0;
BA_ "GenSigSendType" SG_ 889 VCU_DriveCoolWaterPumpSts 0;
BA_ "GenSigInvalidValue" SG_ 889 VCU_DriveCoolWaterDuty 127;
BA_ "GenSigSendType" SG_ 889 VCU_DriveCoolWaterDuty 0;
BA_ "GenSigSendType" SG_ 889 VCU_BatteryWaterPumpSts_reserved 0;
BA_ "GenSigInvalidValue" SG_ 889 VCU_BatteryWaterPumpDuty_reserve 127;
BA_ "GenSigSendType" SG_ 889 VCU_BatteryWaterPumpDuty_reserve 0;
BA_ "SystemSignalLongSymbol" SG_ 889 VCU_BatteryWaterPumpDuty_reserve "VCU_BatteryWaterPumpDuty_reserved";
BA_ "GenSigStartValue" SG_ 889 VCU_DriveMode 1;
BA_ "GenSigInvalidValue" SG_ 889 VCU_DriveMode 7;
BA_ "GenSigSendType" SG_ 889 VCU_DriveMode 0;
BA_ "GenSigStartValue" SG_ 889 VCU_ActualGear 2;
BA_ "GenSigInvalidValue" SG_ 889 VCU_ActualGear 7;
BA_ "GenSigSendType" SG_ 889 VCU_ActualGear 0;
BA_ "GenSigInvalidValue" SG_ 889 VCU_ACTGearValid 1;
BA_ "GenSigSendType" SG_ 889 VCU_ACTGearValid 0;
BA_ "GenSigSendType" SG_ 889 VCU_AccPedal1OutRange 0;
BA_ "GenSigSendType" SG_ 889 VCU_AccPedal2OutRange 0;
BA_ "GenSigSendType" SG_ 889 VCU_BrkPedal1OutRange 0;
BA_ "GenSigSendType" SG_ 889 VCU_BrkPedal2OutRange 0;
BA_ "GenSigInvalidValue" SG_ 889 VCU_BrkPedalPct 255;
BA_ "GenSigSendType" SG_ 889 VCU_BrkPedalPct 0;
BA_ "GenSigInvalidValue" SG_ 889 VCU_AccPedalPosition 255;
BA_ "GenSigSendType" SG_ 889 VCU_AccPedalPosition 0;
BA_ "GenSigStartValue" SG_ 889 VCU_AccPedalPositionValid 1;
BA_ "GenSigInvalidValue" SG_ 889 VCU_AccPedalPositionValid 1;
BA_ "GenSigSendType" SG_ 889 VCU_AccPedalPositionValid 0;
BA_ "GenSigInvalidValue" SG_ 889 VCU_SocDisplay_EST 127;
BA_ "GenSigSendType" SG_ 889 VCU_SocDisplay_EST 0;
BA_ "GenSigSendType" SG_ 889 VCU_PowerLimit 0;
BA_ "GenSigSendType" SG_ 889 VCU_CruiseCtrlSts 0;
BA_ "GenSigSendType" SG_ 889 VCU_LowSOC_ERR 0;
BA_ "GenSigSendType" SG_ 441 VCU_MCUConsumepower 0;
BA_ "GenSigSendType" SG_ 441 VCU_EACConsumepower 0;
BA_ "GenSigSendType" SG_ 441 VCU_DCDCConsumepower 0;
BA_ "GenSigSendType" SG_ 441 VCU_PTCConsumepower 0;
BA_ "GenSigStartValue" SG_ 425 VCU_RegenLevel_Feed 2;
BA_ "GenSigSendType" SG_ 425 VCU_RegenLevel_Feed 0;
BA_ "GenSigSendType" SG_ 425 VCU_RBCSts 0;
BA_ "GenSigSendType" SG_ 425 VCU_RDCSts 0;
BA_ "GenSigSendType" SG_ 425 VCU_Veh_ERR 0;
BA_ "GenSigSendType" SG_ 425 VCU_DrvSys_ERR 0;
BA_ "GenSigSendType" SG_ 425 VCU_PackSys_ERR 0;
BA_ "GenSigSendType" SG_ 425 VCU_TBOX_Veh_STS_Reserved 0;
BA_ "GenSigSendType" SG_ 425 VCU_VehChg_STS 0;
BA_ "GenSigStartValue" SG_ 425 VCU_BatterVoltage_Reserved 171;
BA_ "GenSigInvalidValue" SG_ 425 VCU_BatterVoltage_Reserved 255;
BA_ "GenSigSendType" SG_ 425 VCU_BatterVoltage_Reserved 0;
BA_ "GenSigSendType" SG_ 425 VCU_BatteryVoltErr_Reserved 0;
BA_ "GenSigSendType" SG_ 425 VCU_MotorCoolingCircuitErr_Reser 0;
BA_ "SystemSignalLongSymbol" SG_ 425 VCU_MotorCoolingCircuitErr_Reser "VCU_MotorCoolingCircuitErr_Reserved";
BA_ "GenSigSendType" SG_ 425 VCU_PackCoolingCircuitErr_Reserv 0;
BA_ "SystemSignalLongSymbol" SG_ 425 VCU_PackCoolingCircuitErr_Reserv "VCU_PackCoolingCircuitErr_Reserved";
BA_ "GenSigInvalidValue" SG_ 425 VCU_VehicleHVStatus 3;
BA_ "GenSigSendType" SG_ 425 VCU_VehicleHVStatus 0;
BA_ "GenSigInvalidValue" SG_ 425 VCU_InstantPowerConsump 1023;
BA_ "GenSigSendType" SG_ 425 VCU_InstantPowerConsump 0;
BA_ "GenSigInvalidValue" SG_ 425 VCU_AveragePowerConsump 1023;
BA_ "GenSigSendType" SG_ 425 VCU_AveragePowerConsump 0;
BA_ "GenSigSendType" SG_ 425 VCU_BrakePedalSts 0;
BA_ "GenSigStartValue" SG_ 1008 VCU_HVACInletWateTemp 40;
BA_ "GenSigInvalidValue" SG_ 1008 VCU_HVACInletWateTemp 255;
BA_ "GenSigSendType" SG_ 1008 VCU_HVACInletWateTemp 0;
BA_ "GenSigInvalidValue" SG_ 1008 VCU_IMMO_Sts 2;
BA_ "GenSigSendType" SG_ 1008 VCU_IMMO_Sts 0;
BA_ "GenSigInvalidValue" SG_ 1008 VCU_DCDCAllowedPower 511;
BA_ "GenSigSendType" SG_ 1008 VCU_DCDCAllowedPower 0;
BA_ "GenSigSendType" SG_ 1008 VCU_Shift_ERR 0;
BA_ "GenSigInvalidValue" SG_ 1008 VCU_VehicleDischargePower 127;
BA_ "GenSigSendType" SG_ 1008 VCU_VehicleDischargePower 0;
BA_ "GenSigInvalidValue" SG_ 1008 VCU_VehicleChargePower 127;
BA_ "GenSigSendType" SG_ 1008 VCU_VehicleChargePower 0;
BA_ "GenSigSendType" SG_ 992 Checksum_0x3E0 0;
BA_ "GenSigInvalidValue" SG_ 992 Rolling_Counter_0x3E0 15;
BA_ "GenSigSendType" SG_ 992 Rolling_Counter_0x3E0 0;
BA_ "GenSigSendType" SG_ 992 VCU_RunningRange 0;
BA_ "GenSigSendType" SG_ 992 VCU_MHU_Ack_ChgSche_stt 0;
BA_ "GenSigSendType" SG_ 992 VCU_MHU_GuestMode_sts 0;
BA_ "GenSigStartValue" SG_ 992 VCU_MHU_Ack_TargetSOC 100;
BA_ "GenSigSendType" SG_ 992 VCU_MHU_Ack_TargetSOC 0;
BA_ "GenSigSendType" SG_ 992 VCU_ValetMode_sts 0;
BA_ "GenSigInactiveValue" SG_ 992 VCU_ValetMode_MaxSpeedSts 255;
BA_ "GenSigInvalidValue" SG_ 992 VCU_ValetMode_MaxSpeedSts 2;
BA_ "GenSigSendType" SG_ 992 VCU_ValetMode_MaxSpeedSts 0;
BA_ "GenSigSendType" SG_ 992 VCU_CreepDisable_stt 0;
BA_ "GenSigSendType" SG_ 745 Checksum_0x2E9 0;
BA_ "GenSigInvalidValue" SG_ 745 Rolling_Counter_0x2E9 15;
BA_ "GenSigSendType" SG_ 745 Rolling_Counter_0x2E9 0;
BA_ "GenSigInvalidValue" SG_ 745 VCU_RemainingMileage 4294967295;
BA_ "GenSigSendType" SG_ 745 VCU_RemainingMileage 0;
BA_ "GenSigInvalidValue" SG_ 745 VCU_SetCruiseSpd 255;
BA_ "GenSigSendType" SG_ 745 VCU_SetCruiseSpd 0;
BA_ "GenSigSendType" SG_ 534 Checksum_0x216 0;
BA_ "GenSigInvalidValue" SG_ 534 Rolling_Counter_0x216 15;
BA_ "GenSigSendType" SG_ 534 Rolling_Counter_0x216 0;
BA_ "GenSigInvalidValue" SG_ 534 BMS_RemainChargeTime 16383;
BA_ "GenSigSendType" SG_ 534 BMS_RemainChargeTime 0;
BA_ "GenSigInvalidValue" SG_ 534 BMS_ChgVoltage_REQ 16383;
BA_ "GenSigSendType" SG_ 534 BMS_ChgVoltage_REQ 0;
BA_ "GenSigInvalidValue" SG_ 534 BMS_ChgCurrent_REQ 65535;
BA_ "GenSigSendType" SG_ 534 BMS_ChgCurrent_REQ 0;
BA_ "GenSigSendType" SG_ 533 Checksum_0x215 0;
BA_ "GenSigInvalidValue" SG_ 533 Rolling_Counter_0x215 15;
BA_ "GenSigSendType" SG_ 533 Rolling_Counter_0x215 0;
BA_ "GenSigStartValue" SG_ 533 BMS_SOE 54;
BA_ "GenSigInvalidValue" SG_ 533 BMS_SOE 255;
BA_ "GenSigSendType" SG_ 533 BMS_SOE 0;
BA_ "GenSigSendType" SG_ 533 BMS_HWCrash_Sts 0;
BA_ "GenSigSendType" SG_ 533 BMS_HVIL_STS 0;
BA_ "GenSigSendType" SG_ 533 BMS_IGN_Sts 0;
BA_ "GenSigInvalidValue" SG_ 533 BMS_Sys_STS 8;
BA_ "GenSigSendType" SG_ 533 BMS_Sys_STS 0;
BA_ "GenSigSendType" SG_ 533 BMS_HVOnOff_STS 0;
BA_ "GenSigSendType" SG_ 533 BMS_Balance_STS 0;
BA_ "GenSigInvalidValue" SG_ 533 BMS_SocActual_EST 1023;
BA_ "GenSigSendType" SG_ 533 BMS_SocActual_EST 0;
BA_ "GenSigSendType" SG_ 533 BMS_BatBalance_ERR 0;
BA_ "GenSigSendType" SG_ 533 BMS_ISU_Status 0;
BA_ "GenSigInvalidValue" SG_ 533 BMS_ERR_LEV 15;
BA_ "GenSigSendType" SG_ 533 BMS_ERR_LEV 0;
BA_ "GenSigStartValue" SG_ 533 BMS_SOH 54;
BA_ "GenSigInvalidValue" SG_ 533 BMS_SOH 255;
BA_ "GenSigSendType" SG_ 533 BMS_SOH 0;
BA_ "GenSigSendType" SG_ 533 BMS_HV_Sts 0;
BA_ "GenSigSendType" SG_ 1171 BMS_DischargeCurrent_Limited 0;
BA_ "GenSigSendType" SG_ 1171 BMS_Warning_Flag_Reserved_07 0;
BA_ "GenSigSendType" SG_ 1171 BMS_Warning_Flag_Reserved_11 0;
BA_ "GenSigSendType" SG_ 1171 BMS_Warning_Flag_Reserved_10 0;
BA_ "GenSigSendType" SG_ 1171 BMS_Warning_Flag_Reserved_09 0;
BA_ "GenSigSendType" SG_ 1171 BMS_Warning_Flag_Reserved_13 0;
BA_ "GenSigSendType" SG_ 1171 BMS_Warning_Flag_Reserved_12 0;
BA_ "GenSigSendType" SG_ 1171 BMS_Warning_Flag_Reserved_06 0;
BA_ "GenSigSendType" SG_ 1171 BMS_Warning_Flag_Reserved_05 0;
BA_ "GenSigSendType" SG_ 1171 BMS_Warning_Flag_Reserved_04 0;
BA_ "GenSigSendType" SG_ 1171 BMS_MalfunctionSts 0;
BA_ "GenSigInvalidValue" SG_ 1171 BMS_LowBattery 3;
BA_ "GenSigSendType" SG_ 1171 BMS_LowBattery 0;
BA_ "GenSigSendType" SG_ 1171 BMS_BatteryReplacement 0;
BA_ "GenSigSendType" SG_ 1171 BMS_PackTempSts 0;
BA_ "GenSigSendType" SG_ 1171 BMS_ThermalRunaway 0;
BA_ "GenSigInvalidValue" SG_ 1171 Rolling_Counter_0x493 15;
BA_ "GenSigSendType" SG_ 1171 Rolling_Counter_0x493 0;
BA_ "GenSigSendType" SG_ 1171 Checksum_0x493 0;
BA_ "GenSigSendType" SG_ 372 Checksum_0x174 0;
BA_ "GenSigInvalidValue" SG_ 372 Rolling_Counter_0x174 15;
BA_ "GenSigSendType" SG_ 372 Rolling_Counter_0x174 0;
BA_ "GenSigStartValue" SG_ 372 BMS_PackCur_MEAS 32768;
BA_ "GenSigInvalidValue" SG_ 372 BMS_PackCur_MEAS 65535;
BA_ "GenSigSendType" SG_ 372 BMS_PackCur_MEAS 0;
BA_ "GenSigSendType" SG_ 374 Checksum_0x176 0;
BA_ "GenSigInvalidValue" SG_ 374 Rolling_Counter_0x176 15;
BA_ "GenSigSendType" SG_ 374 Rolling_Counter_0x176 0;
BA_ "GenSigInvalidValue" SG_ 374 BMS_HVLinkVol_MEAS 65535;
BA_ "GenSigSendType" SG_ 374 BMS_HVLinkVol_MEAS 0;
BA_ "GenSigInvalidValue" SG_ 374 BMS_HVPackVol_MEAS 65535;
BA_ "GenSigSendType" SG_ 374 BMS_HVPackVol_MEAS 0;
BA_ "GenSigSendType" SG_ 523 Checksum_0x20B 0;
BA_ "GenSigInvalidValue" SG_ 523 Rolling_Counter_0x20B 15;
BA_ "GenSigSendType" SG_ 523 Rolling_Counter_0x20B 0;
BA_ "GenSigInvalidValue" SG_ 523 DCDC_Sys_STS 5;
BA_ "GenSigSendType" SG_ 523 DCDC_Sys_STS 0;
BA_ "GenSigInvalidValue" SG_ 523 DCDC_Voltage_Input 1023;
BA_ "GenSigSendType" SG_ 523 DCDC_Voltage_Input 0;
BA_ "GenSigInvalidValue" SG_ 523 DCDC_Current_Input 255;
BA_ "GenSigSendType" SG_ 523 DCDC_Current_Input 0;
BA_ "GenSigInvalidValue" SG_ 523 DCDC_Voltage_Output 1023;
BA_ "GenSigSendType" SG_ 523 DCDC_Voltage_Output 0;
BA_ "GenSigInvalidValue" SG_ 523 DCDC_Current_Output 255;
BA_ "GenSigSendType" SG_ 523 DCDC_Current_Output 0;
BA_ "GenSigSendType" SG_ 523 DCDC_Output_STS 0;
BA_ "GenSigStartValue" SG_ 523 DCDC_Temp 40;
BA_ "GenSigInvalidValue" SG_ 523 DCDC_Temp 255;
BA_ "GenSigSendType" SG_ 523 DCDC_Temp 0;
BA_ "GenSigSendType" SG_ 504 Checksum_0x1F8 0;
BA_ "GenSigInvalidValue" SG_ 504 Rolling_Counter_0x1F8 15;
BA_ "GenSigSendType" SG_ 504 Rolling_Counter_0x1F8 0;
BA_ "GenSigStartValue" SG_ 504 EDS_output_trq_FR 2000;
BA_ "GenSigInvalidValue" SG_ 504 EDS_output_trq_FR 65535;
BA_ "GenSigSendType" SG_ 504 EDS_output_trq_FR 0;
BA_ "GenSigSendType" SG_ 504 EDS_output_trqValid_FR 0;
BA_ "GenSigStartValue" SG_ 504 EDS_Spd_FR 20000;
BA_ "GenSigInvalidValue" SG_ 504 EDS_Spd_FR 65535;
BA_ "GenSigSendType" SG_ 504 EDS_Spd_FR 0;
BA_ "GenSigSendType" SG_ 504 EDS_SpdValid_FR 0;
BA_ "GenSigInvalidValue" SG_ 504 EDS_MotorDriveSts_FR 3;
BA_ "GenSigSendType" SG_ 504 EDS_MotorDriveSts_FR 0;
BA_ "GenSigInvalidValue" SG_ 504 EDS_Work_STS_FR 15;
BA_ "GenSigSendType" SG_ 504 EDS_Work_STS_FR 0;
BA_ "GenSigSendType" SG_ 504 EDS_powoff_req_FR 0;
BA_ "GenSigSendType" SG_ 1015 MFS_OK_Control 4;
BA_ "GenSigSendType" SG_ 1015 MFS_SourseControl 4;
BA_ "GenSigSendType" SG_ 1015 MFS_VoiceRecognitionOn_Off 4;
BA_ "GenSigSendType" SG_ 1015 MFS_TelephoneCall_EndCall 4;
BA_ "GenSigSendType" SG_ 1015 MFS_DownControl 4;
BA_ "GenSigSendType" SG_ 1015 MFS_UpControl 4;
BA_ "GenSigSendType" SG_ 1015 MFS_RightControl 4;
BA_ "GenSigSendType" SG_ 1015 MFS_LeftControl 4;
BA_ "GenSigSendType" SG_ 1015 MFS_CruiseOn_Off 4;
BA_ "GenSigSendType" SG_ 1015 MFS_Failure 4;
BA_ "GenSigSendType" SG_ 1015 MFS_ISAControl 4;
BA_ "GenSigSendType" SG_ 1015 MFS_LKAControl 4;
BA_ "GenSigSendType" SG_ 1015 MFS_CruiseGapDecrease 4;
BA_ "GenSigSendType" SG_ 1015 MFS_CruiseSpeedDecrease 4;
BA_ "GenSigSendType" SG_ 1015 MFS_CruiseSpeedIncrease 4;
BA_ "GenSigSendType" SG_ 1015 MFS_CruiseCancel 4;
BA_ "GenSigSendType" SG_ 1015 MFS_CruiseGapIncrease 4;
BA_ "GenSigInvalidValue" SG_ 1017 MFS_Mode_Control 3;
BA_ "GenSigSendType" SG_ 1017 MFS_Mode_Control 4;
BA_ "GenSigInvalidValue" SG_ 1017 MFS_MUTE_SPEAKER 3;
BA_ "GenSigSendType" SG_ 1017 MFS_MUTE_SPEAKER 4;
BA_ "GenSigInvalidValue" SG_ 1017 MFS_SONG_U 3;
BA_ "GenSigSendType" SG_ 1017 MFS_SONG_U 4;
BA_ "GenSigInvalidValue" SG_ 1017 MFS_SONG_D 3;
BA_ "GenSigSendType" SG_ 1017 MFS_SONG_D 4;
BA_ "GenSigInvalidValue" SG_ 1017 MFS_VOL_U 3;
BA_ "GenSigSendType" SG_ 1017 MFS_VOL_U 4;
BA_ "GenSigInvalidValue" SG_ 1017 MFS_VOL_D 3;
BA_ "GenSigSendType" SG_ 1017 MFS_VOL_D 4;
BA_ "GenSigSendType" SG_ 1284 MHU_sourceID 0;
BA_ "GenSigSendType" SG_ 1284 MHU_CBV 0;
BA_ "GenSigSendType" SG_ 1284 MHU_Data0 0;
BA_ "GenSigSendType" SG_ 1284 MHU_Data1 0;
BA_ "GenSigSendType" SG_ 1284 MHU_Data2 0;
BA_ "GenSigSendType" SG_ 1284 MHU_Data3 0;
BA_ "GenSigSendType" SG_ 1284 MHU_Data4 0;
BA_ "GenSigSendType" SG_ 1284 MHU_Data5 0;
BA_ "GenSigSendType" SG_ 1283 IPC_sourceID 0;
BA_ "GenSigSendType" SG_ 1283 IPC_CBV 0;
BA_ "GenSigSendType" SG_ 1283 IPC_Data0 0;
BA_ "GenSigSendType" SG_ 1283 IPC_Data1 0;
BA_ "GenSigSendType" SG_ 1283 IPC_Data2 0;
BA_ "GenSigSendType" SG_ 1283 IPC_Data3 0;
BA_ "GenSigSendType" SG_ 1283 IPC_Data4 0;
BA_ "GenSigSendType" SG_ 1283 IPC_Data5 0;
BA_ "GenSigSendType" SG_ 1282 GW_sourceID 0;
BA_ "GenSigSendType" SG_ 1282 GW_CBV 0;
BA_ "GenSigSendType" SG_ 1282 GW_Data0 0;
BA_ "GenSigSendType" SG_ 1282 GW_Data1 0;
BA_ "GenSigSendType" SG_ 1282 GW_Data2 0;
BA_ "GenSigSendType" SG_ 1282 GW_Data3 0;
BA_ "GenSigSendType" SG_ 1282 GW_Data4 0;
BA_ "GenSigSendType" SG_ 1282 GW_Data5 0;
BA_ "GenSigSendType" SG_ 1289 CCU_sourceID 0;
BA_ "GenSigSendType" SG_ 1289 CCU_CBV 0;
BA_ "GenSigSendType" SG_ 1289 CCU_Data0 0;
BA_ "GenSigSendType" SG_ 1289 CCU_Data1 0;
BA_ "GenSigSendType" SG_ 1289 CCU_Data2 0;
BA_ "GenSigSendType" SG_ 1289 CCU_Data3 0;
BA_ "GenSigSendType" SG_ 1289 CCU_Data4 0;
BA_ "GenSigSendType" SG_ 1289 CCU_Data5 0;
BA_ "GenSigSendType" SG_ 1668 MHU_DiagReqData0 0;
BA_ "GenSigSendType" SG_ 1668 MHU_DiagReqData1 0;
BA_ "GenSigSendType" SG_ 1668 MHU_DiagReqData2 0;
BA_ "GenSigSendType" SG_ 1668 MHU_DiagReqData3 0;
BA_ "GenSigSendType" SG_ 1668 MHU_DiagReqData4 0;
BA_ "GenSigSendType" SG_ 1668 MHU_DiagReqData5 0;
BA_ "GenSigSendType" SG_ 1668 MHU_DiagReqData6 0;
BA_ "GenSigSendType" SG_ 1668 MHU_DiagReqData7 0;
BA_ "GenSigSendType" SG_ 1540 MHU_DiagRespData0 0;
BA_ "GenSigSendType" SG_ 1540 MHU_DiagRespData1 0;
BA_ "GenSigSendType" SG_ 1540 MHU_DiagRespData2 0;
BA_ "GenSigSendType" SG_ 1540 MHU_DiagRespData3 0;
BA_ "GenSigSendType" SG_ 1540 MHU_DiagRespData4 0;
BA_ "GenSigSendType" SG_ 1540 MHU_DiagRespData5 0;
BA_ "GenSigSendType" SG_ 1540 MHU_DiagRespData6 0;
BA_ "GenSigSendType" SG_ 1540 MHU_DiagRespData7 0;
BA_ "GenSigSendType" SG_ 1667 IPC_DiagReqData0 0;
BA_ "GenSigSendType" SG_ 1667 IPC_DiagReqData1 0;
BA_ "GenSigSendType" SG_ 1667 IPC_DiagReqData2 0;
BA_ "GenSigSendType" SG_ 1667 IPC_DiagReqData3 0;
BA_ "GenSigSendType" SG_ 1667 IPC_DiagReqData4 0;
BA_ "GenSigSendType" SG_ 1667 IPC_DiagReqData5 0;
BA_ "GenSigSendType" SG_ 1667 IPC_DiagReqData6 0;
BA_ "GenSigSendType" SG_ 1667 IPC_DiagReqData7 0;
BA_ "GenSigSendType" SG_ 1539 IPC_DiagRespData0 0;
BA_ "GenSigSendType" SG_ 1539 IPC_DiagRespData1 0;
BA_ "GenSigSendType" SG_ 1539 IPC_DiagRespData2 0;
BA_ "GenSigSendType" SG_ 1539 IPC_DiagRespData3 0;
BA_ "GenSigSendType" SG_ 1539 IPC_DiagRespData4 0;
BA_ "GenSigSendType" SG_ 1539 IPC_DiagRespData5 0;
BA_ "GenSigSendType" SG_ 1539 IPC_DiagRespData6 0;
BA_ "GenSigSendType" SG_ 1539 IPC_DiagRespData7 0;
BA_ "GenSigSendType" SG_ 1673 CCU_DiagReqData0 0;
BA_ "GenSigSendType" SG_ 1673 CCU_DiagReqData1 0;
BA_ "GenSigSendType" SG_ 1673 CCU_DiagReqData2 0;
BA_ "GenSigSendType" SG_ 1673 CCU_DiagReqData3 0;
BA_ "GenSigSendType" SG_ 1673 CCU_DiagReqData4 0;
BA_ "GenSigSendType" SG_ 1673 CCU_DiagReqData5 0;
BA_ "GenSigSendType" SG_ 1673 CCU_DiagReqData6 0;
BA_ "GenSigSendType" SG_ 1673 CCU_DiagReqData7 0;
BA_ "GenSigSendType" SG_ 1545 CCU_DiagRespData0 0;
BA_ "GenSigSendType" SG_ 1545 CCU_DiagRespData1 0;
BA_ "GenSigSendType" SG_ 1545 CCU_DiagRespData2 0;
BA_ "GenSigSendType" SG_ 1545 CCU_DiagRespData3 0;
BA_ "GenSigSendType" SG_ 1545 CCU_DiagRespData4 0;
BA_ "GenSigSendType" SG_ 1545 CCU_DiagRespData5 0;
BA_ "GenSigSendType" SG_ 1545 CCU_DiagRespData6 0;
BA_ "GenSigSendType" SG_ 1545 CCU_DiagRespData7 0;
BA_ "GenSigSendType" SG_ 1791 GW_DiagFunctionalAddressingData0 0;
BA_ "GenSigSendType" SG_ 1791 GW_DiagFunctionalAddressingData1 0;
BA_ "GenSigSendType" SG_ 1791 GW_DiagFunctionalAddressingData2 0;
BA_ "GenSigSendType" SG_ 1791 GW_DiagFunctionalAddressingData3 0;
BA_ "GenSigSendType" SG_ 1791 GW_DiagFunctionalAddressingData4 0;
BA_ "GenSigSendType" SG_ 1791 GW_DiagFunctionalAddressingData5 0;
BA_ "GenSigSendType" SG_ 1791 GW_DiagFunctionalAddressingData6 0;
BA_ "GenSigSendType" SG_ 1791 GW_DiagFunctionalAddressingData7 0;
BA_ "GenSigSendType" SG_ 1691 EDS_DiagReqData0 1;
BA_ "GenSigSendType" SG_ 1691 EDS_DiagReqData1 1;
BA_ "GenSigSendType" SG_ 1691 EDS_DiagReqData2 1;
BA_ "GenSigSendType" SG_ 1691 EDS_DiagReqData3 1;
BA_ "GenSigSendType" SG_ 1691 EDS_DiagReqData4 1;
BA_ "GenSigSendType" SG_ 1691 EDS_DiagReqData5 1;
BA_ "GenSigSendType" SG_ 1691 EDS_DiagReqData6 1;
BA_ "GenSigSendType" SG_ 1691 EDS_DiagReqData7 1;
BA_ "GenSigSendType" SG_ 1563 EDS_DiagRespData0 1;
BA_ "GenSigSendType" SG_ 1563 EDS_DiagRespData1 1;
BA_ "GenSigSendType" SG_ 1563 EDS_DiagRespData2 1;
BA_ "GenSigSendType" SG_ 1563 EDS_DiagRespData3 1;
BA_ "GenSigSendType" SG_ 1563 EDS_DiagRespData4 1;
BA_ "GenSigSendType" SG_ 1563 EDS_DiagRespData5 1;
BA_ "GenSigSendType" SG_ 1563 EDS_DiagRespData6 1;
BA_ "GenSigSendType" SG_ 1563 EDS_DiagRespData7 1;
BA_ "GenSigSendType" SG_ 1708 VCU_DiagReqData0 1;
BA_ "GenSigSendType" SG_ 1708 VCU_DiagReqData1 1;
BA_ "GenSigSendType" SG_ 1708 VCU_DiagReqData2 1;
BA_ "GenSigSendType" SG_ 1708 VCU_DiagReqData3 1;
BA_ "GenSigSendType" SG_ 1708 VCU_DiagReqData4 1;
BA_ "GenSigSendType" SG_ 1708 VCU_DiagReqData5 1;
BA_ "GenSigSendType" SG_ 1708 VCU_DiagReqData6 1;
BA_ "GenSigSendType" SG_ 1708 VCU_DiagReqData7 1;
BA_ "GenSigSendType" SG_ 1580 VCU_DiagRespData0 1;
BA_ "GenSigSendType" SG_ 1580 VCU_DiagRespData1 1;
BA_ "GenSigSendType" SG_ 1580 VCU_DiagRespData2 1;
BA_ "GenSigSendType" SG_ 1580 VCU_DiagRespData3 1;
BA_ "GenSigSendType" SG_ 1580 VCU_DiagRespData4 1;
BA_ "GenSigSendType" SG_ 1580 VCU_DiagRespData5 1;
BA_ "GenSigSendType" SG_ 1580 VCU_DiagRespData6 1;
BA_ "GenSigSendType" SG_ 1580 VCU_DiagRespData7 1;
BA_ "GenSigSendType" SG_ 1725 PDU_DiagReqData0 1;
BA_ "GenSigSendType" SG_ 1725 PDU_DiagReqData1 1;
BA_ "GenSigSendType" SG_ 1725 PDU_DiagReqData2 1;
BA_ "GenSigSendType" SG_ 1725 PDU_DiagReqData3 1;
BA_ "GenSigSendType" SG_ 1725 PDU_DiagReqData4 1;
BA_ "GenSigSendType" SG_ 1725 PDU_DiagReqData5 1;
BA_ "GenSigSendType" SG_ 1725 PDU_DiagReqData6 1;
BA_ "GenSigSendType" SG_ 1725 PDU_DiagReqData7 1;
BA_ "GenSigSendType" SG_ 1597 PDU_DiagRespData0 1;
BA_ "GenSigSendType" SG_ 1597 PDU_DiagRespData1 1;
BA_ "GenSigSendType" SG_ 1597 PDU_DiagRespData2 1;
BA_ "GenSigSendType" SG_ 1597 PDU_DiagRespData3 1;
BA_ "GenSigSendType" SG_ 1597 PDU_DiagRespData4 1;
BA_ "GenSigSendType" SG_ 1597 PDU_DiagRespData5 1;
BA_ "GenSigSendType" SG_ 1597 PDU_DiagRespData6 1;
BA_ "GenSigSendType" SG_ 1597 PDU_DiagRespData7 1;
BA_ "GenSigSendType" SG_ 1683 BMS_DiagReqData0 1;
BA_ "GenSigSendType" SG_ 1683 BMS_DiagReqData1 1;
BA_ "GenSigSendType" SG_ 1683 BMS_DiagReqData2 1;
BA_ "GenSigSendType" SG_ 1683 BMS_DiagReqData3 1;
BA_ "GenSigSendType" SG_ 1683 BMS_DiagReqData4 1;
BA_ "GenSigSendType" SG_ 1683 BMS_DiagReqData5 1;
BA_ "GenSigSendType" SG_ 1683 BMS_DiagReqData6 1;
BA_ "GenSigSendType" SG_ 1683 BMS_DiagReqData7 1;
BA_ "GenSigSendType" SG_ 1555 BMS_DiagRespData0 1;
BA_ "GenSigSendType" SG_ 1555 BMS_DiagRespData1 1;
BA_ "GenSigSendType" SG_ 1555 BMS_DiagRespData2 1;
BA_ "GenSigSendType" SG_ 1555 BMS_DiagRespData3 1;
BA_ "GenSigSendType" SG_ 1555 BMS_DiagRespData4 1;
BA_ "GenSigSendType" SG_ 1555 BMS_DiagRespData5 1;
BA_ "GenSigSendType" SG_ 1555 BMS_DiagRespData6 1;
BA_ "GenSigSendType" SG_ 1555 BMS_DiagRespData7 1;
BA_ "GenSigSendType" SG_ 1781 EAC_DiagReqData0 1;
BA_ "GenSigSendType" SG_ 1781 EAC_DiagReqData1 1;
BA_ "GenSigSendType" SG_ 1781 EAC_DiagReqData2 1;
BA_ "GenSigSendType" SG_ 1781 EAC_DiagReqData3 1;
BA_ "GenSigSendType" SG_ 1781 EAC_DiagReqData4 1;
BA_ "GenSigSendType" SG_ 1781 EAC_DiagReqData5 1;
BA_ "GenSigSendType" SG_ 1781 EAC_DiagReqData6 1;
BA_ "GenSigSendType" SG_ 1781 EAC_DiagReqData7 1;
BA_ "GenSigSendType" SG_ 1653 EAC_DiagRespData0 1;
BA_ "GenSigSendType" SG_ 1653 EAC_DiagRespData1 1;
BA_ "GenSigSendType" SG_ 1653 EAC_DiagRespData2 1;
BA_ "GenSigSendType" SG_ 1653 EAC_DiagRespData3 1;
BA_ "GenSigSendType" SG_ 1653 EAC_DiagRespData4 1;
BA_ "GenSigSendType" SG_ 1653 EAC_DiagRespData5 1;
BA_ "GenSigSendType" SG_ 1653 EAC_DiagRespData6 1;
BA_ "GenSigSendType" SG_ 1653 EAC_DiagRespData7 1;
BA_ "GenSigSendType" SG_ 1695 EVCC_DiagReqData0 1;
BA_ "GenSigSendType" SG_ 1695 EVCC_DiagReqData1 1;
BA_ "GenSigSendType" SG_ 1695 EVCC_DiagReqData2 1;
BA_ "GenSigSendType" SG_ 1695 EVCC_DiagReqData3 1;
BA_ "GenSigSendType" SG_ 1695 EVCC_DiagReqData4 1;
BA_ "GenSigSendType" SG_ 1695 EVCC_DiagReqData5 1;
BA_ "GenSigSendType" SG_ 1695 EVCC_DiagReqData6 1;
BA_ "GenSigSendType" SG_ 1695 EVCC_DiagReqData7 1;
BA_ "GenSigSendType" SG_ 1567 EVCC_DiagRespData0 1;
BA_ "GenSigSendType" SG_ 1567 EVCC_DiagRespData1 1;
BA_ "GenSigSendType" SG_ 1567 EVCC_DiagRespData2 1;
BA_ "GenSigSendType" SG_ 1567 EVCC_DiagRespData3 1;
BA_ "GenSigSendType" SG_ 1567 EVCC_DiagRespData4 1;
BA_ "GenSigSendType" SG_ 1567 EVCC_DiagRespData5 1;
BA_ "GenSigSendType" SG_ 1567 EVCC_DiagRespData6 1;
BA_ "GenSigSendType" SG_ 1567 EVCC_DiagRespData7 1;
BA_ "GenSigSendType" SG_ 1705 ESC_DiagReqData0 1;
BA_ "GenSigSendType" SG_ 1705 ESC_DiagReqData1 1;
BA_ "GenSigSendType" SG_ 1705 ESC_DiagReqData2 1;
BA_ "GenSigSendType" SG_ 1705 ESC_DiagReqData3 1;
BA_ "GenSigSendType" SG_ 1705 ESC_DiagReqData4 1;
BA_ "GenSigSendType" SG_ 1705 ESC_DiagReqData5 1;
BA_ "GenSigSendType" SG_ 1705 ESC_DiagReqData6 1;
BA_ "GenSigSendType" SG_ 1705 ESC_DiagReqData7 1;
BA_ "GenSigSendType" SG_ 1577 ESC_DiagRespData0 1;
BA_ "GenSigSendType" SG_ 1577 ESC_DiagRespData1 1;
BA_ "GenSigSendType" SG_ 1577 ESC_DiagRespData2 1;
BA_ "GenSigSendType" SG_ 1577 ESC_DiagRespData3 1;
BA_ "GenSigSendType" SG_ 1577 ESC_DiagRespData4 1;
BA_ "GenSigSendType" SG_ 1577 ESC_DiagRespData5 1;
BA_ "GenSigSendType" SG_ 1577 ESC_DiagRespData6 1;
BA_ "GenSigSendType" SG_ 1577 ESC_DiagRespData7 1;
BA_ "GenSigSendType" SG_ 1704 EPS_DiagReqData0 1;
BA_ "GenSigSendType" SG_ 1704 EPS_DiagReqData1 1;
BA_ "GenSigSendType" SG_ 1704 EPS_DiagReqData2 1;
BA_ "GenSigSendType" SG_ 1704 EPS_DiagReqData3 1;
BA_ "GenSigSendType" SG_ 1704 EPS_DiagReqData4 1;
BA_ "GenSigSendType" SG_ 1704 EPS_DiagReqData5 1;
BA_ "GenSigSendType" SG_ 1704 EPS_DiagReqData6 1;
BA_ "GenSigSendType" SG_ 1704 EPS_DiagReqData7 1;
BA_ "GenSigSendType" SG_ 1576 EPS_DiagRespData0 1;
BA_ "GenSigSendType" SG_ 1576 EPS_DiagRespData1 1;
BA_ "GenSigSendType" SG_ 1576 EPS_DiagRespData2 1;
BA_ "GenSigSendType" SG_ 1576 EPS_DiagRespData3 1;
BA_ "GenSigSendType" SG_ 1576 EPS_DiagRespData4 1;
BA_ "GenSigSendType" SG_ 1576 EPS_DiagRespData5 1;
BA_ "GenSigSendType" SG_ 1576 EPS_DiagRespData6 1;
BA_ "GenSigSendType" SG_ 1576 EPS_DiagRespData7 1;
BA_ "GenSigSendType" SG_ 1680 EKS_DiagReqData0 1;
BA_ "GenSigSendType" SG_ 1680 EKS_DiagReqData1 1;
BA_ "GenSigSendType" SG_ 1680 EKS_DiagReqData2 1;
BA_ "GenSigSendType" SG_ 1680 EKS_DiagReqData3 1;
BA_ "GenSigSendType" SG_ 1680 EKS_DiagReqData4 1;
BA_ "GenSigSendType" SG_ 1680 EKS_DiagReqData5 1;
BA_ "GenSigSendType" SG_ 1680 EKS_DiagReqData6 1;
BA_ "GenSigSendType" SG_ 1680 EKS_DiagReqData7 1;
BA_ "GenSigSendType" SG_ 1552 EKS_DiagRespData0 1;
BA_ "GenSigSendType" SG_ 1552 EKS_DiagRespData1 1;
BA_ "GenSigSendType" SG_ 1552 EKS_DiagRespData2 1;
BA_ "GenSigSendType" SG_ 1552 EKS_DiagRespData3 1;
BA_ "GenSigSendType" SG_ 1552 EKS_DiagRespData4 1;
BA_ "GenSigSendType" SG_ 1552 EKS_DiagRespData5 1;
BA_ "GenSigSendType" SG_ 1552 EKS_DiagRespData6 1;
BA_ "GenSigSendType" SG_ 1552 EKS_DiagRespData7 1;
BA_ "GenSigSendType" SG_ 2018 IPC_DiagReqData0 1;
BA_ "GenSigSendType" SG_ 2018 IPC_DiagReqData1 1;
BA_ "GenSigSendType" SG_ 2018 IPC_DiagReqData2 1;
BA_ "GenSigSendType" SG_ 2018 IPC_DiagReqData3 1;
BA_ "GenSigSendType" SG_ 2018 IPC_DiagReqData4 1;
BA_ "GenSigSendType" SG_ 2018 IPC_DiagReqData5 1;
BA_ "GenSigSendType" SG_ 2018 IPC_DiagReqData6 1;
BA_ "GenSigSendType" SG_ 2018 IPC_DiagReqData7 1;
BA_ "GenSigSendType" SG_ 2026 IPC_DiagRespData0 1;
BA_ "GenSigSendType" SG_ 2026 IPC_DiagRespData1 1;
BA_ "GenSigSendType" SG_ 2026 IPC_DiagRespData2 1;
BA_ "GenSigSendType" SG_ 2026 IPC_DiagRespData3 1;
BA_ "GenSigSendType" SG_ 2026 IPC_DiagRespData4 1;
BA_ "GenSigSendType" SG_ 2026 IPC_DiagRespData5 1;
BA_ "GenSigSendType" SG_ 2026 IPC_DiagRespData6 1;
BA_ "GenSigSendType" SG_ 2026 IPC_DiagRespData7 1;
BA_ "GenSigSendType" SG_ 1666 XGW_DiagReqData0 1;
BA_ "GenSigSendType" SG_ 1666 XGW_DiagReqData1 1;
BA_ "GenSigSendType" SG_ 1666 XGW_DiagReqData2 1;
BA_ "GenSigSendType" SG_ 1666 XGW_DiagReqData3 1;
BA_ "GenSigSendType" SG_ 1666 XGW_DiagReqData4 1;
BA_ "GenSigSendType" SG_ 1666 XGW_DiagReqData5 1;
BA_ "GenSigSendType" SG_ 1666 XGW_DiagReqData6 1;
BA_ "GenSigSendType" SG_ 1666 XGW_DiagReqData7 1;
BA_ "GenSigSendType" SG_ 1538 XGW_DiagRespData0 1;
BA_ "GenSigSendType" SG_ 1538 XGW_DiagRespData1 1;
BA_ "GenSigSendType" SG_ 1538 XGW_DiagRespData2 1;
BA_ "GenSigSendType" SG_ 1538 XGW_DiagRespData3 1;
BA_ "GenSigSendType" SG_ 1538 XGW_DiagRespData4 1;
BA_ "GenSigSendType" SG_ 1538 XGW_DiagRespData5 1;
BA_ "GenSigSendType" SG_ 1538 XGW_DiagRespData6 1;
BA_ "GenSigSendType" SG_ 1538 XGW_DiagRespData7 1;
BA_ "GenSigSendType" SG_ 2019 CCU_DiagReqData0 1;
BA_ "GenSigSendType" SG_ 2019 CCU_DiagReqData1 1;
BA_ "GenSigSendType" SG_ 2019 CCU_DiagReqData2 1;
BA_ "GenSigSendType" SG_ 2019 CCU_DiagReqData3 1;
BA_ "GenSigSendType" SG_ 2019 CCU_DiagReqData4 1;
BA_ "GenSigSendType" SG_ 2019 CCU_DiagReqData5 1;
BA_ "GenSigSendType" SG_ 2019 CCU_DiagReqData6 1;
BA_ "GenSigSendType" SG_ 2019 CCU_DiagReqData7 1;
BA_ "GenSigSendType" SG_ 2027 CCU_DiagRespData0 1;
BA_ "GenSigSendType" SG_ 2027 CCU_DiagRespData1 1;
BA_ "GenSigSendType" SG_ 2027 CCU_DiagRespData2 1;
BA_ "GenSigSendType" SG_ 2027 CCU_DiagRespData3 1;
BA_ "GenSigSendType" SG_ 2027 CCU_DiagRespData4 1;
BA_ "GenSigSendType" SG_ 2027 CCU_DiagRespData5 1;
BA_ "GenSigSendType" SG_ 2027 CCU_DiagRespData6 1;
BA_ "GenSigSendType" SG_ 2027 CCU_DiagRespData7 1;
BA_ "GenSigSendType" SG_ 1672 ACM_DiagReqData0 1;
BA_ "GenSigSendType" SG_ 1672 ACM_DiagReqData1 1;
BA_ "GenSigSendType" SG_ 1672 ACM_DiagReqData2 1;
BA_ "GenSigSendType" SG_ 1672 ACM_DiagReqData3 1;
BA_ "GenSigSendType" SG_ 1672 ACM_DiagReqData4 1;
BA_ "GenSigSendType" SG_ 1672 ACM_DiagReqData5 1;
BA_ "GenSigSendType" SG_ 1672 ACM_DiagReqData6 1;
BA_ "GenSigSendType" SG_ 1672 ACM_DiagReqData7 1;
BA_ "GenSigSendType" SG_ 1544 ACM_DiagRespData0 1;
BA_ "GenSigSendType" SG_ 1544 ACM_DiagRespData1 1;
BA_ "GenSigSendType" SG_ 1544 ACM_DiagRespData2 1;
BA_ "GenSigSendType" SG_ 1544 ACM_DiagRespData3 1;
BA_ "GenSigSendType" SG_ 1544 ACM_DiagRespData4 1;
BA_ "GenSigSendType" SG_ 1544 ACM_DiagRespData5 1;
BA_ "GenSigSendType" SG_ 1544 ACM_DiagRespData6 1;
BA_ "GenSigSendType" SG_ 1544 ACM_DiagRespData7 1;
BA_ "GenSigSendType" SG_ 1665 BCM_DiagReqData0 1;
BA_ "GenSigSendType" SG_ 1665 BCM_DiagReqData1 1;
BA_ "GenSigSendType" SG_ 1665 BCM_DiagReqData2 1;
BA_ "GenSigSendType" SG_ 1665 BCM_DiagReqData3 1;
BA_ "GenSigSendType" SG_ 1665 BCM_DiagReqData4 1;
BA_ "GenSigSendType" SG_ 1665 BCM_DiagReqData5 1;
BA_ "GenSigSendType" SG_ 1665 BCM_DiagReqData6 1;
BA_ "GenSigSendType" SG_ 1665 BCM_DiagReqData7 1;
BA_ "GenSigSendType" SG_ 1537 BCM_DiagRespData0 1;
BA_ "GenSigSendType" SG_ 1537 BCM_DiagRespData1 1;
BA_ "GenSigSendType" SG_ 1537 BCM_DiagRespData2 1;
BA_ "GenSigSendType" SG_ 1537 BCM_DiagRespData3 1;
BA_ "GenSigSendType" SG_ 1537 BCM_DiagRespData4 1;
BA_ "GenSigSendType" SG_ 1537 BCM_DiagRespData5 1;
BA_ "GenSigSendType" SG_ 1537 BCM_DiagRespData6 1;
BA_ "GenSigSendType" SG_ 1537 BCM_DiagRespData7 1;
BA_ "GenSigSendType" SG_ 1728 BSD_DiagReq_Data0 1;
BA_ "GenSigSendType" SG_ 1728 BSD_DiagReq_Data1 1;
BA_ "GenSigSendType" SG_ 1728 BSD_DiagReq_Data2 1;
BA_ "GenSigSendType" SG_ 1728 BSD_DiagReq_Data3 1;
BA_ "GenSigSendType" SG_ 1728 BSD_DiagReq_Data4 1;
BA_ "GenSigSendType" SG_ 1728 BSD_DiagReq_Data5 1;
BA_ "GenSigSendType" SG_ 1728 BSD_DiagReq_Data6 1;
BA_ "GenSigSendType" SG_ 1728 BSD_DiagReq_Data7 1;
BA_ "GenSigSendType" SG_ 1600 BSD_DiagResp_Data0 1;
BA_ "GenSigSendType" SG_ 1600 BSD_DiagResp_Data1 1;
BA_ "GenSigSendType" SG_ 1600 BSD_DiagResp_Data2 1;
BA_ "GenSigSendType" SG_ 1600 BSD_DiagResp_Data3 1;
BA_ "GenSigSendType" SG_ 1600 BSD_DiagResp_Data4 1;
BA_ "GenSigSendType" SG_ 1600 BSD_DiagResp_Data5 1;
BA_ "GenSigSendType" SG_ 1600 BSD_DiagResp_Data6 1;
BA_ "GenSigSendType" SG_ 1600 BSD_DiagResp_Data7 1;
BA_ "GenSigSendType" SG_ 2030 GW_DiagFunctionalAddressingData0 1;
BA_ "GenSigSendType" SG_ 2030 GW_DiagFunctionalAddressingData1 1;
BA_ "GenSigSendType" SG_ 2030 GW_DiagFunctionalAddressingData2 1;
BA_ "GenSigSendType" SG_ 2030 GW_DiagFunctionalAddressingData3 1;
BA_ "GenSigSendType" SG_ 2030 GW_DiagFunctionalAddressingData4 1;
BA_ "GenSigSendType" SG_ 2030 GW_DiagFunctionalAddressingData5 1;
BA_ "GenSigSendType" SG_ 2030 GW_DiagFunctionalAddressingData6 1;
BA_ "GenSigSendType" SG_ 2030 GW_DiagFunctionalAddressingData7 1;
VAL_ 261 Rolling_Counter_0x105 15 "Invalid" ;
VAL_ 261 BCM_STAT_TrunkAjar 3 "Signal invalid" 2 "Reserved" 1 "Opened" 0 "Closed" ;
VAL_ 261 BCM_STAT_DoorAjarDriver 3 "Signal invalid" 2 "Reserved" 1 "Opened" 0 "Closed" ;
VAL_ 261 BCM_STAT_DoorAjarPassenger 3 "Signal invalid" 2 "Reserved" 1 "Opened" 0 "Closed" ;
VAL_ 261 BCM_STAT_DoorAjarRL 3 "Signal invalid" 2 "Reserved" 1 "Opened" 0 "Closed" ;
VAL_ 261 BCM_STAT_DoorAjarRR 3 "Signal invalid" 2 "Reserved" 1 "Opened" 0 "Closed" ;
VAL_ 261 BCM_STAT_BonnetAjar_reserved 3 "Signal invalid" 2 "Reserved" 1 "Opened" 0 "Closed" ;
VAL_ 262 Rolling_Counter_0x106 15 "Invalid" ;
VAL_ 262 BCM_HighBeamSts 0 "OFF" 1 "ON" 2 "Fault (Reserved)" 3 "Signal Invalid" ;
VAL_ 262 BCM_LowBeamSts 0 "OFF" 1 "ON" 2 "Fault (Reserved)" 3 "Signal Invalid" ;
VAL_ 262 BCM_PosLmpSts 0 "OFF" 1 "ON" 2 "Fault (Reserved)" 3 "Signal Invalid" ;
VAL_ 262 BCM_TurnIndicatorSts 0 "OFF" 1 "Left On" 2 "Right On" 3 "Left and Right On" ;
VAL_ 262 BCM_DayRunningLampSts_reserved 0 "OFF" 1 "ON" 2 "Fault (Reserved)" 3 "Signal Invalid" ;
VAL_ 262 BCM_ReverseLightSts 0 "OFF" 1 "ON" 2 "Fault (Reserved)" 3 "Signal Invalid" ;
VAL_ 262 BCM_StopLightSts 0 "OFF" 1 "ON" 2 "Fault (Reserved)" 3 "Signal Invalid" ;
VAL_ 262 BCM_Fr_Dimming_dome_lampSts 0 "OFF" 1 "ON" 2 "Fault (Reserved)" 3 "Signal Invalid" ;
VAL_ 262 BCM_Heated_rearglass 0 "OFF" 1 "ON" 2 "Fault (Reserved)" 3 "Signal Invalid" ;
VAL_ 262 BCM_BsdLightSts 0 "OFF" 1 "Left On" 2 "Right On" 3 "Left and Right On" ;
VAL_ 262 BCM_STAT_LightActivation 7 "Signal invalid" 6 "Reserved" 5 "Reserved" 4 "Reserved" 3 "AutoLight" 2 "LowBeam" 1 "PositionLight" 0 "OFF" ;
VAL_ 262 BCM_STAT_InteriorLight 3 "Signal invalid" 2 "Reserved" 1 "ON" 0 "OFF" ;
VAL_ 266 Rolling_Counter_0x10a 15 "Invalid" ;
VAL_ 266 BCM_LVTop_up 1 "start Top up" 0 "stop Top up" ;
VAL_ 274 Rolling_Counter_0x112 15 "Invalid" ;
VAL_ 274 STAT_Terminal 7 "Signal invalid" 6 "Reserved" 5 "Reserved" 4 "SW update OTA (Not used in VFe34)" 3 "Engine start (eMotor running)" 2 "ON (Driver Present)" 1 "ACC (Park)" 0 "OFF(Comfort Enable)" ;
VAL_ 274 STAT_CL30s_L_Reserved 3 "Signal invalid" 2 "Failure" 1 "ON" 0 "OFF" ;
VAL_ 303 Rolling_Counter_0x12f 15 "Invalid" ;
VAL_ 303 ST_KL_KEY_VLD 15 "Signal invalid" 14 "Error" 13 "Reserved" 12 "Reserved" 11 "Reserved" 10 "Reserved" 9 "Reserved" 8 "Reserved" 7 "Reserved" 6 "Reserved" 5 "Key 10sec delay" 4 "Key valid IR" 3 "Key valid AR" 2 "Key search activ" 1 "Key invalid" 0 "Init" ;
VAL_ 303 ST_SSP 3 "Signal invalid" 2 "Reserve" 1 "SSB pressed" 0 "SSB not pressed" ;
VAL_ 303 BCM_IMMO_Sts 2 "failed " 1 "pass " 0 "init" ;
VAL_ 283 BCM_ACCRelayOutputSts 0 "Inactive" 1 "Active" 2 "Reserved" 3 "Signal Invalid" ;
VAL_ 283 BCM_IGN1RelayOutputSts 0 "Inactive" 1 "Active" 2 "Reserved" 3 "Signal Invalid" ;
VAL_ 283 BCM_ACCRelayFalutSts 0 "No Fault" 1 "Fault" 2 "Reserved" 3 "Signal Invalid" ;
VAL_ 283 BCM_IGN1RelayFalutSts 0 "No Fault" 1 "Fault" 2 "Reserved" 3 "Signal Invalid" ;
VAL_ 283 BCM_KEY_MatchSts 0 "No Match" 1 "Match Success" 2 "Match Failed" 3 "Matching" ;
VAL_ 529 PEPS_Lock_IGNNotOff_Alert 1 "Active" 0 "Inactive" ;
VAL_ 529 PEPS_CID_NotInside_Alert 1 "Active" 0 "Inactive" ;
VAL_ 529 PEPS_CID_Left_Alert 1 "Active" 0 "Inactive" ;
VAL_ 529 PEPS_RMKey_BatteryLow_Alert 1 "Active" 0 "Inactive" ;
VAL_ 529 PEPS_PressBrakePedal_Alert 1 "Active" 0 "Inactive" ;
VAL_ 529 PEPS_Shift_Position_Alert 1 "Active" 0 "Inactive" ;
VAL_ 529 PEPS_Lock_KeyInside_Alert 1 "Active" 0 "Inactive" ;
VAL_ 529 PEPS_EmergencyStop_Reserved 3 "Invalid" 2 "Reserved" 1 "EmergencyStopMode" 0 "Normal" ;
VAL_ 529 PEPS_CID_NotIndenfied_Alert 1 "Active" 0 "InActive" ;
VAL_ 529 BCM_Positionlight_reminder 0 "Inactive" 1 "Active" 2 "Reserved" 3 "Signal Invalid" ;
VAL_ 270 RemoteAccessKey 15 "Invalid" 8 "Panic alarm press" 7 "Panic alarm long press" 6 "Long press unlock" 5 "Long press lock" 4 "Tailgate unlock" 3 "Tailgate unlock long press" 2 "Unlock" 1 "Lock" 0 "No command" ;
VAL_ 270 PassiveAccessTrunk 3 "Signal invalid" 2 "Reserved" 1 "Pressed" 0 "Not pressed" ;
VAL_ 270 BCM_CurrentValid_FOB 0 "No Valid FOB" 1 "FOB_1" 2 "FOB_2" 3 "FOB_3" 4 "FOB_4" 5 "Reserved" 6 "Reserved" 7 "Reserved" ;
VAL_ 1053 BCM_STAT_RemoteLockFeedback 7 "Signal invalid" 6 "Reserved" 5 "Reserved" 4 "Inactive" 3 "Horn Only" 2 "Lights Only" 1 "Lights and Horn" 0 "OFF" ;
VAL_ 1053 BCM_STAT_RemoteDoorUnlock_reserv 3 "Signal invalid" 2 "All doors" 1 "Driver door" 0 "Reserved" ;
VAL_ 1053 BCM_STAT_AutoDoorUnlock 3 "Signal invalid" 2 "Reserved" 1 "ON" 0 "OFF" ;
VAL_ 1053 BCM_STAT_DoorSpeedLock 7 "Signal invalid" 5 "25KMH" 4 "20KMH" 3 "15KMH" 2 "10KMH" 1 "5KMH" 0 "OFF" ;
VAL_ 1053 BCM_STAT_DayTimeRunningLight_res 3 "Signal invalid" 2 "Reserved" 1 "ON" 0 "OFF" ;
VAL_ 1053 BCM_STAT_AntiTheftMode 7 "Signal invalid" 3 "Light and Horn" 2 "Horn Only" 1 "Light Only" 0 "OFF" ;
VAL_ 1053 BCM_FOBID_userprofile_link 5 "Searching" 4 "No key found" 3 "key illegal" 2 "Fob2" 1 "Fob1" 0 "No trigger from MHU" ;
VAL_ 1053 BCM_feedback_FollowMeHomeTime 4 "120s" 3 "90s" 2 "60s" 1 "30s" 0 "OFF" ;
VAL_ 263 Rolling_Counter_0x107 15 "Invalid" ;
VAL_ 263 STAT_ATWS 7 "Signal invalid" 6 "Reserved" 5 "Reserved" 4 "Security Failure" 3 "Partly secured" 2 "Alarm" 1 "Unsecured" 0 "Secured" ;
VAL_ 263 STAT_DoorLockDriver 3 "Signal invalid" 2 "Reserved" 1 "Locked" 0 "Unlocked" ;
VAL_ 268 Rolling_Counter_0x10C 15 "Invalid" ;
VAL_ 268 BCM_TboxAuthStatus 0 "Have not learn. Not allow action" 1 "PASSED" 2 "FALIED: Authentication fail" 3 "Invalid" ;
VAL_ 272 Rolling_Counter_0x110 15 "Invalid" ;
VAL_ 272 BCM_APM_FLWIN_Postion 7 "Reserved" 6 "closing" 5 "opening" 4 "Open-80%（Bottom to 80%）" 3 "80%-Close(80% to Top) " 2 "Open(Bottom) " 1 "Closed(Top)" 0 "NotActive" ;
VAL_ 272 BCM_APM_FRWIN_Postion 7 "Reserved" 6 "closing " 5 "opening" 4 "Open-80%（Bottom to 80%）" 3 "80%-Close(80% to Top) " 2 "Open(Bottom) " 1 "Closed(Top)" 0 "NotActive" ;
VAL_ 272 BCM_APM_RLWIN_Postion 7 "Reserved" 6 "closing " 5 "opening" 4 "Open-80%（Bottom to 80%）" 3 "80%-Close(80% to Top) " 2 "Open(Bottom) " 1 "Closed(Top)" 0 "NotActive" ;
VAL_ 272 BCM_APM_RRWIN_Postion 7 "Reserved" 6 "closing " 5 "opening" 4 "Open-80%（Bottom to 80%）" 3 "80%-Close(80% to Top) " 2 "Open(Bottom) " 1 "Closed(Top)" 0 "NotActive" ;
VAL_ 272 APM_Status 1 "Error" 0 "No Error" ;
VAL_ 272 ChildProtectionStatus 3 "Invaild" 2 "Reserved" 1 "ON" 0 "OFF" ;
VAL_ 272 APM_Window_DriveSW_FL_Status 5 "Reserved" 4 "Auto up" 3 "Manual up " 2 "OFF " 1 "Manual down" 0 "Auto down" ;
VAL_ 272 APM_Window_DriveSW_FR_Status 7 "Reserved" 6 "Reserved" 5 "Reserved" 4 "Manual up (Reserved Auto up)" 3 "Manual up " 2 "OFF " 1 "Manual down" 0 "Auto down" ;
VAL_ 272 APM_Window_DriveSW_RL_Status 7 "Reserved" 6 "Reserved" 5 "Reserved" 4 "Manual up (Reserved Auto up)" 3 "Manual up " 2 "OFF " 1 "Manual down" 0 "Auto down" ;
VAL_ 272 APM_Window_DriveSW_RR_Status 7 "Reserved" 6 "Reserved" 5 "Reserved" 4 "Manual up (Reserved Auto up)" 3 "Manual up " 2 "OFF " 1 "Manual down" 0 "Auto down" ;
VAL_ 272 APM_Window_PassengerSW_Status 7 "Reserved" 6 "Reserved" 5 "Reserved" 4 "Manual up (Reserved Auto up)" 3 "Manual up " 2 "OFF " 1 "Manual down" 0 "Auto down" ;
VAL_ 272 APM_Window_PassengerSW_RL_Status 7 "Reserved" 6 "Reserved" 5 "Reserved" 4 "Manual up (Reserved Auto up)" 3 "Manual up " 2 "OFF " 1 "Manual down" 0 "Auto down" ;
VAL_ 272 APM_Window_PassengerSW_RR_Status 7 "Reserved" 6 "Reserved" 5 "Reserved" 4 "Manual up (Reserved Auto up)" 3 "Manual up " 2 "OFF " 1 "Manual down" 0 "Auto down" ;
VAL_ 525 Rolling_Counter_0x20D 15 "Invalid" ;
VAL_ 525 BCM_ODO 1048575 "Invalid" ;
VAL_ 834 Rolling_Counter_0x342 15 "Invalid" ;
VAL_ 834 ABS_LRWhlSpdRaw 32767 "Invalid" ;
VAL_ 834 ABS_LRWhlSpdRawValid 1 "Valid" 0 "Invalid" ;
VAL_ 834 ABS_RRWhlSpdRaw 32767 "Invalid" ;
VAL_ 834 ABS_RRWhlSpdRawValid 1 "Valid" 0 "Invalid" ;
VAL_ 834 ABS_VehSpd 32767 "Invalid" ;
VAL_ 834 ABS_VehSpdValid 1 "Valid" 0 "Invalid" ;
VAL_ 306 RollingCounter_0x132 15 "Invalid" ;
VAL_ 306 ESC_HSA_Control_Status 1 "active" 0 "inactive" ;
VAL_ 306 ESC_HSA_Status_Fault 1 " HSA Defective" 0 "HSA Normale" ;
VAL_ 306 ESC_TcsDisableSts 3 "signal invalid" 2 "reservred" 1 "disabled" 0 "enabled" ;
VAL_ 306 ESC_TcsCtrlActv 1 "active" 0 "inactive" ;
VAL_ 306 ESC_TcsFlgFlt 1 "failure" 0 "no failure" ;
VAL_ 306 ESC_EscDisableSts 1 "disabled" 0 "enabled" ;
VAL_ 306 ESC_EscCtrlActv 1 "active" 0 "inactive" ;
VAL_ 306 ESC_EscFlgFlt 1 "failure" 0 "no failure" ;
VAL_ 306 ESC_HBAFlgFlt 1 "failure" 0 "no failure" ;
VAL_ 306 ESC_HbaCtrlActv 1 "active" 0 "inactive" ;
VAL_ 306 ESC_SlopeGradeAngle 255 "Invalid" ;
VAL_ 306 ESC_MasterCylinderPressure 4095 "Invalid" ;
VAL_ 322 RollingCounter_0x142 15 "Invalid" ;
VAL_ 322 AbsDiagSessionLampReq_Reserved 1 "lamp on" 0 "lamp off" ;
VAL_ 322 ABS_AbsCtrlActv 1 "active" 0 "inactive" ;
VAL_ 322 ABS_EbdFlgFlt 1 "failure" 0 "no failure" ;
VAL_ 322 ABS_AbsFlgFlt 1 "failure" 0 "no failure" ;
VAL_ 322 ABS_ESS_Active 1 "active" 0 "inactive" ;
VAL_ 322 ABS_LowBrakeFluid 1 "failure" 0 "no failure" ;
VAL_ 994 RollingCounter_0x3E2 15 "Invalid" ;
VAL_ 994 ESC_LateralACC 255 "Invalid" ;
VAL_ 994 ESC_LateralACC_Valid 1 "Valid" 0 "Invalid" ;
VAL_ 994 ESC_LongitudeACC 1023 "Invalid" ;
VAL_ 994 ESC_LongitudeACC_Valid 1 "Valid" 0 "Invalid" ;
VAL_ 994 ESC_VehDynYawRate 16383 "Invalid" ;
VAL_ 994 ESC_VehDynYawRate_Valid 1 "Valid" 0 "Invalid" ;
VAL_ 1154 ESC_FLTirePressAlarm 1 "Pressure warning" 0 "No warning" ;
VAL_ 1154 ESC_FRTirePressAlarm 1 "Pressure warning" 0 "No warning" ;
VAL_ 1154 ESC_RLTirePressAlarm 1 "Pressure warning" 0 "No warning" ;
VAL_ 1154 ESC_RRTirePressAlarm 1 "Pressure warning" 0 "No warning" ;
VAL_ 1154 ESC_iTPMS_Err 1 "Error" 0 "No error" ;
VAL_ 1154 ESC_iTPMS_WarnLampAct 1 "Active" 0 "Inactive" ;
VAL_ 1154 ESC_iTPMSResetProhibit 3 "prohibit 3 (System error)" 2 "prohibit 2 (Vehicle speed >0 km/h)" 1 "prohibit 1 (Tire statue is changing)" 0 "Not prohibit" ;
VAL_ 1154 ESC_iTPMSResetSts 4 "Reset fail" 3 "Reset finish" 2 "Reset ongoing" 1 "Reset start" 0 "Idle" ;
VAL_ 496 SAS_SteerWheelAngle 65535 "Invalid" ;
VAL_ 496 SAS_SteeringAngleValid 1 "Valid" 0 "Invalid" ;
VAL_ 496 SAS_SASStsSnsr 1 "sensor value valid" 0 "sensor value Invalid" ;
VAL_ 496 SAS_SteerWhlRotSpd 16383 "Invalid" ;
VAL_ 496 SAS_SteerWhlRotSpdStatus 1 "Valid" 0 "Invalid" ;
VAL_ 496 SAS_SASFailure 1 "No Failure" 0 "Failure" ;
VAL_ 496 EPS_EpsFailed 1 "failed" 0 "not failed" ;
VAL_ 673 Rolling_Counter_0x2A1 15 "Invalid" ;
VAL_ 673 ODS_Status 3 "Reserved" 2 "ODS disconnected" 1 "Seat Occupied" 0 "Seat Not Occupied" ;
VAL_ 673 EVCC_MHU_CharSchSetFeedBack 3 "invalid " 2 "No Schedule" 1 "Schedule Success" 0 "No action" ;
VAL_ 673 EVCC_ChargeGunSts 1 "Plug In" 0 "no Plug in" ;
VAL_ 673 EVCC_ChargeMode 2 "DC Mode " 1 "AC Mode " 0 "Default" ;
VAL_ 673 EVCC_CP_Sts 12 "F~" 11 "E~" 10 "D~" 9 "C~" 8 "B~" 7 "A~" 6 "F" 5 "E" 4 "D" 3 "C" 2 "B" 1 "A" 0 "No CP" ;
VAL_ 673 EVCC_PP_Value 7 "CC GND" 6 "1500" 5 "680" 4 "220" 3 "100" 2 "Connection" 1 "Half Connection " 0 "No Connection" ;
VAL_ 673 EVCC_Lock_Sts 4 "Error" 3 "Unlocking" 2 "Locked" 1 "Locking " 0 "Unlock" ;
VAL_ 792 EAC_CompElecCurrV 0 "Valid" 1 "Invalid" ;
VAL_ 792 EAC_CompStat 0 "Normal Operation" 1 "Degraded Operation" 2 "Inoperative" 15 "Invalid" ;
VAL_ 792 EAC_CompElecPwrV 0 "Valid" 1 "Invalid" ;
VAL_ 792 EAC_CompSpdIncrReq 0 "False" 1 "True" ;
VAL_ 792 EAC_CompSpdV 0 "Valid" 1 "Invalid" ;
VAL_ 792 EAC_CompElecPwr 255 "Invaild" ;
VAL_ 792 EAC_CompSpd 16383 "Invaild" ;
VAL_ 792 EAC_CompElecCurr 255 "Invaild" ;
VAL_ 792 EAC_CompFltStat 0 "No Fault" 1 "Under Voltage" 2 "Over Voltage" 3 "Over Temperature" 4 "Input Control" 5 "Current Fault" 6 "Internal Fault" 8 "Motor slip protection" 9 "HVDC input voltage drop protection" 10 "Inside the controller 15V control power supply output undervoltage protection" 11 "Overcurrent frequency limitation and frequency reduction" 15 "Invalid" ;
VAL_ 937 VCU_PTC_RelaySts 1 "close" 0 "open" ;
VAL_ 937 VCU_EACEnbReq 1 "Enable" 0 "Disable" ;
VAL_ 937 VCU_EACAllowedPower 1023 "Invalid" ;
VAL_ 937 VCU_EAC_CompSpdReq 16383 "Invaild" ;
VAL_ 889 VCU_DriveCoolWaterPumpSts 5 "Reserved" 4 "Other error" 3 "Overtemperature" 2 "Locked-rotor" 1 "Idle" 0 "Normal" ;
VAL_ 889 VCU_DriveCoolWaterDuty 127 "Invalid" ;
VAL_ 889 VCU_BatteryWaterPumpSts_reserved 5 "Reserved" 4 "Other error" 3 "Overtemperature" 2 "Locked-rotor" 1 "Idle" 0 "Normal" ;
VAL_ 889 VCU_BatteryWaterPumpDuty_reserve 127 "Invalid" ;
VAL_ 889 VCU_DriveMode 7 "Invalid" 6 "Reserved" 5 "Reserved" 4 "Reserved" 3 "Reserved" 2 "Sport mode" 1 "ECO mode" 0 "Normal mode" ;
VAL_ 889 VCU_ActualGear 7 "Fault" 6 "Reserved" 5 "Reserved" 4 "Reserved" 3 "D" 2 "N" 1 "R" 0 "P reserved" ;
VAL_ 889 VCU_ACTGearValid 1 "nvalid" 0 "Valid" ;
VAL_ 889 VCU_AccPedal1OutRange 1 "Error" 0 "Normal" ;
VAL_ 889 VCU_AccPedal2OutRange 1 "Error" 0 "Normal" ;
VAL_ 889 VCU_BrkPedal1OutRange 1 "Error" 0 "Normal" ;
VAL_ 889 VCU_BrkPedal2OutRange 1 "Error" 0 "Normal" ;
VAL_ 889 VCU_BrkPedalPct 255 "Invalid" ;
VAL_ 889 VCU_AccPedalPosition 255 "Invalid" ;
VAL_ 889 VCU_AccPedalPositionValid 1 "Invalid" 0 "Valid" ;
VAL_ 889 VCU_SocDisplay_EST 127 "Invalid" ;
VAL_ 889 VCU_PowerLimit 1 "Limit" 0 "No Limit" ;
VAL_ 889 VCU_CruiseCtrlSts 3 "takeover mode" 2 "Pre cruise(lamp flash)" 1 "Cruise on(lamp on)" 0 "Cruise off(lamp off)" ;
VAL_ 889 VCU_LowSOC_ERR 1 "Error" 0 "No Error" ;
VAL_ 425 VCU_RegenLevel_Feed 3 "invalid" 2 "High" 1 "Low" 0 "none" ;
VAL_ 425 VCU_RBCSts 1 "active" 0 "incative" ;
VAL_ 425 VCU_RDCSts 1 "active" 0 "incative" ;
VAL_ 425 VCU_Veh_ERR 1 "Error" 0 "Normal" ;
VAL_ 425 VCU_DrvSys_ERR 1 "Error" 0 "Normal" ;
VAL_ 425 VCU_PackSys_ERR 1 "Error" 0 "Normal" ;
VAL_ 425 VCU_TBOX_Veh_STS_Reserved 3 "Other" 2 "Off" 1 "Start" 0 "Invalid" ;
VAL_ 425 VCU_VehChg_STS 3 "Charge fault" 2 "Charging complete" 1 "Charging in progress" 0 "Charging not in progress" ;
VAL_ 425 VCU_BatterVoltage_Reserved 255 "Invalid" ;
VAL_ 425 VCU_BatteryVoltErr_Reserved 1 "warning" 0 "no warning" ;
VAL_ 425 VCU_MotorCoolingCircuitErr_Reser 1 "Error" 0 "Normal" ;
VAL_ 425 VCU_PackCoolingCircuitErr_Reserv 1 "Error" 0 "Normal" ;
VAL_ 425 VCU_VehicleHVStatus 3 "Reserved" 2 "ReadyToDrive" 1 "HV On" 0 "Not ready" ;
VAL_ 425 VCU_InstantPowerConsump 1023 "Invalid" ;
VAL_ 425 VCU_AveragePowerConsump 1023 "Invalid" ;
VAL_ 425 VCU_BrakePedalSts 3 "Invalid" 2 "Reserved" 1 "pressed" 0 "Not pressed" ;
VAL_ 1008 VCU_IMMO_Sts 2 "failed " 1 "pass " 0 "init" ;
VAL_ 1008 VCU_DCDCAllowedPower 511 "Invalid" ;
VAL_ 1008 VCU_Shift_ERR 1 "Error" 0 "Normal" ;
VAL_ 1008 VCU_VehicleDischargePower 127 "Invalid" ;
VAL_ 1008 VCU_VehicleChargePower 127 "Invalid" ;
VAL_ 992 Rolling_Counter_0x3E0 15 "Invalid" ;
VAL_ 992 VCU_MHU_Ack_ChgSche_stt 0 "Disabled" 1 "Enabled" 2 "Reserved" 3 "Invalid" ;
VAL_ 992 VCU_MHU_GuestMode_sts 0 "OFF" 1 "ON" 2 "Reserved" 3 "Reserved" ;
VAL_ 992 VCU_ValetMode_sts 0 "Inactive" 1 "Active" 255 "Invalid" ;
VAL_ 992 VCU_CreepDisable_stt 0 "Enable" 1 "Disable" ;
VAL_ 745 Rolling_Counter_0x2E9 15 "Invalid" ;
VAL_ 745 VCU_SetCruiseSpd 255 "Invalid" ;
VAL_ 534 Rolling_Counter_0x216 15 "Invalid" ;
VAL_ 534 BMS_RemainChargeTime 16383 "Invalid" ;
VAL_ 534 BMS_ChgVoltage_REQ 16383 "Invalid" ;
VAL_ 534 BMS_ChgCurrent_REQ 65535 "Invalid" ;
VAL_ 533 Rolling_Counter_0x215 15 "Invalid" ;
VAL_ 533 BMS_SOE 255 "Invalid" ;
VAL_ 533 BMS_HWCrash_Sts 1 "Crash " 0 "No Crash" ;
VAL_ 533 BMS_HVIL_STS 2 "short to ground" 1 "Open & short to battery" 0 "Closed" ;
VAL_ 533 BMS_IGN_Sts 1 "ON " 0 "OFF" ;
VAL_ 533 BMS_Sys_STS 8 "Invalid" 7 "Failure, unable to operate" 6 "BCU Sleep mode" 5 "Successful Power Down" 4 "Power Down process" 3 "Successful Power Down of HV" 2 "Successful High Voltage Power Up" 1 "Self-check passes, can be high-voltage" 0 "Initialization of power on, self-checking" ;
VAL_ 533 BMS_HVOnOff_STS 3 "Fail to HV on " 2 "HV On " 1 "Precharge " 0 "HV Off" ;
VAL_ 533 BMS_Balance_STS 1 "active " 0 "Inactive" ;
VAL_ 533 BMS_SocActual_EST 1023 "Invalid" ;
VAL_ 533 BMS_BatBalance_ERR 1 "normal " 0 "Error" ;
VAL_ 533 BMS_ISU_Status 3 "Level3(<100 Ohms/V)" 2 "Level2(<200 Ohms/V)" 1 "Level1 <500 Ohms/V ~ >200 Ohms/V" 0 "Normal (> 500 Ohms/V)" ;
VAL_ 533 BMS_ERR_LEV 7 "Battery locked -Reserved" 6 "Fault, needs Shutdown and Wakeup" 5 "Emergency off condition" 4 "Delayed power down with FTTI" 3 "Power down without FTTI" 2 "Limp Home" 1 " Warning (any warning in system)" 0 "No error" ;
VAL_ 533 BMS_SOH 255 "Invalid" ;
VAL_ 533 BMS_HV_Sts 4 "AC Charge" 3 "Super Fast Charge" 2 "HV ON" 1 "Precharge" 0 "HV Off" ;
VAL_ 1171 BMS_DischargeCurrent_Limited 1 "Limited" 0 "Not Limited " ;
VAL_ 1171 BMS_Warning_Flag_Reserved_07 1 "Warning" 0 "No warning" ;
VAL_ 1171 BMS_Warning_Flag_Reserved_11 1 "Warning" 0 "No warning" ;
VAL_ 1171 BMS_Warning_Flag_Reserved_10 1 "Warning" 0 "No warning" ;
VAL_ 1171 BMS_Warning_Flag_Reserved_09 1 "Warning" 0 "No warning" ;
VAL_ 1171 BMS_Warning_Flag_Reserved_13 1 "Warning" 0 "No warning" ;
VAL_ 1171 BMS_Warning_Flag_Reserved_12 1 "Warning" 0 "No warning" ;
VAL_ 1171 BMS_Warning_Flag_Reserved_06 1 "Warning" 0 "No warning" ;
VAL_ 1171 BMS_Warning_Flag_Reserved_05 1 "Warning" 0 "No warning" ;
VAL_ 1171 BMS_Warning_Flag_Reserved_04 1 "Warning" 0 "No warning" ;
VAL_ 1171 BMS_MalfunctionSts 1 "Malfunction indicator lamp ON" 0 "Malfunction indicator lamp OFF" ;
VAL_ 1171 BMS_LowBattery 2 "Extremely low level" 1 "Low level" 0 "No warning" ;
VAL_ 1171 BMS_BatteryReplacement 1 "Warning" 0 "No warning" ;
VAL_ 1171 BMS_PackTempSts 2 "Under Temperature Warning" 1 "Over Temperature Warning" 0 "No warning" ;
VAL_ 1171 BMS_ThermalRunaway 1 "Warning" 0 "No warning" ;
VAL_ 1171 Rolling_Counter_0x493 15 "Invalid" ;
VAL_ 372 Rolling_Counter_0x174 15 "Invalid" ;
VAL_ 372 BMS_PackCur_MEAS 65535 "Invalid" ;
VAL_ 374 Rolling_Counter_0x176 15 "Invalid" ;
VAL_ 374 BMS_HVLinkVol_MEAS 65535 "Invalid" ;
VAL_ 374 BMS_HVPackVol_MEAS 65535 "Invalid" ;
VAL_ 523 Rolling_Counter_0x20B 15 "Invalid" ;
VAL_ 523 DCDC_Sys_STS 6 "(Off)" 5 "(Fault,Cannot work)" 3 "(Successful High Voltage Power Up)" 1 "(Self-Check passes, can be high-voltage)" 0 "(Initialization of power on, self-checking)" ;
VAL_ 523 DCDC_Voltage_Input 1023 "Invalid" ;
VAL_ 523 DCDC_Current_Input 255 "Invalid" ;
VAL_ 523 DCDC_Voltage_Output 1023 "Invalid" ;
VAL_ 523 DCDC_Current_Output 255 "Invalid" ;
VAL_ 523 DCDC_Output_STS 2 "fault" 1 "normal" 0 "stop" ;
VAL_ 523 DCDC_Temp 255 "Invalid" ;
VAL_ 504 Rolling_Counter_0x1F8 15 "Invalid" ;
VAL_ 504 EDS_output_trq_FR 65535 "Invalid" ;
VAL_ 504 EDS_output_trqValid_FR 1 "valid" 0 "invalid" ;
VAL_ 504 EDS_Spd_FR 65535 "Invalid" ;
VAL_ 504 EDS_SpdValid_FR 1 "valid" 0 "invalid" ;
VAL_ 504 EDS_MotorDriveSts_FR 3 "Invaild" 2 "regen control" 1 "Drive control" 0 "Zero control" ;
VAL_ 504 EDS_Work_STS_FR 15 "invaild" 14 "power off" 13 "Failure" 12 "after run" 11 "shut down" 5 "HVReady" 4 "normal" 3 "precharge" 2 "standby" 1 "init" 0 "default" ;
VAL_ 504 EDS_powoff_req_FR 1 "(Request high voltage power down)" 0 "(No request)" ;
VAL_ 1015 MFS_OK_Control 0 "Button not Pressed" 1 "Short Press" 2 "Long Press" 3 "Signal invalid" ;
VAL_ 1015 MFS_SourseControl 0 "Button not Pressed" 1 "Short Press" 2 "Long Press" 3 "Signal invalid" ;
VAL_ 1015 MFS_VoiceRecognitionOn_Off 0 "Button not Pressed" 1 "Short Press" 2 "Long Press" 3 "Signal invalid" ;
VAL_ 1015 MFS_TelephoneCall_EndCall 0 "Button not Pressed" 1 "Short Press" 2 "Long Press" 3 "Signal invalid" ;
VAL_ 1015 MFS_DownControl 0 "Button not Pressed" 1 "Short Press" 2 "Long Press" 3 "Signal invalid" ;
VAL_ 1015 MFS_UpControl 0 "Button not Pressed" 1 "Short Press" 2 "Long Press" 3 "Signal invalid" ;
VAL_ 1015 MFS_RightControl 0 "Button not Pressed" 1 "Short Press" 2 "Long Press" 3 "Signal invalid" ;
VAL_ 1015 MFS_LeftControl 0 "Button not Pressed" 1 "Short Press" 2 "Long Press" 3 "Signal invalid" ;
VAL_ 1015 MFS_CruiseOn_Off 0 "Button not Pressed" 1 "Short Press" 2 "Long Press" 3 "Signal invalid" ;
VAL_ 1015 MFS_Failure 0 "No Error" 1 "Error" ;
VAL_ 1015 MFS_ISAControl 0 "Button not Pressed" 1 "Button Pressed" ;
VAL_ 1015 MFS_LKAControl 0 "Button not Pressed" 1 "Button Pressed" ;
VAL_ 1015 MFS_CruiseGapDecrease 0 "Button not Pressed" 1 "Short Press" 2 "Long Press" 3 "Signal invalid" ;
VAL_ 1015 MFS_CruiseSpeedDecrease 0 "Button not Pressed" 1 "Short Press" 2 "Long Press" 3 "Signal invalid" ;
VAL_ 1015 MFS_CruiseSpeedIncrease 0 "Button not Pressed" 1 "Short Press" 2 "Long Press" 3 "Signal invalid" ;
VAL_ 1015 MFS_CruiseCancel 0 " Button not Pressed " 1 "No Action" 2 "Cruise Cancel " 3 "Reserved" ;
VAL_ 1015 MFS_CruiseGapIncrease 0 "Button not Pressed" 1 "Short Press" 2 "Long Press" 3 "Signal invalid" ;
VAL_ 1017 MFS_Mode_Control 3 "Signal invalid" 2 "Long Press" 1 "Short Press" 0 "Unpress" ;
VAL_ 1017 MFS_MUTE_SPEAKER 3 "Signal invalid" 2 "Long Press" 1 "Short Press" 0 "Unpress" ;
VAL_ 1017 MFS_SONG_U 3 "Signal invalid" 2 "Long Press" 1 "Short Press" 0 "Unpress" ;
VAL_ 1017 MFS_SONG_D 3 "Signal invalid" 2 "Long Press" 1 "Short Press" 0 "Unpress" ;
VAL_ 1017 MFS_VOL_U 3 "Signal invalid" 2 "Long Press" 1 "Short Press" 0 "Unpress" ;
VAL_ 1017 MFS_VOL_D 3 "Signal invalid" 2 "Long Press" 1 "Short Press" 0 "Unpress" ;
